VERSION ""

NS_ :

BS_:

BU_: EBS EMS

BO_ 2566742014 DM41: 22 Vector__XXX
 SG_ SPN_High4 : 133|3@1+ (1,0) [0|7] "" Vector__XXX
 SG_ SPN_High3 : 101|3@1+ (1,0) [0|7] "" Vector__XXX
 SG_ SPN_High5 : 165|3@1+ (1,0) [0|7] "" Vector__XXX
 SG_ SPN_High2 : 69|3@1+ (1,0) [0|7] "" Vector__XXX
 SG_ SPN_High1 : 37|3@1+ (1,0) [0|7] "" Vector__XXX
 SG_ SpnConversionMethod1 : 47|1@1+ (1,0) [0|1] "" Vector__XXX
 SG_ SpnConversionMethod5 : 175|1@1+ (1,0) [0|1] "" Vector__XXX
 SG_ SpnConversionMethod4 : 143|1@1+ (1,0) [0|1] "" Vector__XXX
 SG_ SpnConversionMethod3 : 111|1@1+ (1,0) [0|1] "" Vector__XXX
 SG_ SpnConversionMethod2 : 79|1@1+ (1,0) [0|1] "" Vector__XXX
 SG_ OccurenceCount5 : 168|7@1+ (1,0) [0|127] "" Vector__XXX
 SG_ OccurenceCount4 : 136|7@1+ (1,0) [0|127] "" Vector__XXX
 SG_ OccurenceCount3 : 104|7@1+ (1,0) [0|127] "" Vector__XXX
 SG_ OccurenceCount2 : 72|7@1+ (1,0) [0|127] "" Vector__XXX
 SG_ OccurenceCount1 : 40|7@1+ (1,0) [0|127] "" Vector__XXX
 SG_ FMI5 : 160|5@1+ (1,0) [0|31] "" Vector__XXX
 SG_ FMI4 : 128|5@1+ (1,0) [0|31] "" Vector__XXX
 SG_ FMI3 : 96|5@1+ (1,0) [0|31] "" Vector__XXX
 SG_ FMI2 : 64|5@1+ (1,0) [0|31] "" Vector__XXX
 SG_ FMI1 : 32|5@1+ (1,0) [0|31] "" Vector__XXX
 SG_ FlashRedStopLamp : 12|2@1+ (1,0) [0|3] "" Vector__XXX
 SG_ FlashProtectLamp : 8|2@1+ (1,0) [0|3] "" Vector__XXX
 SG_ FlashMalfuncIndicatorLamp : 14|2@1+ (1,0) [0|3] "" Vector__XXX
 SG_ FlashAmberWarningLamp : 10|2@1+ (1,0) [0|3] "" Vector__XXX
 SG_ MalfunctionIndLampStatus : 6|2@1+ (1,0) [0|3] "" Vector__XXX
 SG_ AmberWarningLampStatus : 2|2@1+ (1,0) [0|3] "" Vector__XXX
 SG_ RedStopLampState : 4|2@1+ (1,0) [0|3] "" Vector__XXX
 SG_ ProtectLampStatus : 0|2@1+ (1,0) [0|3] "" Vector__XXX
 SG_ SPN5 : 144|16@1+ (1,0) [0|524287] "" Vector__XXX
 SG_ SPN4 : 112|16@1+ (1,0) [0|524287] "" Vector__XXX
 SG_ SPN3 : 80|16@1+ (1,0) [0|524287] "" Vector__XXX
 SG_ SPN2 : 48|16@1+ (1,0) [0|524287] "" Vector__XXX
 SG_ SPN1 : 16|16@1+ (1,0) [0|524287] "" Vector__XXX

BO_ 2566742270 DM40: 20 Vector__XXX
 SG_ FailureSpecificB1Counter4 : 144|16@1+ (0.1,0) [0|6425.5] "hr" Vector__XXX
 SG_ FailureSpecificB1Counter3 : 104|16@1+ (0.1,0) [0|6425.5] "hr" Vector__XXX
 SG_ FailureSpecificB1Counter2 : 64|16@1+ (0.1,0) [0|6425.5] "hr" Vector__XXX
 SG_ SPN4_High : 141|3@1+ (1,0) [0|7] "" Vector__XXX
 SG_ SPN3_High : 101|3@1+ (1,0) [0|7] "" Vector__XXX
 SG_ SPN2_High : 61|3@1+ (1,0) [0|7] "" Vector__XXX
 SG_ SPN4 : 120|16@1+ (1,0) [0|65536] "" Vector__XXX
 SG_ SPN3 : 80|16@1+ (1,0) [0|65536] "" Vector__XXX
 SG_ SPN2 : 40|16@1+ (1,0) [0|65536] "" Vector__XXX
 SG_ FMI4 : 136|5@1+ (1,0) [0|0] "" Vector__XXX
 SG_ FMI3 : 96|5@1+ (1,0) [0|0] "" Vector__XXX
 SG_ FMI2 : 56|5@1+ (1,0) [0|0] "" Vector__XXX
 SG_ SPN1 : 0|16@1+ (1,0) [0|65536] "" Vector__XXX
 SG_ SPN1_High : 21|3@1+ (1,0) [0|7] "" Vector__XXX
 SG_ FMI1 : 16|5@1+ (1,0) [0|0] "" Vector__XXX
 SG_ FailureSpecificB1Counter1 : 24|16@1+ (0.1,0) [0|6425.5] "hr" Vector__XXX

BO_ 2566742526 DM39: 8 Vector__XXX
 SG_ SysGreatestB1Counter : 32|16@1+ (0.1,0) [0|6425.5] "hr" Vector__XXX
 SG_ SysCumulativeContinuousMITime : 0|32@1+ (0.05,0) [0|210554060.75] "hr" Vector__XXX

BO_ 2566742782 DM38: 8 Vector__XXX
 SG_ RegulationDescription : 0|8@1+ (1,0) [0|255] "" Vector__XXX

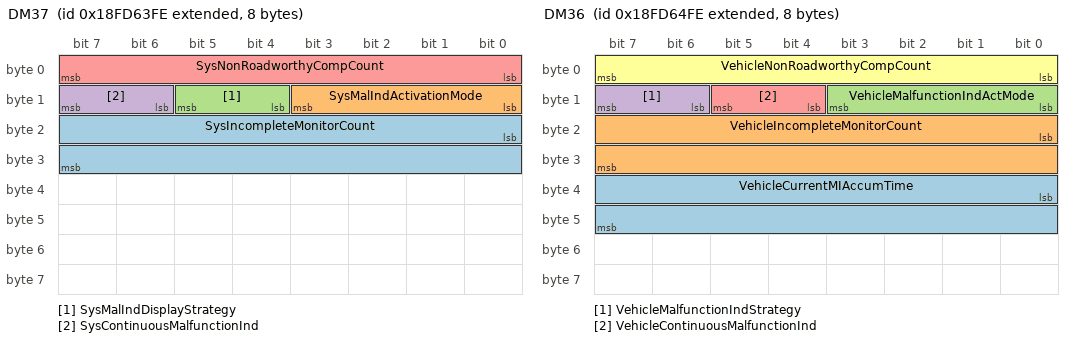
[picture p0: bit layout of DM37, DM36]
BO_ 2566743038 DM37: 8 Vector__XXX
 SG_ SysIncompleteMonitorCount : 16|16@1+ (1,0) [0|64512] "" Vector__XXX
 SG_ SysMalIndActivationMode : 8|4@1+ (1,0) [0|15] "" Vector__XXX
 SG_ SysMalIndDisplayStrategy : 12|2@1+ (1,0) [0|3] "" Vector__XXX
 SG_ SysContinuousMalfunctionInd : 14|2@1+ (1,0) [0|3] "" Vector__XXX
 SG_ SysNonRoadworthyCompCount : 0|8@1+ (1,0) [0|250] "" Vector__XXX

BO_ 2566743294 DM36: 8 Vector__XXX
 SG_ VehicleCurrentMIAccumTime : 32|16@1+ (1,0) [0|64255] "min" Vector__XXX
 SG_ VehicleIncompleteMonitorCount : 16|16@1+ (1,0) [0|64255] "" Vector__XXX
 SG_ VehicleMalfunctionIndActMode : 8|4@1+ (1,0) [0|15] "" Vector__XXX
 SG_ VehicleMalfunctionIndStrategy : 14|2@1+ (1,0) [0|3] "" Vector__XXX
 SG_ VehicleContinuousMalfunctionInd : 12|2@1+ (1,0) [0|3] "" Vector__XXX
 SG_ VehicleNonRoadworthyCompCount : 0|8@1+ (1,0) [0|250] "" Vector__XXX

BO_ 2560622334 DM35: 22 Vector__XXX
 SG_ SPN_High4 : 133|3@1+ (1,0) [0|7] "" Vector__XXX
 SG_ SPN_High3 : 101|3@1+ (1,0) [0|7] "" Vector__XXX
 SG_ SPN_High5 : 165|3@1+ (1,0) [0|7] "" Vector__XXX
 SG_ SPN_High2 : 69|3@1+ (1,0) [0|7] "" Vector__XXX
 SG_ SPN_High1 : 37|3@1+ (1,0) [0|7] "" Vector__XXX
 SG_ SpnConversionMethod1 : 47|1@1+ (1,0) [0|1] "" Vector__XXX
 SG_ SpnConversionMethod5 : 175|1@1+ (1,0) [0|1] "" Vector__XXX
 SG_ SpnConversionMethod4 : 143|1@1+ (1,0) [0|1] "" Vector__XXX
 SG_ SpnConversionMethod3 : 111|1@1+ (1,0) [0|1] "" Vector__XXX
 SG_ SpnConversionMethod2 : 79|1@1+ (1,0) [0|1] "" Vector__XXX
 SG_ OccurenceCount5 : 168|7@1+ (1,0) [0|127] "" Vector__XXX
 SG_ OccurenceCount4 : 136|7@1+ (1,0) [0|127] "" Vector__XXX
 SG_ OccurenceCount3 : 104|7@1+ (1,0) [0|127] "" Vector__XXX
 SG_ OccurenceCount2 : 72|7@1+ (1,0) [0|127] "" Vector__XXX
 SG_ OccurenceCount1 : 40|7@1+ (1,0) [0|127] "" Vector__XXX
 SG_ FMI5 : 160|5@1+ (1,0) [0|31] "" Vector__XXX
 SG_ FMI4 : 128|5@1+ (1,0) [0|31] "" Vector__XXX
 SG_ FMI3 : 96|5@1+ (1,0) [0|31] "" Vector__XXX
 SG_ FMI2 : 64|5@1+ (1,0) [0|31] "" Vector__XXX
 SG_ FMI1 : 32|5@1+ (1,0) [0|31] "" Vector__XXX
 SG_ FlashRedStopLamp : 12|2@1+ (1,0) [0|3] "" Vector__XXX
 SG_ FlashProtectLamp : 8|2@1+ (1,0) [0|3] "" Vector__XXX
 SG_ FlashMalfuncIndicatorLamp : 14|2@1+ (1,0) [0|3] "" Vector__XXX
 SG_ FlashAmberWarningLamp : 10|2@1+ (1,0) [0|3] "" Vector__XXX
 SG_ MalfunctionIndLampStatus : 6|2@1+ (1,0) [0|3] "" Vector__XXX
 SG_ AmberWarningLampStatus : 2|2@1+ (1,0) [0|3] "" Vector__XXX
 SG_ RedStopLampState : 4|2@1+ (1,0) [0|3] "" Vector__XXX
 SG_ ProtectLampStatus : 0|2@1+ (1,0) [0|3] "" Vector__XXX
 SG_ SPN5 : 144|16@1+ (1,0) [0|524287] "" Vector__XXX
 SG_ SPN4 : 112|16@1+ (1,0) [0|524287] "" Vector__XXX
 SG_ SPN3 : 80|16@1+ (1,0) [0|524287] "" Vector__XXX
 SG_ SPN2 : 48|16@1+ (1,0) [0|524287] "" Vector__XXX
 SG_ SPN1 : 16|16@1+ (1,0) [0|524287] "" Vector__XXX

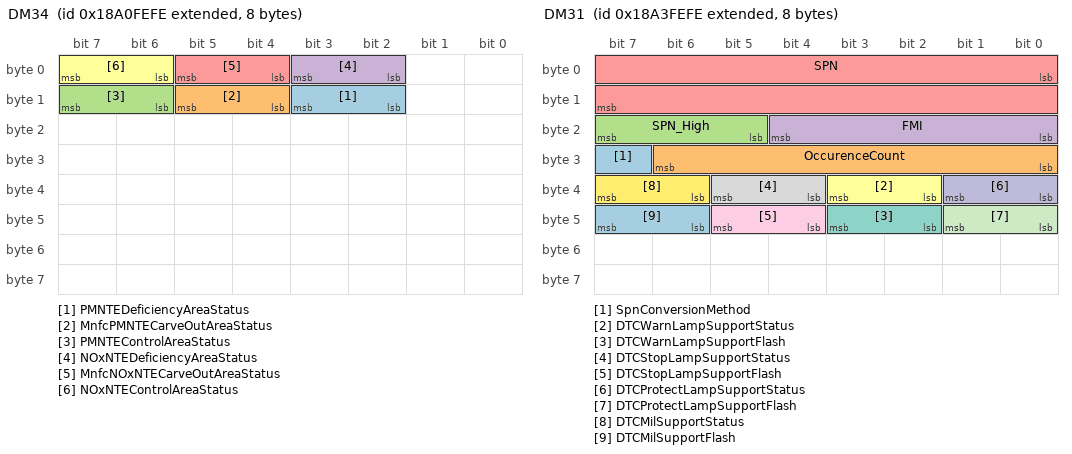
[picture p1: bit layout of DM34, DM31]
BO_ 2560687870 DM34: 8 Vector__XXX
 SG_ PMNTEDeficiencyAreaStatus : 10|2@1+ (1,0) [0|3] "" Vector__XXX
 SG_ MnfcPMNTECarveOutAreaStatus : 12|2@1+ (1,0) [0|3] "" Vector__XXX
 SG_ PMNTEControlAreaStatus : 14|2@1+ (1,0) [0|3] "" Vector__XXX
 SG_ NOxNTEDeficiencyAreaStatus : 2|2@1+ (1,0) [0|3] "" Vector__XXX
 SG_ MnfcNOxNTECarveOutAreaStatus : 4|2@1+ (1,0) [0|3] "" Vector__XXX
 SG_ NOxNTEControlAreaStatus : 6|2@1+ (1,0) [0|3] "" Vector__XXX

BO_ 2292317950 DM33: 9 Vector__XXX
 SG_ AECDEngineHours1Timer2 : 40|32@1+ (1,0) [0|4294967295] "min" Vector__XXX
 SG_ AECDEngineHours1Timer1 : 8|32@1+ (1,0) [0|4294967295] "min" Vector__XXX
 SG_ AECDNumber1 : 0|8@1+ (1,0) [0|250] "" Vector__XXX

BO_ 2560818942 DM32: 32 Vector__XXX
 SG_ DTCTotalPreviouslyActiveTime4 : 232|16@1+ (0.2,0) [0|12851] "hr" Vector__XXX
 SG_ DTCTotalPreviouslyActiveTime3 : 168|16@1+ (0.2,0) [0|12851] "hr" Vector__XXX
 SG_ DTCTotalPreviouslyActiveTime2 : 104|16@1+ (0.2,0) [0|12851] "hr" Vector__XXX
 SG_ DTCTotalActiveTime4 : 216|16@1+ (0.2,0) [0|12851] "hr" Vector__XXX
 SG_ DTCTotalActiveTime3 : 152|16@1+ (0.2,0) [0|12851] "hr" Vector__XXX
 SG_ DTCTotalActiveTime2 : 88|16@1+ (0.2,0) [0|12851] "hr" Vector__XXX
 SG_ DTCTimeUntilDerate4 : 248|8@1+ (0.25,0) [0|62.5] "hr" Vector__XXX
 SG_ DTCTimeUntilDerate3 : 184|8@1+ (0.25,0) [0|62.5] "hr" Vector__XXX
 SG_ DTCTimeUntilDerate2 : 120|8@1+ (0.25,0) [0|62.5] "hr" Vector__XXX
 SG_ SPN4_High : 213|3@1+ (1,0) [0|7] "" Vector__XXX
 SG_ SPN3_High : 149|3@1+ (1,0) [0|7] "" Vector__XXX
 SG_ SPN2_High : 85|3@1+ (1,0) [0|7] "" Vector__XXX
 SG_ SPN1_High : 21|3@1+ (1,0) [0|7] "" Vector__XXX
 SG_ SPN4 : 192|16@1+ (1,0) [0|65536] "" Vector__XXX
 SG_ SPN3 : 128|16@1+ (1,0) [0|65536] "" Vector__XXX
 SG_ SPN2 : 64|16@1+ (1,0) [0|65536] "" Vector__XXX
 SG_ FMI4 : 208|5@1+ (1,0) [0|0] "" Vector__XXX
 SG_ FMI3 : 144|5@1+ (1,0) [0|0] "" Vector__XXX
 SG_ FMI2 : 80|5@1+ (1,0) [0|0] "" Vector__XXX
 SG_ SPN1 : 0|16@1+ (1,0) [0|65536] "" Vector__XXX
 SG_ FMI1 : 16|5@1+ (1,0) [0|0] "" Vector__XXX
 SG_ DTCTimeUntilDerate1 : 56|8@1+ (0.25,0) [0|62.5] "hr" Vector__XXX
 SG_ DTCTotalPreviouslyActiveTime1 : 40|16@1+ (0.2,0) [0|12851] "hr" Vector__XXX
 SG_ DTCTotalActiveTime1 : 24|16@1+ (0.2,0) [0|12851] "hr" Vector__XXX

BO_ 2560884478 DM31: 8 Vector__XXX
 SG_ SpnConversionMethod : 31|1@1+ (1,0) [0|1] "" Vector__XXX
 SG_ OccurenceCount : 24|7@1+ (1,0) [0|127] "" Vector__XXX
 SG_ SPN_High : 21|3@1+ (1,0) [0|7] "" Vector__XXX
 SG_ FMI : 16|5@1+ (1,0) [0|31] "" Vector__XXX
 SG_ SPN : 0|16@1+ (1,0) [0|524287] "" Vector__XXX
 SG_ DTCWarnLampSupportStatus : 34|2@1+ (1,0) [0|3] "" Vector__XXX
 SG_ DTCWarnLampSupportFlash : 42|2@1+ (1,0) [0|3] "" Vector__XXX
 SG_ DTCStopLampSupportStatus : 36|2@1+ (1,0) [0|3] "" Vector__XXX
 SG_ DTCStopLampSupportFlash : 44|2@1+ (1,0) [0|3] "" Vector__XXX
 SG_ DTCProtectLampSupportStatus : 32|2@1+ (1,0) [0|3] "" Vector__XXX
 SG_ DTCProtectLampSupportFlash : 40|2@1+ (1,0) [0|3] "" Vector__XXX
 SG_ DTCMilSupportStatus : 38|2@1+ (1,0) [0|3] "" Vector__XXX
 SG_ DTCMilSupportFlash : 46|2@1+ (1,0) [0|3] "" Vector__XXX

BO_ 2560950014 DM30: 48 Vector__XXX
 SG_ TestLimitMinimum4 : 368|16@1+ (1,0) [0|64255] "" Vector__XXX
 SG_ TestLimitMinimum3 : 272|16@1+ (1,0) [0|64255] "" Vector__XXX
 SG_ TestLimitMinimum2 : 176|16@1+ (1,0) [0|64255] "" Vector__XXX
 SG_ TestLimitMaximum4 : 352|16@1+ (1,0) [0|64255] "" Vector__XXX
 SG_ TestLimitMaximum3 : 256|16@1+ (1,0) [0|64255] "" Vector__XXX
 SG_ TestLimitMaximum2 : 160|16@1+ (1,0) [0|64255] "" Vector__XXX
 SG_ TestValue4 : 336|16@1+ (1,0) [0|64255] "" Vector__XXX
 SG_ TestValue3 : 240|16@1+ (1,0) [0|64255] "" Vector__XXX
 SG_ TestValue2 : 144|16@1+ (1,0) [0|64255] "" Vector__XXX
 SG_ SlotId4 : 320|16@1+ (1,0) [0|64255] "" Vector__XXX
 SG_ SlotId3 : 224|16@1+ (1,0) [0|64255] "" Vector__XXX
 SG_ SlotId2 : 128|16@1+ (1,0) [0|64255] "" Vector__XXX
 SG_ TestIdentifier4 : 288|8@1+ (1,0) [0|255] "" Vector__XXX
 SG_ TestIdentifier3 : 192|8@1+ (1,0) [0|255] "" Vector__XXX
 SG_ TestIdentifier2 : 96|8@1+ (1,0) [0|255] "" Vector__XXX
 SG_ SPN1_High : 29|3@1+ (1,0) [0|7] "" Vector__XXX
 SG_ SPN2_High : 125|3@1+ (1,0) [0|7] "" Vector__XXX
 SG_ SPN3_High : 221|3@1+ (1,0) [0|7] "" Vector__XXX
 SG_ SPN4_High : 317|3@1+ (1,0) [0|7] "" Vector__XXX
 SG_ FMI2 : 120|5@1+ (1,0) [0|0] "" Vector__XXX
 SG_ FMI3 : 216|5@1+ (1,0) [0|0] "" Vector__XXX
 SG_ FMI4 : 312|5@1+ (1,0) [0|0] "" Vector__XXX
 SG_ FMI1 : 24|5@1+ (1,0) [0|0] "" Vector__XXX
 SG_ SPN2 : 104|16@1+ (1,0) [0|65536] "" Vector__XXX
 SG_ SPN3 : 200|16@1+ (1,0) [0|65536] "" Vector__XXX
 SG_ SPN4 : 296|16@1+ (1,0) [0|65536] "" Vector__XXX
 SG_ TestLimitMinimum1 : 80|16@1+ (1,0) [0|64255] "" Vector__XXX
 SG_ SPN1 : 8|16@1+ (1,0) [0|65536] "" Vector__XXX
 SG_ TestLimitMaximum1 : 64|16@1+ (1,0) [0|64255] "" Vector__XXX
 SG_ TestValue1 : 48|16@1+ (1,0) [0|64255] "" Vector__XXX
 SG_ SlotId1 : 32|16@1+ (1,0) [0|64255] "" Vector__XXX
 SG_ TestIdentifier1 : 0|8@1+ (1,0) [0|255] "" Vector__XXX

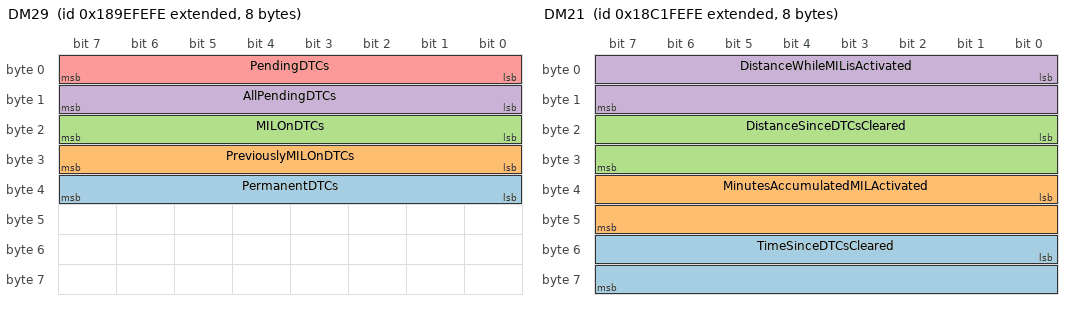
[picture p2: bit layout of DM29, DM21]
BO_ 2560556798 DM29: 8 Vector__XXX
 SG_ PermanentDTCs : 32|8@1+ (1,0) [0|255] "" Vector__XXX
 SG_ PreviouslyMILOnDTCs : 24|8@1+ (1,0) [0|255] "" Vector__XXX
 SG_ MILOnDTCs : 16|8@1+ (1,0) [0|255] "" Vector__XXX
 SG_ AllPendingDTCs : 8|8@1+ (1,0) [0|255] "" Vector__XXX
 SG_ PendingDTCs : 0|8@1+ (1,0) [0|255] "" Vector__XXX

BO_ 2566750462 DM28: 22 Vector__XXX
 SG_ SPN_High4 : 133|3@1+ (1,0) [0|7] "" Vector__XXX
 SG_ SPN_High3 : 101|3@1+ (1,0) [0|7] "" Vector__XXX
 SG_ SPN_High5 : 165|3@1+ (1,0) [0|7] "" Vector__XXX
 SG_ SPN_High2 : 69|3@1+ (1,0) [0|7] "" Vector__XXX
 SG_ SPN_High1 : 37|3@1+ (1,0) [0|7] "" Vector__XXX
 SG_ SpnConversionMethod1 : 47|1@1+ (1,0) [0|1] "" Vector__XXX
 SG_ SpnConversionMethod5 : 175|1@1+ (1,0) [0|1] "" Vector__XXX
 SG_ SpnConversionMethod4 : 143|1@1+ (1,0) [0|1] "" Vector__XXX
 SG_ SpnConversionMethod3 : 111|1@1+ (1,0) [0|1] "" Vector__XXX
 SG_ SpnConversionMethod2 : 79|1@1+ (1,0) [0|1] "" Vector__XXX
 SG_ OccurenceCount5 : 168|7@1+ (1,0) [0|127] "" Vector__XXX
 SG_ OccurenceCount4 : 136|7@1+ (1,0) [0|127] "" Vector__XXX
 SG_ OccurenceCount3 : 104|7@1+ (1,0) [0|127] "" Vector__XXX
 SG_ OccurenceCount2 : 72|7@1+ (1,0) [0|127] "" Vector__XXX
 SG_ OccurenceCount1 : 40|7@1+ (1,0) [0|127] "" Vector__XXX
 SG_ FMI5 : 160|5@1+ (1,0) [0|31] "" Vector__XXX
 SG_ FMI4 : 128|5@1+ (1,0) [0|31] "" Vector__XXX
 SG_ FMI3 : 96|5@1+ (1,0) [0|31] "" Vector__XXX
 SG_ FMI2 : 64|5@1+ (1,0) [0|31] "" Vector__XXX
 SG_ FMI1 : 32|5@1+ (1,0) [0|31] "" Vector__XXX
 SG_ FlashRedStopLamp : 12|2@1+ (1,0) [0|3] "" Vector__XXX
 SG_ FlashProtectLamp : 8|2@1+ (1,0) [0|3] "" Vector__XXX
 SG_ FlashMalfuncIndicatorLamp : 14|2@1+ (1,0) [0|3] "" Vector__XXX
 SG_ FlashAmberWarningLamp : 10|2@1+ (1,0) [0|3] "" Vector__XXX
 SG_ MalfunctionIndLampStatus : 6|2@1+ (1,0) [0|3] "" Vector__XXX
 SG_ AmberWarningLampStatus : 2|2@1+ (1,0) [0|3] "" Vector__XXX
 SG_ RedStopLampState : 4|2@1+ (1,0) [0|3] "" Vector__XXX
 SG_ ProtectLampStatus : 0|2@1+ (1,0) [0|3] "" Vector__XXX
 SG_ SPN5 : 144|16@1+ (1,0) [0|524287] "" Vector__XXX
 SG_ SPN4 : 112|16@1+ (1,0) [0|524287] "" Vector__XXX
 SG_ SPN3 : 80|16@1+ (1,0) [0|524287] "" Vector__XXX
 SG_ SPN2 : 48|16@1+ (1,0) [0|524287] "" Vector__XXX
 SG_ SPN1 : 16|16@1+ (1,0) [0|524287] "" Vector__XXX

BO_ 2566750974 DM27: 22 Vector__XXX
 SG_ SPN_High4 : 133|3@1+ (1,0) [0|7] "" Vector__XXX
 SG_ SPN_High3 : 101|3@1+ (1,0) [0|7] "" Vector__XXX
 SG_ SPN_High5 : 165|3@1+ (1,0) [0|7] "" Vector__XXX
 SG_ SPN_High2 : 69|3@1+ (1,0) [0|7] "" Vector__XXX
 SG_ SPN_High1 : 37|3@1+ (1,0) [0|7] "" Vector__XXX
 SG_ SpnConversionMethod1 : 47|1@1+ (1,0) [0|1] "" Vector__XXX
 SG_ SpnConversionMethod5 : 175|1@1+ (1,0) [0|1] "" Vector__XXX
 SG_ SpnConversionMethod4 : 143|1@1+ (1,0) [0|1] "" Vector__XXX
 SG_ SpnConversionMethod3 : 111|1@1+ (1,0) [0|1] "" Vector__XXX
 SG_ SpnConversionMethod2 : 79|1@1+ (1,0) [0|1] "" Vector__XXX
 SG_ OccurenceCount5 : 168|7@1+ (1,0) [0|127] "" Vector__XXX
 SG_ OccurenceCount4 : 136|7@1+ (1,0) [0|127] "" Vector__XXX
 SG_ OccurenceCount3 : 104|7@1+ (1,0) [0|127] "" Vector__XXX
 SG_ OccurenceCount2 : 72|7@1+ (1,0) [0|127] "" Vector__XXX
 SG_ OccurenceCount1 : 40|7@1+ (1,0) [0|127] "" Vector__XXX
 SG_ FMI5 : 160|5@1+ (1,0) [0|31] "" Vector__XXX
 SG_ FMI4 : 128|5@1+ (1,0) [0|31] "" Vector__XXX
 SG_ FMI3 : 96|5@1+ (1,0) [0|31] "" Vector__XXX
 SG_ FMI2 : 64|5@1+ (1,0) [0|31] "" Vector__XXX
 SG_ FMI1 : 32|5@1+ (1,0) [0|31] "" Vector__XXX
 SG_ FlashRedStopLamp : 12|2@1+ (1,0) [0|3] "" Vector__XXX
 SG_ FlashProtectLamp : 8|2@1+ (1,0) [0|3] "" Vector__XXX
 SG_ FlashMalfuncIndicatorLamp : 14|2@1+ (1,0) [0|3] "" Vector__XXX
 SG_ FlashAmberWarningLamp : 10|2@1+ (1,0) [0|3] "" Vector__XXX
 SG_ MalfunctionIndLampStatus : 6|2@1+ (1,0) [0|3] "" Vector__XXX
 SG_ AmberWarningLampStatus : 2|2@1+ (1,0) [0|3] "" Vector__XXX
 SG_ RedStopLampState : 4|2@1+ (1,0) [0|3] "" Vector__XXX
 SG_ ProtectLampStatus : 0|2@1+ (1,0) [0|3] "" Vector__XXX
 SG_ SPN5 : 144|16@1+ (1,0) [0|524287] "" Vector__XXX
 SG_ SPN4 : 112|16@1+ (1,0) [0|524287] "" Vector__XXX
 SG_ SPN3 : 80|16@1+ (1,0) [0|524287] "" Vector__XXX
 SG_ SPN2 : 48|16@1+ (1,0) [0|524287] "" Vector__XXX
 SG_ SPN1 : 16|16@1+ (1,0) [0|524287] "" Vector__XXX

BO_ 2566764798 DM26: 8 Vector__XXX
 SG_ NOxConvertingCatAdsorberEnabled : 43|1@1+ (1,0) [0|1] "" Vector__XXX
 SG_ BoostPressureCtrlSystemCompleted : 57|1@1+ (1,0) [0|1] "" Vector__XXX
 SG_ NMHCConvertingCatalystCompleted : 60|1@1+ (1,0) [0|1] "" Vector__XXX
 SG_ NMHCConvertingCatalystEnabled : 44|1@1+ (1,0) [0|1] "" Vector__XXX
 SG_ NOxConvertingCatalstAdsrbrCmpltd : 59|1@1+ (1,0) [0|1] "" Vector__XXX
 SG_ DieselParticulateFilterCompleted : 58|1@1+ (1,0) [0|1] "" Vector__XXX
 SG_ DieselParticulateFilterEnabled : 42|1@1+ (1,0) [0|1] "" Vector__XXX
 SG_ BoostPressureControlSystemEnable : 41|1@1+ (1,0) [0|1] "" Vector__XXX
 SG_ MisfireMonitoringComplete : 28|1@1+ (1,0) [0|1] "" Vector__XXX
 SG_ MisfireMonitoringEnabled : 24|1@1+ (1,0) [0|0] "" Vector__XXX
 SG_ FuelSystemMonitoringEnabled : 25|1@1+ (1,0) [0|1] "" Vector__XXX
 SG_ ComprehensiveComptMonComplete : 30|1@1+ (1,0) [0|1] "" Vector__XXX
 SG_ ComprehensiveCompMonEnabled : 26|1@1+ (1,0) [0|1] "" Vector__XXX
 SG_ SecondAirSystemMonComplete : 51|1@1+ (1,0) [0|1] "" Vector__XXX
 SG_ SecondAirSystemMonEnabled : 35|1@1+ (1,0) [0|1] "" Vector__XXX
 SG_ OxygenSensorMonComplete : 53|1@1+ (1,0) [0|1] "" Vector__XXX
 SG_ OxygenSensorMonEnabled : 37|1@1+ (1,0) [0|1] "" Vector__XXX
 SG_ OxygenSensorHeaterMonComplete : 54|1@1+ (1,0) [0|1] "" Vector__XXX
 SG_ OxygenSensorHeaterMonEnabled : 38|1@1+ (1,0) [0|1] "" Vector__XXX
 SG_ HeatedCatalystMonComplete : 49|1@1+ (1,0) [0|1] "" Vector__XXX
 SG_ HeatedCatalystMonEnabled : 33|1@1+ (1,0) [0|1] "" Vector__XXX
 SG_ EvaporativeSystemMonComplete : 50|1@1+ (1,0) [0|1] "" Vector__XXX
 SG_ EvaporativeSystemMonEnabled : 34|1@1+ (1,0) [0|1] "" Vector__XXX
 SG_ EGRSystemMonitoringComplete : 55|1@1+ (1,0) [0|1] "" Vector__XXX
 SG_ EGRSystemMonitoringEnabled : 39|1@1+ (1,0) [0|1] "" Vector__XXX
 SG_ ColdStartAidSystemMonComplete : 56|1@1+ (1,0) [0|1] "" Vector__XXX
 SG_ ColdStartAidSystemMonEnabled : 40|1@1+ (1,0) [0|1] "" Vector__XXX
 SG_ CatalystMonComplete : 48|1@1+ (1,0) [0|1] "" Vector__XXX
 SG_ CatalystMonEnabled : 32|1@1+ (1,0) [0|1] "" Vector__XXX
 SG_ ACSystemRefrigerantMonComplete : 52|1@1+ (1,0) [0|1] "" Vector__XXX
 SG_ ACSystemRefrigerantMonEnabled : 36|1@1+ (1,0) [0|1] "" Vector__XXX
 SG_ FuelSystemMonitoringComplete : 29|1@1+ (1,0) [0|1] "" Vector__XXX
 SG_ NumOfWarmUpsSinceDTCsCleared : 16|8@1+ (1,0) [0|250] "" Vector__XXX
 SG_ TimeSinceEngineStart : 0|16@1+ (1,0) [0|64255] "s" Vector__XXX

BO_ 2566764542 DM25: 13 Vector__XXX
 SG_ SpnConversionMethod : 39|1@1+ (1,0) [0|1] "" Vector__XXX
 SG_ OccurenceCount : 32|7@1+ (1,0) [0|127] "" Vector__XXX
 SG_ SPN_High : 29|3@1+ (1,0) [0|7] "" Vector__XXX
 SG_ FMI : 24|5@1+ (1,0) [0|31] "" Vector__XXX
 SG_ ExpandedFreezeFrameLength : 0|8@1+ (1,0) [0|250] "bytes" Vector__XXX
 SG_ SPN : 8|16@1+ (1,0) [0|524287] "" Vector__XXX

BO_ 2566764286 DM24: 12 Vector__XXX
 SG_ SPNSupported1High : 21|3@1+ (1,0) [0|7] "" Vector__XXX
 SG_ SPNSupportTypeSTR3 : 82|1@1+ (1,0) [0|1] "" Vector__XXX
 SG_ SPNSupportTypeSTR2 : 50|1@1+ (1,0) [0|1] "" Vector__XXX
 SG_ SPNSupportTypeEFF3 : 80|1@1+ (1,0) [0|1] "" Vector__XXX
 SG_ SPNSupportTypeEFF2 : 48|1@1+ (1,0) [0|1] "" Vector__XXX
 SG_ SPNSupportTypeDS3 : 81|1@1+ (1,0) [0|1] "" Vector__XXX
 SG_ SPNSupportTypeDS2 : 49|1@1+ (1,0) [0|1] "" Vector__XXX
 SG_ SPNSupported3High : 85|3@1+ (1,0) [0|7] "" Vector__XXX
 SG_ SPNSupported2High : 53|3@1+ (1,0) [0|7] "" Vector__XXX
 SG_ SPNSupported3 : 64|16@1+ (1,0) [0|65535] "" Vector__XXX
 SG_ SPNSupported2 : 32|16@1+ (1,0) [0|65535] "" Vector__XXX
 SG_ SPNDataLength3 : 88|8@1+ (1,0) [0|240] "" Vector__XXX
 SG_ SPNSupportTypeSTR1 : 18|1@1+ (1,0) [0|1] "" Vector__XXX
 SG_ SPNSupportTypeDS1 : 17|1@1+ (1,0) [0|1] "" Vector__XXX
 SG_ SPNSupportTypeEFF1 : 16|1@1+ (1,0) [0|1] "" Vector__XXX
 SG_ SPNDataLength2 : 56|8@1+ (1,0) [0|240] "" Vector__XXX
 SG_ SPNDataLength1 : 24|8@1+ (1,0) [0|250] "" Vector__XXX
 SG_ SPNSupported1 : 0|16@1+ (1,0) [0|524287] "" Vector__XXX

BO_ 2566764030 DM23: 22 Vector__XXX
 SG_ SPN_High4 : 133|3@1+ (1,0) [0|7] "" Vector__XXX
 SG_ SPN_High3 : 101|3@1+ (1,0) [0|7] "" Vector__XXX
 SG_ SPN_High5 : 165|3@1+ (1,0) [0|7] "" Vector__XXX
 SG_ SPN_High2 : 69|3@1+ (1,0) [0|7] "" Vector__XXX
 SG_ SPN_High1 : 37|3@1+ (1,0) [0|7] "" Vector__XXX
 SG_ SpnConversionMethod1 : 47|1@1+ (1,0) [0|1] "" Vector__XXX
 SG_ SpnConversionMethod5 : 175|1@1+ (1,0) [0|1] "" Vector__XXX
 SG_ SpnConversionMethod4 : 143|1@1+ (1,0) [0|1] "" Vector__XXX
 SG_ SpnConversionMethod3 : 111|1@1+ (1,0) [0|1] "" Vector__XXX
 SG_ SpnConversionMethod2 : 79|1@1+ (1,0) [0|1] "" Vector__XXX
 SG_ OccurenceCount5 : 168|7@1+ (1,0) [0|127] "" Vector__XXX
 SG_ OccurenceCount4 : 136|7@1+ (1,0) [0|127] "" Vector__XXX
 SG_ OccurenceCount3 : 104|7@1+ (1,0) [0|127] "" Vector__XXX
 SG_ OccurenceCount2 : 72|7@1+ (1,0) [0|127] "" Vector__XXX
 SG_ OccurenceCount1 : 40|7@1+ (1,0) [0|127] "" Vector__XXX
 SG_ FMI5 : 160|5@1+ (1,0) [0|31] "" Vector__XXX
 SG_ FMI4 : 128|5@1+ (1,0) [0|31] "" Vector__XXX
 SG_ FMI3 : 96|5@1+ (1,0) [0|31] "" Vector__XXX
 SG_ FMI2 : 64|5@1+ (1,0) [0|31] "" Vector__XXX
 SG_ FMI1 : 32|5@1+ (1,0) [0|31] "" Vector__XXX
 SG_ FlashRedStopLamp : 12|2@1+ (1,0) [0|3] "" Vector__XXX
 SG_ FlashProtectLamp : 8|2@1+ (1,0) [0|3] "" Vector__XXX
 SG_ FlashMalfuncIndicatorLamp : 14|2@1+ (1,0) [0|3] "" Vector__XXX
 SG_ FlashAmberWarningLamp : 10|2@1+ (1,0) [0|3] "" Vector__XXX
 SG_ MalfunctionIndLampStatus : 6|2@1+ (1,0) [0|3] "" Vector__XXX
 SG_ AmberWarningLampStatus : 2|2@1+ (1,0) [0|3] "" Vector__XXX
 SG_ RedStopLampState : 4|2@1+ (1,0) [0|3] "" Vector__XXX
 SG_ ProtectLampStatus : 0|2@1+ (1,0) [0|3] "" Vector__XXX
 SG_ SPN5 : 144|16@1+ (1,0) [0|524287] "" Vector__XXX
 SG_ SPN4 : 112|16@1+ (1,0) [0|524287] "" Vector__XXX
 SG_ SPN3 : 80|16@1+ (1,0) [0|524287] "" Vector__XXX
 SG_ SPN2 : 48|16@1+ (1,0) [0|524287] "" Vector__XXX
 SG_ SPN1 : 16|16@1+ (1,0) [0|524287] "" Vector__XXX

BO_ 2562981630 DM22: 8 Vector__XXX
 SG_ SPN : 40|16@1+ (1,0) [0|524287] "" Vector__XXX
 SG_ ControlByte M : 0|8@1+ (1,0) [0|255] "" Vector__XXX
 SG_ CtrlByteSpecificIndicator m3 : 8|8@1+ (1,0) [0|255] "" Vector__XXX
 SG_ FMI : 56|5@1+ (1,0) [0|31] "" Vector__XXX
 SG_ SPN_High : 61|3@1+ (1,0) [0|7] "" Vector__XXX

BO_ 2562850558 DM21: 8 Vector__XXX
 SG_ TimeSinceDTCsCleared : 48|16@1+ (1,0) [0|64255] "min" Vector__XXX
 SG_ MinutesAccumulatedMILActivated : 32|16@1+ (1,0) [0|64255] "min" Vector__XXX
 SG_ DistanceSinceDTCsCleared : 16|16@1+ (1,0) [0|64255] "km" Vector__XXX
 SG_ DistanceWhileMILisActivated : 0|16@1+ (1,0) [0|64255] "km" Vector__XXX

BO_ 2562916094 DM20: 11 Vector__XXX
 SG_ ApplSysMonitorDenominator : 72|16@1+ (1,0) [0|65535] "" Vector__XXX
 SG_ ApplSysMonitorNumerator : 56|16@1+ (1,0) [0|65535] "" Vector__XXX
 SG_ SpnOfApplSysMonitor : 32|19@1+ (1,0) [0|65535] "" Vector__XXX
 SG_ OBDMonitoringCondEncountered : 16|16@1+ (1,0) [0|65535] "" Vector__XXX
 SG_ IgnitionCycleCounter : 0|16@1+ (1,0) [0|65535] "" Vector__XXX

BO_ 2564030206 DM19: 20 Vector__XXX
 SG_ CalibrationID4 : 128|32@1+ (1,0) [0|4294967295] "" Vector__XXX
 SG_ CalibrationID3 : 96|32@1+ (1,0) [0|4294967295] "" Vector__XXX
 SG_ CalibrationID2 : 64|32@1+ (1,0) [0|4294967295] "" Vector__XXX
 SG_ CalibrationID1 : 32|32@1+ (1,0) [0|255] "" Vector__XXX
 SG_ CalibrationVerificationNumber : 0|32@1+ (1,0) [0|4294967295] "" Vector__XXX

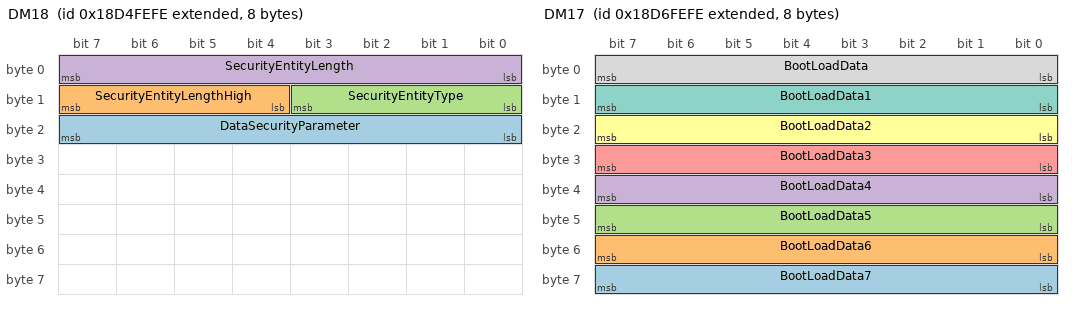
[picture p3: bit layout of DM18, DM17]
BO_ 2564095742 DM18: 8 Vector__XXX
 SG_ DataSecurityParameter : 16|8@1+ (1,0) [0|0] "" Vector__XXX
 SG_ SecurityEntityLengthHigh : 12|4@1+ (1,0) [0|255] "Byte" Vector__XXX
 SG_ SecurityEntityType : 8|4@1+ (1,0) [0|15] "" Vector__XXX
 SG_ SecurityEntityLength : 0|8@1+ (1,0) [0|4095] "" Vector__XXX

BO_ 2564226814 DM17: 8 Vector__XXX
 SG_ BootLoadData7 : 56|8@1+ (1,0) [0|255] "" Vector__XXX
 SG_ BootLoadData6 : 48|8@1+ (1,0) [0|255] "" Vector__XXX
 SG_ BootLoadData5 : 40|8@1+ (1,0) [0|255] "" Vector__XXX
 SG_ BootLoadData4 : 32|8@1+ (1,0) [0|255] "" Vector__XXX
 SG_ BootLoadData3 : 24|8@1+ (1,0) [0|255] "" Vector__XXX
 SG_ BootLoadData2 : 16|8@1+ (1,0) [0|255] "" Vector__XXX
 SG_ BootLoadData1 : 8|8@1+ (1,0) [0|255] "" Vector__XXX
 SG_ BootLoadData : 0|8@1+ (1,0) [0|0] "" Vector__XXX

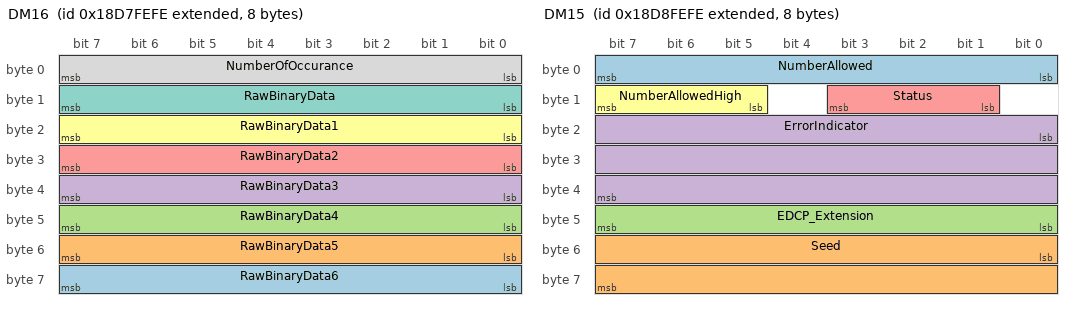
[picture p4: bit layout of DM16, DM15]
BO_ 2564292350 DM16: 8 Vector__XXX
 SG_ RawBinaryData6 : 56|8@1+ (1,0) [0|255] "" Vector__XXX
 SG_ RawBinaryData5 : 48|8@1+ (1,0) [0|255] "" Vector__XXX
 SG_ RawBinaryData4 : 40|8@1+ (1,0) [0|255] "" Vector__XXX
 SG_ RawBinaryData3 : 32|8@1+ (1,0) [0|255] "" Vector__XXX
 SG_ RawBinaryData2 : 24|8@1+ (1,0) [0|255] "" Vector__XXX
 SG_ RawBinaryData1 : 16|8@1+ (1,0) [0|255] "" Vector__XXX
 SG_ RawBinaryData : 8|8@1+ (1,0) [0|0] "" Vector__XXX
 SG_ NumberOfOccurance : 0|8@1+ (1,0) [0|255] "" Vector__XXX

BO_ 2564357886 DM15: 8 Vector__XXX
 SG_ NumberAllowed : 0|8@1+ (1,0) [0|2047] "" Vector__XXX
 SG_ Seed : 48|16@1+ (1,0) [0|65535] "" Vector__XXX
 SG_ EDCP_Extension : 40|8@1+ (1,0) [0|255] "" Vector__XXX
 SG_ ErrorIndicator : 16|24@1+ (1,0) [0|16777215] "" Vector__XXX
 SG_ Status : 9|3@1+ (1,0) [0|7] "" Vector__XXX
 SG_ NumberAllowedHigh : 13|3@1+ (1,0) [0|7] "" Vector__XXX

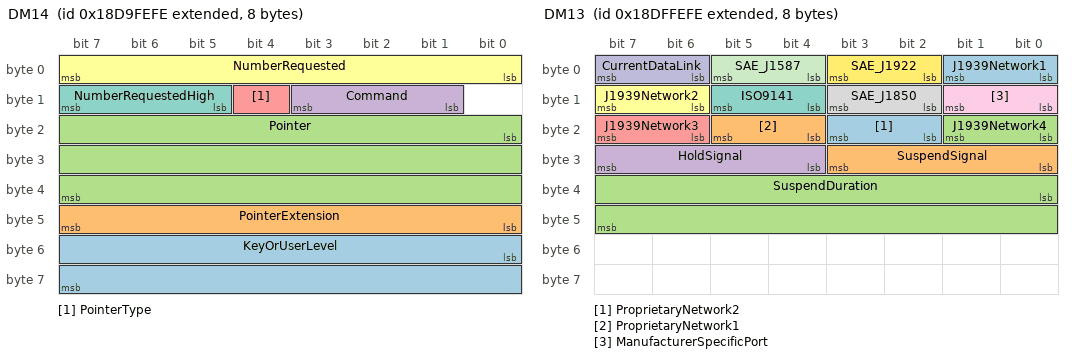
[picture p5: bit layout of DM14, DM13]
BO_ 2564423422 DM14: 8 Vector__XXX
 SG_ KeyOrUserLevel : 48|16@1+ (1,0) [0|65535] "" Vector__XXX
 SG_ PointerExtension : 40|8@1+ (1,0) [0|255] "" Vector__XXX
 SG_ Pointer : 16|24@1+ (1,0) [0|16777215] "" Vector__XXX
 SG_ Command : 9|3@1+ (1,0) [0|7] "" Vector__XXX
 SG_ PointerType : 12|1@1+ (1,0) [0|1] "" Vector__XXX
 SG_ NumberRequested : 0|8@1+ (1,0) [0|2047] "" Vector__XXX
 SG_ NumberRequestedHigh : 13|3@1+ (1,0) [0|7] "" Vector__XXX

BO_ 2564816638 DM13: 8 Vector__XXX
 SG_ ProprietaryNetwork2 : 18|2@1+ (1,0) [0|3] "" Vector__XXX
 SG_ ProprietaryNetwork1 : 20|2@1+ (1,0) [0|3] "" Vector__XXX
 SG_ J1939Network4 : 16|2@1+ (1,0) [0|3] "" Vector__XXX
 SG_ HoldSignal : 28|4@1+ (1,0) [0|15] "" Vector__XXX
 SG_ J1939Network3 : 22|2@1+ (1,0) [0|3] "" Vector__XXX
 SG_ J1939Network2 : 14|2@1+ (1,0) [0|3] "" Vector__XXX
 SG_ ISO9141 : 12|2@1+ (1,0) [0|3] "" Vector__XXX
 SG_ SAE_J1850 : 10|2@1+ (1,0) [0|3] "" Vector__XXX
 SG_ ManufacturerSpecificPort : 8|2@1+ (1,0) [0|3] "" Vector__XXX
 SG_ CurrentDataLink : 6|2@1+ (1,0) [0|3] "" Vector__XXX
 SG_ SAE_J1587 : 4|2@1+ (1,0) [0|3] "" Vector__XXX
 SG_ SAE_J1922 : 2|2@1+ (1,0) [0|3] "" Vector__XXX
 SG_ J1939Network1 : 0|2@1+ (1,0) [0|3] "" Vector__XXX
 SG_ SuspendSignal : 24|4@1+ (1,0) [0|15] "" Vector__XXX
 SG_ SuspendDuration : 32|16@1+ (1,0) [0|64255] "s" Vector__XXX

BO_ 2566837502 DM12: 22 Vector__XXX
 SG_ SPN_High4 : 133|3@1+ (1,0) [0|7] "" Vector__XXX
 SG_ SPN_High3 : 101|3@1+ (1,0) [0|7] "" Vector__XXX
 SG_ SPN_High5 : 165|3@1+ (1,0) [0|7] "" Vector__XXX
 SG_ SPN_High2 : 69|3@1+ (1,0) [0|7] "" Vector__XXX
 SG_ SPN_High1 : 37|3@1+ (1,0) [0|7] "" Vector__XXX
 SG_ SpnConversionMethod1 : 47|1@1+ (1,0) [0|1] "" Vector__XXX
 SG_ SpnConversionMethod5 : 175|1@1+ (1,0) [0|1] "" Vector__XXX
 SG_ SpnConversionMethod4 : 143|1@1+ (1,0) [0|1] "" Vector__XXX
 SG_ SpnConversionMethod3 : 111|1@1+ (1,0) [0|1] "" Vector__XXX
 SG_ SpnConversionMethod2 : 79|1@1+ (1,0) [0|1] "" Vector__XXX
 SG_ OccurenceCount5 : 168|7@1+ (1,0) [0|127] "" Vector__XXX
 SG_ OccurenceCount4 : 136|7@1+ (1,0) [0|127] "" Vector__XXX
 SG_ OccurenceCount3 : 104|7@1+ (1,0) [0|127] "" Vector__XXX
 SG_ OccurenceCount2 : 72|7@1+ (1,0) [0|127] "" Vector__XXX
 SG_ OccurenceCount1 : 40|7@1+ (1,0) [0|127] "" Vector__XXX
 SG_ FMI5 : 160|5@1+ (1,0) [0|31] "" Vector__XXX
 SG_ FMI4 : 128|5@1+ (1,0) [0|31] "" Vector__XXX
 SG_ FMI3 : 96|5@1+ (1,0) [0|31] "" Vector__XXX
 SG_ FMI2 : 64|5@1+ (1,0) [0|31] "" Vector__XXX
 SG_ FMI1 : 32|5@1+ (1,0) [0|31] "" Vector__XXX
 SG_ FlashRedStopLamp : 12|2@1+ (1,0) [0|3] "" Vector__XXX
 SG_ FlashProtectLamp : 8|2@1+ (1,0) [0|3] "" Vector__XXX
 SG_ FlashMalfuncIndicatorLamp : 14|2@1+ (1,0) [0|3] "" Vector__XXX
 SG_ FlashAmberWarningLamp : 10|2@1+ (1,0) [0|3] "" Vector__XXX
 SG_ MalfunctionIndLampStatus : 6|2@1+ (1,0) [0|3] "" Vector__XXX
 SG_ AmberWarningLampStatus : 2|2@1+ (1,0) [0|3] "" Vector__XXX
 SG_ RedStopLampState : 4|2@1+ (1,0) [0|3] "" Vector__XXX
 SG_ ProtectLampStatus : 0|2@1+ (1,0) [0|3] "" Vector__XXX
 SG_ SPN5 : 144|16@1+ (1,0) [0|524287] "" Vector__XXX
 SG_ SPN4 : 112|16@1+ (1,0) [0|524287] "" Vector__XXX
 SG_ SPN3 : 80|16@1+ (1,0) [0|524287] "" Vector__XXX
 SG_ SPN2 : 48|16@1+ (1,0) [0|524287] "" Vector__XXX
 SG_ SPN1 : 16|16@1+ (1,0) [0|524287] "" Vector__XXX

BO_ 2566837246 DM11: 0 Vector__XXX

BO_ 2566836990 DM10: 8 Vector__XXX
 SG_ TestIdentifierSupported : 0|64@1+ (1,0) [0|0] "" Vector__XXX

BO_ 2566836734 DM09: 8 Vector__XXX

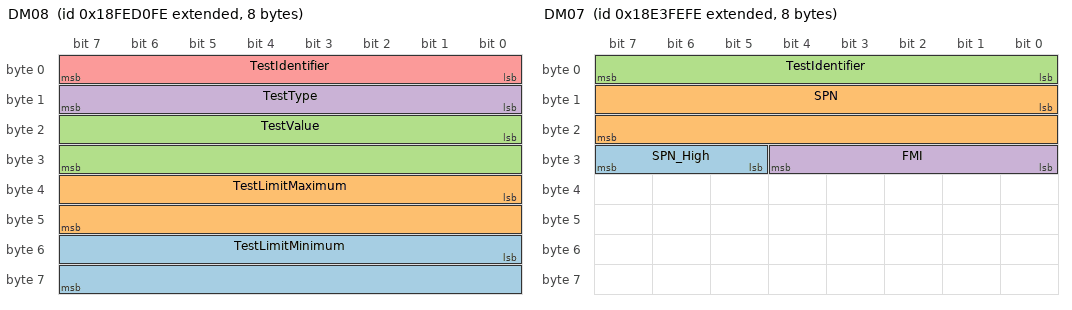
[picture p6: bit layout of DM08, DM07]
BO_ 2566836478 DM08: 8 Vector__XXX
 SG_ TestLimitMinimum : 48|16@1+ (1,0) [0|0] "" Vector__XXX
 SG_ TestLimitMaximum : 32|16@1+ (1,0) [0|0] "" Vector__XXX
 SG_ TestValue : 16|16@1+ (1,0) [0|0] "" Vector__XXX
 SG_ TestType : 8|8@1+ (1,0) [0|250] "" Vector__XXX
 SG_ TestIdentifier : 0|8@1+ (1,0) [0|255] "" Vector__XXX

BO_ 2565078782 DM07: 8 Vector__XXX
 SG_ SPN_High : 29|3@1+ (1,0) [0|7] "" Vector__XXX
 SG_ SPN : 8|16@1+ (1,0) [0|524287] "" Vector__XXX
 SG_ TestIdentifier : 0|8@1+ (1,0) [0|255] "" Vector__XXX
 SG_ FMI : 24|5@1+ (1,0) [0|31] "" Vector__XXX

CM_ BO_ 2566742014 "DTCs - A, Pending
Pending DTCs that are classified as class A severity.";
CM_ SG_ 2566742014 SPN_High4 "3 most significant bits of SPN (most significant at bit 8) ";
CM_ SG_ 2566742014 SPN_High3 "3 most significant bits of SPN (most significant at bit 8) ";
CM_ SG_ 2566742014 SPN_High5 "3 most significant bits of SPN (most significant at bit 8) ";
CM_ SG_ 2566742014 SPN_High2 "3 most significant bits of SPN (most significant at bit 8) ";
CM_ SG_ 2566742014 SPN_High1 "3 most significant bits of SPN (most significant at bit 8) ";
CM_ SG_ 2566742014 SpnConversionMethod1 "If set to '0', the document is converted according to version 4 of the J1939-73 document (February 1996); otherwise, it is converted according to one of the three earlier versions.";
CM_ SG_ 2566742014 SpnConversionMethod5 "If set to '0', the document is converted according to version 4 of the J1939-73 document (February 1996); otherwise, it is converted according to one of the three earlier versions.";
CM_ SG_ 2566742014 SpnConversionMethod4 "If set to '0', the document is converted according to version 4 of the J1939-73 document (February 1996); otherwise, it is converted according to one of the three earlier versions.";
CM_ SG_ 2566742014 SpnConversionMethod3 "If set to '0', the document is converted according to version 4 of the J1939-73 document (February 1996); otherwise, it is converted according to one of the three earlier versions.";
CM_ SG_ 2566742014 SpnConversionMethod2 "If set to '0', the document is converted according to version 4 of the J1939-73 document (February 1996); otherwise, it is converted according to one of the three earlier versions.";
CM_ SG_ 2566742014 OccurenceCount5 "Contains the number of times a fault has been independently detected.";
CM_ SG_ 2566742014 OccurenceCount4 "Contains the number of times a fault has been independently detected.";
CM_ SG_ 2566742014 OccurenceCount3 "Contains the number of times a fault has been independently detected.";
CM_ SG_ 2566742014 OccurenceCount2 "Contains the number of times a fault has been independently detected.";
CM_ SG_ 2566742014 OccurenceCount1 "Contains the number of times a fault has been independently detected.";
CM_ SG_ 2566742014 FMI5 "The FMI defines the type of failure detected in the subsystem identified by an SPN.";
CM_ SG_ 2566742014 FMI4 "The FMI defines the type of failure detected in the subsystem identified by an SPN.";
CM_ SG_ 2566742014 FMI3 "The FMI defines the type of failure detected in the subsystem identified by an SPN.";
CM_ SG_ 2566742014 FMI2 "The FMI defines the type of failure detected in the subsystem identified by an SPN.";
CM_ SG_ 2566742014 FMI1 "The FMI defines the type of failure detected in the subsystem identified by an SPN.";
CM_ SG_ 2566742014 FlashRedStopLamp "This parameter provides the capability to flash the RSL


00 - Slow Flash (1 Hz, 50 % duty cycle)
01 - Fast Flash (2 Hz or faster, 50% duty cycle)
10 - Reserved
11 - Unavailable / Do Not Flash";
CM_ SG_ 2566742014 FlashProtectLamp "This parameter provides the capability to flash the engine protect lamp


00 - Slow Flash (1 Hz, 50 % duty cycle)
01 - Fast Flash (2 Hz or faster, 50% duty cycle)
10 - Reserved
11 - Unavailable / Do Not Flash";
CM_ SG_ 2566742014 FlashMalfuncIndicatorLamp "This parameter provides the capability to flash the MIL
00 - Slow Flash (1 Hz, 50 % duty cycle)
01 - Fast Flash (2 Hz or faster, 50% duty cycle)
10 - Class C DTC
11 - Unavailable / Do Not Flash
Note:  State 10 is for WWH OBD discriminatory ...";
CM_ SG_ 2566742014 FlashAmberWarningLamp "This parameter provides the capability to flash the AWL

00 - Slow Flash (1 Hz, 50 % duty cycle)
01 - Fast Flash (2 Hz or faster, 50% duty cycle)
10 - Reserved
11 - Unavailable / Do Not Flash";
CM_ SG_ 2566742014 MalfunctionIndLampStatus "A lamp used to relay only emissions-related trouble code information. This lamp is only illuminated when there is an emission-related trouble code active.
00     Lamp Off
01     Lamp On
10     Short MIL for WWH OBD
11     Not available
Note ...";
CM_ SG_ 2566742014 AmberWarningLampStatus "This lamp is used to relay trouble code information that is reporting a problem with the vehicle system but the vehicle need not be immediately stopped. 

00     Lamp Off
01     Lamp On
10     Reserved
11     Not available";
CM_ SG_ 2566742014 RedStopLampState "This lamp is used to relay trouble code information that is of a severe enough condition that it warrants stopping the vehicle.

00     Lamp Off
01     Lamp On
10     Reserved
11     Not available";
CM_ SG_ 2566742014 ProtectLampStatus "This lamp is used to relay trouble code information that is reporting a problem with a vehicle system that is most probably not electronic subsystem related. For instance, engine coolant temperature is exceeding its prescribed temperature range.
00 ...";
CM_ SG_ 2566742014 SPN5 "16 least significant bits of SPN";
CM_ SG_ 2566742014 SPN4 "16 least significant bits of SPN";
CM_ SG_ 2566742014 SPN3 "16 least significant bits of SPN";
CM_ SG_ 2566742014 SPN2 "16 least significant bits of SPN";
CM_ SG_ 2566742014 SPN1 "16 least significant bits of SPN";
CM_ BO_ 2566742270 "Harmonized B1 Failure Counts (HB1C)
HB1C provides the system specific individual B1 failure counters, when supported by the system.";
CM_ SG_ 2566742270 FailureSpecificB1Counter4 "The Failure Specific B1 Counter provides an individual B1 counter";
CM_ SG_ 2566742270 FailureSpecificB1Counter3 "The Failure Specific B1 Counter provides an individual B1 counter";
CM_ SG_ 2566742270 FailureSpecificB1Counter2 "The Failure Specific B1 Counter provides an individual B1 counter";
CM_ SG_ 2566742270 SPN4_High "3 most significant bits of SPN (most significant at bit 8) ";
CM_ SG_ 2566742270 SPN3_High "3 most significant bits of SPN (most significant at bit 8) ";
CM_ SG_ 2566742270 SPN2_High "3 most significant bits of SPN (most significant at bit 8) ";
CM_ SG_ 2566742270 SPN4 "16 least significant bits of SPN";
CM_ SG_ 2566742270 SPN3 "16 least significant bits of SPN";
CM_ SG_ 2566742270 SPN2 "16 least significant bits of SPN";
CM_ SG_ 2566742270 FMI4 "The FMI defines the type of failure detected in the subsystem identified by an SPN.";
CM_ SG_ 2566742270 FMI3 "The FMI defines the type of failure detected in the subsystem identified by an SPN.";
CM_ SG_ 2566742270 FMI2 "The FMI defines the type of failure detected in the subsystem identified by an SPN.";
CM_ SG_ 2566742270 SPN1 "16 least significant bits of SPN";
CM_ SG_ 2566742270 SPN1_High "3 most significant bits of SPN (most significant at bit 8) ";
CM_ SG_ 2566742270 FMI1 "The FMI defines the type of failure detected in the subsystem identified by an SPN.";
CM_ SG_ 2566742270 FailureSpecificB1Counter1 "The Failure Specific B1 Counter provides an individual B1 counter";
CM_ BO_ 2566742526 "Cumulative Continuous MI – System (HCMI) 
HCMI provides the system specific cumulative.";
CM_ SG_ 2566742526 SysGreatestB1Counter "System Greatest B1 Counter";
CM_ SG_ 2566742526 SysCumulativeContinuousMITime "System Cumulative Continuous MI Time";
CM_ BO_ 2566742782 "Harmonized Global Regulation Description (HGRD)
HGRD provides a description of the UN/ECE WWH OBD Global Technical Regulation (GTR) to which the sub-system or
component complies.";
CM_ SG_ 2566742782 RegulationDescription "Global Technical Regulation Description";
CM_ BO_ 2566743038 "Harmonized Roadworthiness – System (HRWS)
HRWS reports subsystem (or component) roadworthiness to the VOBD function to aggregate in the HRWV message.";
CM_ SG_ 2566743038 SysIncompleteMonitorCount "System Incomplete Monitor Count";
CM_ SG_ 2566743038 SysMalIndActivationMode "System Malfunction Indicator Status";
CM_ SG_ 2566743038 SysMalIndDisplayStrategy "System Malfunction Indicator Display";
CM_ SG_ 2566743038 SysContinuousMalfunctionInd "System Continuous Malfunction Indicator";
CM_ SG_ 2566743038 SysNonRoadworthyCompCount "System Non-Roadworthy Component Count";
CM_ BO_ 2566743294 "Harmonized Roadworthiness - Vehicle (HRWV)
HRWV provides the aggregated roadworthiness from the VOBD (Vehicle On-Board Diagnostics) to a scan tool or similar inquiry device.";
CM_ SG_ 2566743294 VehicleCurrentMIAccumTime "Vehicle current malfunction indicator accumulated time reports the accumulated count (in minutes) that the malfunction indicator lamp (MIL) is activated (on) for the current malfunction indicator (MI) activation (or the last MI activation).
For US, ...";
CM_ SG_ 2566743294 VehicleIncompleteMonitorCount "Vehicle Incomplete Monitor Count";
CM_ SG_ 2566743294 VehicleMalfunctionIndActMode "Vehicle Malfunction Indicator Status ";
CM_ SG_ 2566743294 VehicleMalfunctionIndStrategy "Vehicle Malfunction Indicator Display Strategy ";
CM_ SG_ 2566743294 VehicleContinuousMalfunctionInd "Vehicle Continuous Malfunction Indicator";
CM_ SG_ 2566743294 VehicleNonRoadworthyCompCount "Vehicle Non-Roadworthy Component Count";
CM_ BO_ 2560622334 "Immediate Fault Status
The purpose of this DM is to enable the external test equipment to obtain the instantaneous status of diagnostic results";
CM_ SG_ 2560622334 SPN_High4 "3 most significant bits of SPN (most significant at bit 8) ";
CM_ SG_ 2560622334 SPN_High3 "3 most significant bits of SPN (most significant at bit 8) ";
CM_ SG_ 2560622334 SPN_High5 "3 most significant bits of SPN (most significant at bit 8) ";
CM_ SG_ 2560622334 SPN_High2 "3 most significant bits of SPN (most significant at bit 8) ";
CM_ SG_ 2560622334 SPN_High1 "3 most significant bits of SPN (most significant at bit 8) ";
CM_ SG_ 2560622334 SpnConversionMethod1 "If set to '0', the document is converted according to version 4 of the J1939-73 document (February 1996); otherwise, it is converted according to one of the three earlier versions.";
CM_ SG_ 2560622334 SpnConversionMethod5 "If set to '0', the document is converted according to version 4 of the J1939-73 document (February 1996); otherwise, it is converted according to one of the three earlier versions.";
CM_ SG_ 2560622334 SpnConversionMethod4 "If set to '0', the document is converted according to version 4 of the J1939-73 document (February 1996); otherwise, it is converted according to one of the three earlier versions.";
CM_ SG_ 2560622334 SpnConversionMethod3 "If set to '0', the document is converted according to version 4 of the J1939-73 document (February 1996); otherwise, it is converted according to one of the three earlier versions.";
CM_ SG_ 2560622334 SpnConversionMethod2 "If set to '0', the document is converted according to version 4 of the J1939-73 document (February 1996); otherwise, it is converted according to one of the three earlier versions.";
CM_ SG_ 2560622334 OccurenceCount5 "Contains the number of times a fault has been independently detected.";
CM_ SG_ 2560622334 OccurenceCount4 "Contains the number of times a fault has been independently detected.";
CM_ SG_ 2560622334 OccurenceCount3 "Contains the number of times a fault has been independently detected.";
CM_ SG_ 2560622334 OccurenceCount2 "Contains the number of times a fault has been independently detected.";
CM_ SG_ 2560622334 OccurenceCount1 "Contains the number of times a fault has been independently detected.";
CM_ SG_ 2560622334 FMI5 "The FMI defines the type of failure detected in the subsystem identified by an SPN.";
CM_ SG_ 2560622334 FMI4 "The FMI defines the type of failure detected in the subsystem identified by an SPN.";
CM_ SG_ 2560622334 FMI3 "The FMI defines the type of failure detected in the subsystem identified by an SPN.";
CM_ SG_ 2560622334 FMI2 "The FMI defines the type of failure detected in the subsystem identified by an SPN.";
CM_ SG_ 2560622334 FMI1 "The FMI defines the type of failure detected in the subsystem identified by an SPN.";
CM_ SG_ 2560622334 FlashRedStopLamp "This parameter provides the capability to flash the RSL


00 - Slow Flash (1 Hz, 50 % duty cycle)
01 - Fast Flash (2 Hz or faster, 50% duty cycle)
10 - Reserved
11 - Unavailable / Do Not Flash";
CM_ SG_ 2560622334 FlashProtectLamp "This parameter provides the capability to flash the engine protect lamp


00 - Slow Flash (1 Hz, 50 % duty cycle)
01 - Fast Flash (2 Hz or faster, 50% duty cycle)
10 - Reserved
11 - Unavailable / Do Not Flash";
CM_ SG_ 2560622334 FlashMalfuncIndicatorLamp "This parameter provides the capability to flash the MIL
00 - Slow Flash (1 Hz, 50 % duty cycle)
01 - Fast Flash (2 Hz or faster, 50% duty cycle)
10 - Class C DTC
11 - Unavailable / Do Not Flash
Note:  State 10 is for WWH OBD discriminatory ...";
CM_ SG_ 2560622334 FlashAmberWarningLamp "This parameter provides the capability to flash the AWL

00 - Slow Flash (1 Hz, 50 % duty cycle)
01 - Fast Flash (2 Hz or faster, 50% duty cycle)
10 - Reserved
11 - Unavailable / Do Not Flash";
CM_ SG_ 2560622334 MalfunctionIndLampStatus "A lamp used to relay only emissions-related trouble code information. This lamp is only illuminated when there is an emission-related trouble code active.
00     Lamp Off
01     Lamp On
10     Short MIL for WWH OBD
11     Not available
Note ...";
CM_ SG_ 2560622334 AmberWarningLampStatus "This lamp is used to relay trouble code information that is reporting a problem with the vehicle system but the vehicle need not be immediately stopped. 

00     Lamp Off
01     Lamp On
10     Reserved
11     Not available";
CM_ SG_ 2560622334 RedStopLampState "This lamp is used to relay trouble code information that is of a severe enough condition that it warrants stopping the vehicle.

00     Lamp Off
01     Lamp On
10     Reserved
11     Not available";
CM_ SG_ 2560622334 ProtectLampStatus "This lamp is used to relay trouble code information that is reporting a problem with a vehicle system that is most probably not electronic subsystem related. For instance, engine coolant temperature is exceeding its prescribed temperature range.
00 ...";
CM_ SG_ 2560622334 SPN5 "16 least significant bits of SPN";
CM_ SG_ 2560622334 SPN4 "16 least significant bits of SPN";
CM_ SG_ 2560622334 SPN3 "16 least significant bits of SPN";
CM_ SG_ 2560622334 SPN2 "16 least significant bits of SPN";
CM_ SG_ 2560622334 SPN1 "16 least significant bits of SPN";
CM_ BO_ 2560687870 "NTE Status
The status of engine operating in the NTE control areas for given pollutants, such as NOx and PM.";
CM_ SG_ 2560687870 PMNTEDeficiencyAreaStatus "Status of engine operation within the PM NTE Deficiency Area.  The PM NTE Deficiency Area is defined as bounded regions or conditions within the NTE control area for PM where the manufacturer has received a deficiency.  If the application does not ...";
CM_ SG_ 2560687870 MnfcPMNTECarveOutAreaStatus "Status of engine operation within the manufacturer specific PM NTE limited testing region.  The manufacturer specific PM NTE  limited testing region is defined as bounded regions within the NTE control area for PM where the manufacturer has limited ...";
CM_ SG_ 2560687870 PMNTEControlAreaStatus "Status of engine operation within the bounded region of the engine’s torque and speed map where emissions must not exceed a specific emission cap for PM under the NTE requirement.";
CM_ SG_ 2560687870 NOxNTEDeficiencyAreaStatus "Status of engine operation within the NOx NTE Deficiency Area.  The NOx NTE Deficiency Area is defined as bounded regions or conditions within the NTE control area for NOx where the manufacturer has received a deficiency.  If the application does ...";
CM_ SG_ 2560687870 MnfcNOxNTECarveOutAreaStatus "Status of engine operation within the manufacturer specific NOx NTE limited testing region.  The manufacturer specific NOx NTE limited testing region is defined as bounded regions within the NTE control area for NOx where the manufacturer has ...";
CM_ SG_ 2560687870 NOxNTEControlAreaStatus "Status of engine operation within the bounded region of the engine’s torque and speed map where emissions must not exceed a specific emission cap for NOx under the NTE requirement.";
CM_ BO_ 2292317950 "Emission Increasing Auxiliary Emission Control Device Active Time
The total engine run time while each of the Emission Increasing Auxiliary Emission Control Devices (EI-AECDs) is active.";
CM_ SG_ 2292317950 AECDEngineHours1Timer2 "The total engine running hours recorded in the second timer for the EI-AECD";
CM_ SG_ 2292317950 AECDEngineHours1Timer1 "The total engine running hours recorded in the first timer for the EI-AECD";
CM_ SG_ 2292317950 AECDNumber1 "The manufacturer assigned number for the specific EI-AECD";
CM_ BO_ 2560818942 "Regulated Exhaust Emission Level Exceedance
Provides the DTCs and associated timers related to a regulated exhaust emission level exceedance due to an emission control system malfunction.";
CM_ SG_ 2560818942 DTCTotalPreviouslyActiveTime4 "This timer provides the number of hours the NOx malfunction has been confirmed and previously active";
CM_ SG_ 2560818942 DTCTotalPreviouslyActiveTime3 "This timer provides the number of hours the NOx malfunction has been confirmed and previously active";
CM_ SG_ 2560818942 DTCTotalPreviouslyActiveTime2 "This timer provides the number of hours the NOx malfunction has been confirmed and previously active";
CM_ SG_ 2560818942 DTCTotalActiveTime4 "This timer provides the total number of hours the DTC has been confirmed and active";
CM_ SG_ 2560818942 DTCTotalActiveTime3 "This timer provides the total number of hours the DTC has been confirmed and active";
CM_ SG_ 2560818942 DTCTotalActiveTime2 "This timer provides the total number of hours the DTC has been confirmed and active";
CM_ SG_ 2560818942 DTCTimeUntilDerate4 "This timer provides the number of hours the malfunction has until the OBD required derate will occur";
CM_ SG_ 2560818942 DTCTimeUntilDerate3 "This timer provides the number of hours the malfunction has until the OBD required derate will occur";
CM_ SG_ 2560818942 DTCTimeUntilDerate2 "This timer provides the number of hours the malfunction has until the OBD required derate will occur";
CM_ SG_ 2560818942 SPN4_High "3 most significant bits of SPN (most significant at bit 8) ";
CM_ SG_ 2560818942 SPN3_High "3 most significant bits of SPN (most significant at bit 8) ";
CM_ SG_ 2560818942 SPN2_High "3 most significant bits of SPN (most significant at bit 8) ";
CM_ SG_ 2560818942 SPN1_High "3 most significant bits of SPN (most significant at bit 8) ";
CM_ SG_ 2560818942 SPN4 "16 least significant bits of SPN";
CM_ SG_ 2560818942 SPN3 "16 least significant bits of SPN";
CM_ SG_ 2560818942 SPN2 "16 least significant bits of SPN";
CM_ SG_ 2560818942 FMI4 "The FMI defines the type of failure detected in the subsystem identified by an SPN.";
CM_ SG_ 2560818942 FMI3 "The FMI defines the type of failure detected in the subsystem identified by an SPN.";
CM_ SG_ 2560818942 FMI2 "The FMI defines the type of failure detected in the subsystem identified by an SPN.";
CM_ SG_ 2560818942 SPN1 "16 least significant bits of SPN";
CM_ SG_ 2560818942 FMI1 "The FMI defines the type of failure detected in the subsystem identified by an SPN.";
CM_ SG_ 2560818942 DTCTimeUntilDerate1 "This timer provides the number of hours the malfunction has until the OBD required derate will occur";
CM_ SG_ 2560818942 DTCTotalPreviouslyActiveTime1 "This timer provides the number of hours the NOx malfunction has been confirmed and previously active";
CM_ SG_ 2560818942 DTCTotalActiveTime1 "This timer provides the total number of hours the DTC has been confirmed and active";
CM_ BO_ 2560884478 "DTC To Lamp Association
This message shall provide the applicable lamp(s) for each individual DTC";
CM_ SG_ 2560884478 SpnConversionMethod "If set to '0', the document is converted according to version 4 of the J1939-73 document (February 1996); otherwise, it is converted according to one of the three earlier versions.";
CM_ SG_ 2560884478 OccurenceCount "Contains the number of times a fault has been independently detected.";
CM_ SG_ 2560884478 SPN_High "3 most significant bits of SPN (most significant at bit 8) ";
CM_ SG_ 2560884478 FMI "Failure Mode Identifier (FMI) 
The FMI defines the type of failure detected in the sub-system identified by an SPN.";
CM_ SG_ 2560884478 SPN "16 least significant bits of SPN";
CM_ SG_ 2560884478 DTCWarnLampSupportStatus "Lamp support status";
CM_ SG_ 2560884478 DTCWarnLampSupportFlash "Lamp support status";
CM_ SG_ 2560884478 DTCStopLampSupportStatus "Lamp support status";
CM_ SG_ 2560884478 DTCStopLampSupportFlash "Lamp support status";
CM_ SG_ 2560884478 DTCProtectLampSupportStatus "Lamp support status";
CM_ SG_ 2560884478 DTCProtectLampSupportFlash "Lamp support status";
CM_ SG_ 2560884478 DTCMilSupportStatus "Lamp support status";
CM_ SG_ 2560884478 DTCMilSupportFlash "Lamp support status";
CM_ BO_ 2560950014 "Scaled Test Results
This message conveys the scaled test results for the applicable test requested in DM7. The SPN and FMI convey the specific DTC for which the results are being reported.";
CM_ SG_ 2560950014 TestLimitMinimum4 "The test value must be greater than or equal to Test Limit Minimum in order for the test to pass";
CM_ SG_ 2560950014 TestLimitMinimum3 "The test value must be greater than or equal to Test Limit Minimum in order for the test to pass";
CM_ SG_ 2560950014 TestLimitMinimum2 "The test value must be greater than or equal to Test Limit Minimum in order for the test to pass";
CM_ SG_ 2560950014 TestLimitMaximum4 "The test value must be less than or equal to Test Limit Maximum in order for the test to pass.";
CM_ SG_ 2560950014 TestLimitMaximum3 "The test value must be less than or equal to Test Limit Maximum in order for the test to pass.";
CM_ SG_ 2560950014 TestLimitMaximum2 "The test value must be less than or equal to Test Limit Maximum in order for the test to pass.";
CM_ SG_ 2560950014 TestValue4 "The test value collected during the test.";
CM_ SG_ 2560950014 TestValue3 "The test value collected during the test.";
CM_ SG_ 2560950014 TestValue2 "The test value collected during the test.";
CM_ SG_ 2560950014 SlotId4 "The SLOT Identifer is used to determine the multiplier and offset to be used to scale the test value.";
CM_ SG_ 2560950014 SlotId3 "The SLOT Identifer is used to determine the multiplier and offset to be used to scale the test value.";
CM_ SG_ 2560950014 SlotId2 "The SLOT Identifer is used to determine the multiplier and offset to be used to scale the test value.";
CM_ SG_ 2560950014 TestIdentifier4 "Test Identifier";
CM_ SG_ 2560950014 TestIdentifier3 "Test Identifier";
CM_ SG_ 2560950014 TestIdentifier2 "Test Identifier";
CM_ SG_ 2560950014 SPN1_High "3 most significant bits of SPN (most significant at bit 8) ";
CM_ SG_ 2560950014 SPN2_High "3 most significant bits of SPN (most significant at bit 8) ";
CM_ SG_ 2560950014 SPN3_High "3 most significant bits of SPN (most significant at bit 8) ";
CM_ SG_ 2560950014 SPN4_High "3 most significant bits of SPN (most significant at bit 8) ";
CM_ SG_ 2560950014 FMI2 "The FMI defines the type of failure detected in the subsystem identified by an SPN.";
CM_ SG_ 2560950014 FMI3 "The FMI defines the type of failure detected in the subsystem identified by an SPN.";
CM_ SG_ 2560950014 FMI4 "The FMI defines the type of failure detected in the subsystem identified by an SPN.";
CM_ SG_ 2560950014 FMI1 "The FMI defines the type of failure detected in the subsystem identified by an SPN.";
CM_ SG_ 2560950014 SPN2 "16 least significant bits of SPN";
CM_ SG_ 2560950014 SPN3 "16 least significant bits of SPN";
CM_ SG_ 2560950014 SPN4 "16 least significant bits of SPN";
CM_ SG_ 2560950014 TestLimitMinimum1 "The test value must be greater than or equal to Test Limit Minimum in order for the test to pass";
CM_ SG_ 2560950014 SPN1 "16 least significant bits of SPN";
CM_ SG_ 2560950014 TestLimitMaximum1 "The test value must be less than or equal to Test Limit Maximum in order for the test to pass.";
CM_ SG_ 2560950014 TestValue1 "The test value collected during the test.";
CM_ SG_ 2560950014 SlotId1 "The SLOT Identifer is used to determine the multiplier and offset to be used to scale the test value.";
CM_ SG_ 2560950014 TestIdentifier1 "Test Identifier";
CM_ BO_ 2560556798 "DTC Counts
The purpose of this DM is to identify the number of DTCs in each category. The categories are pending, all pending, MIL-on, previously MIL-on, and permanent DTCs.";
CM_ BO_ 2566750462 "Permanent DTCs
The purpose of this DM is to provide the list of permanent DTCs that are currently present.";
CM_ SG_ 2566750462 SPN_High4 "3 most significant bits of SPN (most significant at bit 8) ";
CM_ SG_ 2566750462 SPN_High3 "3 most significant bits of SPN (most significant at bit 8) ";
CM_ SG_ 2566750462 SPN_High5 "3 most significant bits of SPN (most significant at bit 8) ";
CM_ SG_ 2566750462 SPN_High2 "3 most significant bits of SPN (most significant at bit 8) ";
CM_ SG_ 2566750462 SPN_High1 "3 most significant bits of SPN (most significant at bit 8) ";
CM_ SG_ 2566750462 SpnConversionMethod1 "If set to '0', the document is converted according to version 4 of the J1939-73 document (February 1996); otherwise, it is converted according to one of the three earlier versions.";
CM_ SG_ 2566750462 SpnConversionMethod5 "If set to '0', the document is converted according to version 4 of the J1939-73 document (February 1996); otherwise, it is converted according to one of the three earlier versions.";
CM_ SG_ 2566750462 SpnConversionMethod4 "If set to '0', the document is converted according to version 4 of the J1939-73 document (February 1996); otherwise, it is converted according to one of the three earlier versions.";
CM_ SG_ 2566750462 SpnConversionMethod3 "If set to '0', the document is converted according to version 4 of the J1939-73 document (February 1996); otherwise, it is converted according to one of the three earlier versions.";
CM_ SG_ 2566750462 SpnConversionMethod2 "If set to '0', the document is converted according to version 4 of the J1939-73 document (February 1996); otherwise, it is converted according to one of the three earlier versions.";
CM_ SG_ 2566750462 OccurenceCount5 "Contains the number of times a fault has been independently detected.";
CM_ SG_ 2566750462 OccurenceCount4 "Contains the number of times a fault has been independently detected.";
CM_ SG_ 2566750462 OccurenceCount3 "Contains the number of times a fault has been independently detected.";
CM_ SG_ 2566750462 OccurenceCount2 "Contains the number of times a fault has been independently detected.";
CM_ SG_ 2566750462 OccurenceCount1 "Contains the number of times a fault has been independently detected.";
CM_ SG_ 2566750462 FMI5 "The FMI defines the type of failure detected in the subsystem identified by an SPN.";
CM_ SG_ 2566750462 FMI4 "The FMI defines the type of failure detected in the subsystem identified by an SPN.";
CM_ SG_ 2566750462 FMI3 "The FMI defines the type of failure detected in the subsystem identified by an SPN.";
CM_ SG_ 2566750462 FMI2 "The FMI defines the type of failure detected in the subsystem identified by an SPN.";
CM_ SG_ 2566750462 FMI1 "The FMI defines the type of failure detected in the subsystem identified by an SPN.";
CM_ SG_ 2566750462 FlashRedStopLamp "This parameter provides the capability to flash the RSL


00 - Slow Flash (1 Hz, 50 % duty cycle)
01 - Fast Flash (2 Hz or faster, 50% duty cycle)
10 - Reserved
11 - Unavailable / Do Not Flash";
CM_ SG_ 2566750462 FlashProtectLamp "This parameter provides the capability to flash the engine protect lamp


00 - Slow Flash (1 Hz, 50 % duty cycle)
01 - Fast Flash (2 Hz or faster, 50% duty cycle)
10 - Reserved
11 - Unavailable / Do Not Flash";
CM_ SG_ 2566750462 FlashMalfuncIndicatorLamp "This parameter provides the capability to flash the MIL
00 - Slow Flash (1 Hz, 50 % duty cycle)
01 - Fast Flash (2 Hz or faster, 50% duty cycle)
10 - Class C DTC
11 - Unavailable / Do Not Flash
Note:  State 10 is for WWH OBD discriminatory ...";
CM_ SG_ 2566750462 FlashAmberWarningLamp "This parameter provides the capability to flash the AWL

00 - Slow Flash (1 Hz, 50 % duty cycle)
01 - Fast Flash (2 Hz or faster, 50% duty cycle)
10 - Reserved
11 - Unavailable / Do Not Flash";
CM_ SG_ 2566750462 MalfunctionIndLampStatus "A lamp used to relay only emissions-related trouble code information. This lamp is only illuminated when there is an emission-related trouble code active.
00     Lamp Off
01     Lamp On
10     Short MIL for WWH OBD
11     Not available
Note ...";
CM_ SG_ 2566750462 AmberWarningLampStatus "This lamp is used to relay trouble code information that is reporting a problem with the vehicle system but the vehicle need not be immediately stopped. 

00     Lamp Off
01     Lamp On
10     Reserved
11     Not available";
CM_ SG_ 2566750462 RedStopLampState "This lamp is used to relay trouble code information that is of a severe enough condition that it warrants stopping the vehicle.

00     Lamp Off
01     Lamp On
10     Reserved
11     Not available";
CM_ SG_ 2566750462 ProtectLampStatus "This lamp is used to relay trouble code information that is reporting a problem with a vehicle system that is most probably not electronic subsystem related. For instance, engine coolant temperature is exceeding its prescribed temperature range.
00 ...";
CM_ SG_ 2566750462 SPN5 "16 least significant bits of SPN";
CM_ SG_ 2566750462 SPN4 "16 least significant bits of SPN";
CM_ SG_ 2566750462 SPN3 "16 least significant bits of SPN";
CM_ SG_ 2566750462 SPN2 "16 least significant bits of SPN";
CM_ SG_ 2566750462 SPN1 "16 least significant bits of SPN";
CM_ BO_ 2566750974 "All Pending DTCs
To transmit “pending” diagnostic trouble codes detected during current or last completed driving cycle 
for components/systems that are tested or continuously monitored during normal driving conditions.";
CM_ SG_ 2566750974 SPN_High4 "3 most significant bits of SPN (most significant at bit 8) ";
CM_ SG_ 2566750974 SPN_High3 "3 most significant bits of SPN (most significant at bit 8) ";
CM_ SG_ 2566750974 SPN_High5 "3 most significant bits of SPN (most significant at bit 8) ";
CM_ SG_ 2566750974 SPN_High2 "3 most significant bits of SPN (most significant at bit 8) ";
CM_ SG_ 2566750974 SPN_High1 "3 most significant bits of SPN (most significant at bit 8) ";
CM_ SG_ 2566750974 SpnConversionMethod1 "If set to '0', the document is converted according to version 4 of the J1939-73 document (February 1996); otherwise, it is converted according to one of the three earlier versions.";
CM_ SG_ 2566750974 SpnConversionMethod5 "If set to '0', the document is converted according to version 4 of the J1939-73 document (February 1996); otherwise, it is converted according to one of the three earlier versions.";
CM_ SG_ 2566750974 SpnConversionMethod4 "If set to '0', the document is converted according to version 4 of the J1939-73 document (February 1996); otherwise, it is converted according to one of the three earlier versions.";
CM_ SG_ 2566750974 SpnConversionMethod3 "If set to '0', the document is converted according to version 4 of the J1939-73 document (February 1996); otherwise, it is converted according to one of the three earlier versions.";
CM_ SG_ 2566750974 SpnConversionMethod2 "If set to '0', the document is converted according to version 4 of the J1939-73 document (February 1996); otherwise, it is converted according to one of the three earlier versions.";
CM_ SG_ 2566750974 OccurenceCount5 "Contains the number of times a fault has been independently detected.";
CM_ SG_ 2566750974 OccurenceCount4 "Contains the number of times a fault has been independently detected.";
CM_ SG_ 2566750974 OccurenceCount3 "Contains the number of times a fault has been independently detected.";
CM_ SG_ 2566750974 OccurenceCount2 "Contains the number of times a fault has been independently detected.";
CM_ SG_ 2566750974 OccurenceCount1 "Contains the number of times a fault has been independently detected.";
CM_ SG_ 2566750974 FMI5 "The FMI defines the type of failure detected in the subsystem identified by an SPN.";
CM_ SG_ 2566750974 FMI4 "The FMI defines the type of failure detected in the subsystem identified by an SPN.";
CM_ SG_ 2566750974 FMI3 "The FMI defines the type of failure detected in the subsystem identified by an SPN.";
CM_ SG_ 2566750974 FMI2 "The FMI defines the type of failure detected in the subsystem identified by an SPN.";
CM_ SG_ 2566750974 FMI1 "The FMI defines the type of failure detected in the subsystem identified by an SPN.";
CM_ SG_ 2566750974 FlashRedStopLamp "This parameter provides the capability to flash the RSL


00 - Slow Flash (1 Hz, 50 % duty cycle)
01 - Fast Flash (2 Hz or faster, 50% duty cycle)
10 - Reserved
11 - Unavailable / Do Not Flash";
CM_ SG_ 2566750974 FlashProtectLamp "This parameter provides the capability to flash the engine protect lamp


00 - Slow Flash (1 Hz, 50 % duty cycle)
01 - Fast Flash (2 Hz or faster, 50% duty cycle)
10 - Reserved
11 - Unavailable / Do Not Flash";
CM_ SG_ 2566750974 FlashMalfuncIndicatorLamp "This parameter provides the capability to flash the MIL
00 - Slow Flash (1 Hz, 50 % duty cycle)
01 - Fast Flash (2 Hz or faster, 50% duty cycle)
10 - Class C DTC
11 - Unavailable / Do Not Flash
Note:  State 10 is for WWH OBD discriminatory ...";
CM_ SG_ 2566750974 FlashAmberWarningLamp "This parameter provides the capability to flash the AWL

00 - Slow Flash (1 Hz, 50 % duty cycle)
01 - Fast Flash (2 Hz or faster, 50% duty cycle)
10 - Reserved
11 - Unavailable / Do Not Flash";
CM_ SG_ 2566750974 MalfunctionIndLampStatus "A lamp used to relay only emissions-related trouble code information. This lamp is only illuminated when there is an emission-related trouble code active.
00     Lamp Off
01     Lamp On
10     Short MIL for WWH OBD
11     Not available
Note ...";
CM_ SG_ 2566750974 AmberWarningLampStatus "This lamp is used to relay trouble code information that is reporting a problem with the vehicle system but the vehicle need not be immediately stopped. 

00     Lamp Off
01     Lamp On
10     Reserved
11     Not available";
CM_ SG_ 2566750974 RedStopLampState "This lamp is used to relay trouble code information that is of a severe enough condition that it warrants stopping the vehicle.

00     Lamp Off
01     Lamp On
10     Reserved
11     Not available";
CM_ SG_ 2566750974 ProtectLampStatus "This lamp is used to relay trouble code information that is reporting a problem with a vehicle system that is most probably not electronic subsystem related. For instance, engine coolant temperature is exceeding its prescribed temperature range.
00 ...";
CM_ SG_ 2566750974 SPN5 "16 least significant bits of SPN";
CM_ SG_ 2566750974 SPN4 "16 least significant bits of SPN";
CM_ SG_ 2566750974 SPN3 "16 least significant bits of SPN";
CM_ SG_ 2566750974 SPN2 "16 least significant bits of SPN";
CM_ SG_ 2566750974 SPN1 "16 least significant bits of SPN";
CM_ BO_ 2566764798 "Diagnostic Readiness 3
This message conveys information useful in determining whether the OBD System has a defect or not.";
CM_ SG_ 2566764798 NumOfWarmUpsSinceDTCsCleared "Number of warm-up cycles since all DTCs were cleared (via an external test equipment or possibly, a battery disconnect).  A warm-up is defined in the OBD regulations to be sufficient vehicle operation such that coolant temperature rises by at least ...";
CM_ SG_ 2566764798 TimeSinceEngineStart "RUNTM shall increment while the engine is running.  It shall freeze if the engine stalls.  RUNTM shall be reset to zero during every control module power-up and when entering the key-on, engine off position.  RUNTM is limited to 65,535 seconds and ...";
CM_ BO_ 2566764542 "Expanded Freeze Frame
This message defines the expanded freeze frame length";
CM_ SG_ 2566764542 SpnConversionMethod "If set to '0', the document is converted according to version 4 of the J1939-73 document (February 1996); otherwise, it is converted according to one of the three earlier versions.";
CM_ SG_ 2566764542 OccurenceCount "Contains the number of times a fault has been independently detected.";
CM_ SG_ 2566764542 SPN_High "3 most significant bits of SPN (most significant at bit 8) ";
CM_ SG_ 2566764542 FMI "Failure Mode Identifier (FMI) 
The FMI defines the type of failure detected in the sub-system identified by an SPN.";
CM_ SG_ 2566764542 ExpandedFreezeFrameLength "The Freeze Frame Length is the length plus the number of bytes to convey the data of all parameters (SPNs) in Freeze Frame.";
CM_ SG_ 2566764542 SPN "16 least significant bits of SPN";
CM_ BO_ 2566764286 "SPN Support
This message is used to identify those SPNs supported by the product for freeze frames and data stream messages.";
CM_ SG_ 2566764286 SPNSupported1High "This parameter defines the SPN(s) that is/are supported for the freeze frame and/or data stream information.";
CM_ SG_ 2566764286 SPNSupportTypeSTR3 "This parameter defines whether the applicable parameter (that is the SPN) is supported in the freeze frame, the data stream or both the freeze frame and data stream.";
CM_ SG_ 2566764286 SPNSupportTypeSTR2 "This parameter defines whether the applicable parameter (that is the SPN) is supported in the freeze frame, the data stream or both the freeze frame and data stream.";
CM_ SG_ 2566764286 SPNSupportTypeEFF3 "This parameter defines whether the applicable parameter (that is the SPN) is supported in the freeze frame, the data stream or both the freeze frame and data stream.";
CM_ SG_ 2566764286 SPNSupportTypeEFF2 "This parameter defines whether the applicable parameter (that is the SPN) is supported in the freeze frame, the data stream or both the freeze frame and data stream.";
CM_ SG_ 2566764286 SPNSupportTypeDS3 "This parameter defines whether the applicable parameter (that is the SPN) is supported in the freeze frame, the data stream or both the freeze frame and data stream.";
CM_ SG_ 2566764286 SPNSupportTypeDS2 "This parameter defines whether the applicable parameter (that is the SPN) is supported in the freeze frame, the data stream or both the freeze frame and data stream.";
CM_ SG_ 2566764286 SPNSupported3High "This parameter defines the SPN(s) that is/are supported for the freeze frame and/or data stream information.";
CM_ SG_ 2566764286 SPNSupported2High "This parameter defines the SPN(s) that is/are supported for the freeze frame and/or data stream information.";
CM_ SG_ 2566764286 SPNSupported3 "This parameter defines the SPN(s) that is/are supported for the freeze frame and/or data stream information.";
CM_ SG_ 2566764286 SPNSupported2 "This parameter defines the SPN(s) that is/are supported for the freeze frame and/or data stream information.";
CM_ SG_ 2566764286 SPNDataLength3 "The number of data bytes associated with the SPN in the Freeze Frame.";
CM_ SG_ 2566764286 SPNSupportTypeSTR1 "This parameter defines whether the applicable parameter (that is the SPN) is supported in the Scaled Test Results message, DM30.";
CM_ SG_ 2566764286 SPNSupportTypeDS1 "This parameter defines whether the applicable parameter (that is the SPN) is supported in the Data Stream messages.";
CM_ SG_ 2566764286 SPNSupportTypeEFF1 "This parameter defines whether the applicable parameter (that is the SPN) is supported in the expanded freeze frame message, DM25.";
CM_ SG_ 2566764286 SPNDataLength2 "The number of data bytes associated with the SPN in the Freeze Frame.";
CM_ SG_ 2566764286 SPNDataLength1 "The number of data bytes associated with the SPN in the Freeze Frame.
The SPN data length is required to ensure old and new OBD tool compatibility with vehicle OBD Systems.  For instance, if the vehicle supports a new SPN then the tool will know ...";
CM_ SG_ 2566764286 SPNSupported1 "This parameter defines the SPN(s) that is/are supported for the freeze frame and/or data stream information.";
CM_ BO_ 2566764030 "Previously Active Emission Related Faults
This message contains DTCs that are confirmed but for which the MIL is off.";
CM_ SG_ 2566764030 SPN_High4 "3 most significant bits of SPN (most significant at bit 8) ";
CM_ SG_ 2566764030 SPN_High3 "3 most significant bits of SPN (most significant at bit 8) ";
CM_ SG_ 2566764030 SPN_High5 "3 most significant bits of SPN (most significant at bit 8) ";
CM_ SG_ 2566764030 SPN_High2 "3 most significant bits of SPN (most significant at bit 8) ";
CM_ SG_ 2566764030 SPN_High1 "3 most significant bits of SPN (most significant at bit 8) ";
CM_ SG_ 2566764030 SpnConversionMethod1 "If set to '0', the document is converted according to version 4 of the J1939-73 document (February 1996); otherwise, it is converted according to one of the three earlier versions.";
CM_ SG_ 2566764030 SpnConversionMethod5 "If set to '0', the document is converted according to version 4 of the J1939-73 document (February 1996); otherwise, it is converted according to one of the three earlier versions.";
CM_ SG_ 2566764030 SpnConversionMethod4 "If set to '0', the document is converted according to version 4 of the J1939-73 document (February 1996); otherwise, it is converted according to one of the three earlier versions.";
CM_ SG_ 2566764030 SpnConversionMethod3 "If set to '0', the document is converted according to version 4 of the J1939-73 document (February 1996); otherwise, it is converted according to one of the three earlier versions.";
CM_ SG_ 2566764030 SpnConversionMethod2 "If set to '0', the document is converted according to version 4 of the J1939-73 document (February 1996); otherwise, it is converted according to one of the three earlier versions.";
CM_ SG_ 2566764030 OccurenceCount5 "Contains the number of times a fault has been independently detected.";
CM_ SG_ 2566764030 OccurenceCount4 "Contains the number of times a fault has been independently detected.";
CM_ SG_ 2566764030 OccurenceCount3 "Contains the number of times a fault has been independently detected.";
CM_ SG_ 2566764030 OccurenceCount2 "Contains the number of times a fault has been independently detected.";
CM_ SG_ 2566764030 OccurenceCount1 "Contains the number of times a fault has been independently detected.";
CM_ SG_ 2566764030 FMI5 "The FMI defines the type of failure detected in the subsystem identified by an SPN.";
CM_ SG_ 2566764030 FMI4 "The FMI defines the type of failure detected in the subsystem identified by an SPN.";
CM_ SG_ 2566764030 FMI3 "The FMI defines the type of failure detected in the subsystem identified by an SPN.";
CM_ SG_ 2566764030 FMI2 "The FMI defines the type of failure detected in the subsystem identified by an SPN.";
CM_ SG_ 2566764030 FMI1 "The FMI defines the type of failure detected in the subsystem identified by an SPN.";
CM_ SG_ 2566764030 FlashRedStopLamp "This parameter provides the capability to flash the RSL


00 - Slow Flash (1 Hz, 50 % duty cycle)
01 - Fast Flash (2 Hz or faster, 50% duty cycle)
10 - Reserved
11 - Unavailable / Do Not Flash";
CM_ SG_ 2566764030 FlashProtectLamp "This parameter provides the capability to flash the engine protect lamp


00 - Slow Flash (1 Hz, 50 % duty cycle)
01 - Fast Flash (2 Hz or faster, 50% duty cycle)
10 - Reserved
11 - Unavailable / Do Not Flash";
CM_ SG_ 2566764030 FlashMalfuncIndicatorLamp "This parameter provides the capability to flash the MIL
00 - Slow Flash (1 Hz, 50 % duty cycle)
01 - Fast Flash (2 Hz or faster, 50% duty cycle)
10 - Class C DTC
11 - Unavailable / Do Not Flash
Note:  State 10 is for WWH OBD discriminatory ...";
CM_ SG_ 2566764030 FlashAmberWarningLamp "This parameter provides the capability to flash the AWL

00 - Slow Flash (1 Hz, 50 % duty cycle)
01 - Fast Flash (2 Hz or faster, 50% duty cycle)
10 - Reserved
11 - Unavailable / Do Not Flash";
CM_ SG_ 2566764030 MalfunctionIndLampStatus "A lamp used to relay only emissions-related trouble code information. This lamp is only illuminated when there is an emission-related trouble code active.
00     Lamp Off
01     Lamp On
10     Short MIL for WWH OBD
11     Not available
Note ...";
CM_ SG_ 2566764030 AmberWarningLampStatus "This lamp is used to relay trouble code information that is reporting a problem with the vehicle system but the vehicle need not be immediately stopped. 

00     Lamp Off
01     Lamp On
10     Reserved
11     Not available";
CM_ SG_ 2566764030 RedStopLampState "This lamp is used to relay trouble code information that is of a severe enough condition that it warrants stopping the vehicle.

00     Lamp Off
01     Lamp On
10     Reserved
11     Not available";
CM_ SG_ 2566764030 ProtectLampStatus "This lamp is used to relay trouble code information that is reporting a problem with a vehicle system that is most probably not electronic subsystem related. For instance, engine coolant temperature is exceeding its prescribed temperature range.
00 ...";
CM_ SG_ 2566764030 SPN5 "16 least significant bits of SPN";
CM_ SG_ 2566764030 SPN4 "16 least significant bits of SPN";
CM_ SG_ 2566764030 SPN3 "16 least significant bits of SPN";
CM_ SG_ 2566764030 SPN2 "16 least significant bits of SPN";
CM_ SG_ 2566764030 SPN1 "16 least significant bits of SPN";
CM_ BO_ 2562981630 "Individual Clear/Reset Of Active And Previously Active DTC
All of the diagnostic information pertaining to the specified diagnostic trouble code should be erased when the CLR_PA_REQ or CLR_ACT_REQ action of this PG is requested.";
CM_ SG_ 2562981630 SPN "16 least significant bits of SPN";
CM_ SG_ 2562981630 ControlByte "Individual DTC Clear/Reset Control Byte 
A numeric indication of the message function and content within the individual DTC clear message.";
CM_ SG_ 2562981630 CtrlByteSpecificIndicator "Control Byte Specific Indicator for Individual DTC Clear 
A numeric value with interpretation that is specific to the control byte value within the individual DTC clear message. ";
CM_ SG_ 2562981630 FMI "Failure Mode Identifier (FMI) 
The FMI defines the type of failure detected in the sub-system identified by an SPN.";
CM_ SG_ 2562981630 SPN_High "3 most significant bits of SPN (most significant at bit 8) ";
CM_ BO_ 2562850558 "Diagnostic Readiness 2
Message to convey information relevant to the readiness of the OBD system.";
CM_ SG_ 2562850558 TimeSinceDTCsCleared "Time accumulated since DTCs were cleared (via an external test equipment or possibly, a battery disconnect).";
CM_ SG_ 2562850558 MinutesAccumulatedMILActivated "Accumulated count (in minutes) while the MIL is activated (on).
For US, Euro IV and Euro V implementations, conditions include:
- Reset to 0x0000 when MIL state changes from deactivated to activated by this ECU
- Accumulate counts in minutes if ...";
CM_ SG_ 2562850558 DistanceSinceDTCsCleared "Distance accumulated since DTCs were cleared (via an external test equipment or possibly, a battery disconnect).";
CM_ SG_ 2562850558 DistanceWhileMILisActivated "The kilometers accumulated while the MIL is activated.";
CM_ BO_ 2562916094 "Monitor Performance Ratio
Legislated On-Board Diagnostics requirements specify that manufacturers must monitor all emission and OBD system related components throughout the expected life of the vehicle.";
CM_ SG_ 2562916094 ApplSysMonitorDenominator "Identifies the number of times a vehicle has been operated that constitues a driving cycle where the Applicable System Monitor could be operated per regulatory requirements.";
CM_ SG_ 2562916094 ApplSysMonitorNumerator "Idenitifes the number of times the vehicle has been operated such that all conditions necessary for the Applicable System Monitor to detect a malfunction have been encountered.";
CM_ SG_ 2562916094 SpnOfApplSysMonitor "Idenifies the SPN of the system monitor for which Monitor ratio is being reported.";
CM_ SG_ 2562916094 OBDMonitoringCondEncountered "Count the number of times that the vehicle has been operated in the specified OBD monitoring conditions.";
CM_ SG_ 2562916094 IgnitionCycleCounter "Count of the number of ignition cycles.";
CM_ BO_ 2564030206 "Calibration Information
Provide information about the calibration to scan tool";
CM_ SG_ 2564030206 CalibrationID1 "Sixteen-byte calibration identification number. Uniquely identifies the software installed in the control module. The calibration ID must be unique, but does not need to be 16 bytes long. If the Calibration ID is less than 16 bytes, those unused ...";
CM_ SG_ 2564030206 CalibrationVerificationNumber "Checksum of entire calibration, including code and data.  Excludes RAM parameters, nonvolatile parameters that change during the life cycle of the module (hours of operation, freeze frame data, etc), or non emissions related parameters that may be ...";
CM_ BO_ 2564095742 "Data Security
The data security parameter group is used to send security entities of a given type and length. These entities are data produced by or used for applications of cryptography and supporting procedures to ensure data security.";
CM_ SG_ 2564095742 DataSecurityParameter "This Parameter is used to send the data for the Data Security message. There are presently four different items defined. The Data Security Parameter shall be sent least significant byte first.";
CM_ SG_ 2564095742 SecurityEntityType "This 4-bit parameter that indicates whether the data in the following Security Entity parameter is to be used as a Long Seed, Long Key, Session Key, or Certificate.";
CM_ SG_ 2564095742 SecurityEntityLength "This 12-bit parameter contains the length, in bytes, of the Data Security Parameter.";
CM_ BO_ 2564226814 "Boot Load Data
Used primarily to load boot data/program into a device when a memory access boot load command has been issued.";
CM_ SG_ 2564226814 BootLoadData "This is a 1-byte parameter using the same SLOT as the Raw Binary Data. There shall be 8 occurrences of this parameter in the message. The meaning of this parameter is proprietary. The structure used to reference the program and verify the data is ...";
CM_ BO_ 2564292350 "Binary Data Transfer
Used primarily to transfer data for the memory access commands.";
CM_ SG_ 2564292350 RawBinaryData "This is a 1-byte parameter representing the value for 1 byte of memory. It can have any value between 0 and 255 (0 and 0xFF) with no reserved values.
";
CM_ SG_ 2564292350 NumberOfOccurance "This is an 8-bit (1-byte) parameter to be sent within the Binary Data Transfer PGN to provide information on the number of Raw Binary Data parameters which will follow when the message is single packet. Its value is between 1 and 7 when the Binary ...";
CM_ BO_ 2564357886 "Memory Access Response
The main use for the Memory_Access_Response is for a device to answer a tool which has attempted to access the memory within the device.";
CM_ SG_ 2564357886 NumberAllowed "When the Status of the Memory Access Response message is a Proceed, an 11-bit parameter identifies the amount of memory (i.e. the range of memory) over which the Device is willing to allow a particular operation to be carried out. For ‘Proceed’ the ...";
CM_ SG_ 2564357886 Seed "This is a 16-bit parameter which is used by the Device primarily to send a Seed to a Tool, when using a Seed/Key type security system. It is also used by the Device to signal the Tool that the Device is satisfied that a complete Key has been ...";
CM_ SG_ 2564357886 EDCP_Extension "This is an 8-bit parameter used to identify how to handle the data in the Error Indicator/ EDC Parameter. This EDCP Extension parameter is used within the Memory Access Response message (Device to Tool). Meaning must be determined from a table of ...";
CM_ SG_ 2564357886 ErrorIndicator "This is a 24-bit parameter which has two uses. One is to transfer a checksum, CRC or other type of EDC parameter (or any segment thereof) from a device to a Tool within the Memory Access Response message. The second use is to send an Error Indicator ...";
CM_ SG_ 2564357886 Status "This is a 3-bit parameter which allows the Device to return its Status. All Memory Access Requests originate at a Tool and are considered Commands. All Memory Access Responses originate at a Device and are considered Status. The device may choose to ...";
CM_ BO_ 2564423422 "Memory Access Request
The main use for the Memory_Access_Request message is by a tool wishing to alter the memory of a device.";
CM_ SG_ 2564423422 KeyOrUserLevel "This is a 2-byte parameter which is used by the Tool to primarily send a Key to the Device, but which can also be used by the Tool to provide a Password or a User_Level to the Device if desired (see  APPENDIX C).  This Key/User_Level parameter can ...";
CM_ SG_ 2564423422 PointerExtension "This parameter is either the high order 8 bits of a complete direct memory address or the identifier of a particular spacial address.";
CM_ SG_ 2564423422 Pointer "If Pointer Type 0 is used, this 24-bit parameter, which has a value of 0 to 16,777,215 (0 to 0xFFFFFF) with no reserved ranges, is concatenated with the 8-bit Pointer Extension to form a direct memory address. The address thus formed represents the ...";
CM_ SG_ 2564423422 Command "This is a 3-bit parameter which allows the Tool to send Commands to the Device. All Memory Access Requests originate at a Tool and are considered Commands. Some of the values within the Command have been overlaid with the same values in Status so ...";
CM_ SG_ 2564423422 PointerType "Indicates whether the Pointer and Pointer Extension are direct memory addresses (Pointer Type identifier = 0) or if the Pointer Extension is identifying a particular SPACE with the Pointer referencing a specific OBJECT within that particular SPACE ...";
CM_ SG_ 2564423422 NumberRequested "This is an 11-bit parameter which identifies the amount of memory (i.e. the range within the memory) over which the Tool desires an operation to be carried out when the Command of the Memory Access Request message is a Read, Write, Boot Load, or ...";
CM_ SG_ 2564423422 NumberRequestedHigh "Length/Number Requested";
CM_ BO_ 2564816638 "Stop Start Broadcast
This message is used to stop or start broadcast messages. These broadcast messages may be on networks other than SAE J1939.";
CM_ SG_ 2564816638 ProprietaryNetwork2 "Identifies the action to be performed on the Proprietary Network #2 communications port.

00 Stop Broadcast
01 Start Broadcast
10 Reserved
11 Don’t Care/take no action (leave as is)";
CM_ SG_ 2564816638 ProprietaryNetwork1 "Identifies the action to be performed on the Proprietary Network #1 communications port.

00 Stop Broadcast
01 Start Broadcast
10 Reserved
11 Don’t Care/take no action (leave as is)";
CM_ SG_ 2564816638 J1939Network4 "Identifies the action to be performed on the J1939 Network #4 communications port.

00 Stop Broadcast
01 Start Broadcast
10 Reserved
11 Don’t Care/take no action (leave as is)";
CM_ SG_ 2564816638 HoldSignal "Indicator to all nodes that the communication ports that have been acted upon by the Stop Start Broadcast PGN are remaining in the modified state. Therefore all nodes should act accordingly. The Hold signal is required to be broadcast every 5 ...";
CM_ SG_ 2564816638 J1939Network3 "Identifies the action to be performed on the J1939 Network #3 communications port.

00 Stop Broadcast
01 Start Broadcast
10 Reserved
11 Don’t Care/take no action (leave as is)";
CM_ SG_ 2564816638 J1939Network2 "Identifies the action to be performed on the J1939 Network #2 communications port.

00 Stop Broadcast
01 Start Broadcast
10 Reserved
11 Don’t Care/take no action (leave as is)";
CM_ SG_ 2564816638 ISO9141 "Identifies the action to be performed on the ISO 9141 communications port.

00 Stop Broadcast
01 Start Broadcast
10 Reserved
11 Don’t Care/take no action (leave as is)";
CM_ SG_ 2564816638 SAE_J1850 "Identifies the action to be performed on the J1850 communications port.

00 Stop Broadcast
01 Start Broadcast
10 Reserved
11 Don’t Care/take no action (leave as is)";
CM_ SG_ 2564816638 ManufacturerSpecificPort "Identifies the action to be performed on the “Other, Manufacture Specified Port” communications port.

00 Stop Broadcast
01 Start Broadcast
10 Reserved
11 Don’t Care/take no action (leave as is)";
CM_ SG_ 2564816638 CurrentDataLink "Identifies the action to be performed on the communications port that this parameter was received on.

00 Stop Broadcast
01 Start Broadcast
10 Reserved
11 Don’t Care/take no action (leave as is)";
CM_ SG_ 2564816638 SAE_J1587 "Identifies the action to be performed on the J1587 communications port.

00 Stop Broadcast
01 Start Broadcast
10 Reserved
11 Don’t Care/take no action (leave as is)";
CM_ SG_ 2564816638 SAE_J1922 "Identifies the action to be performed on the J1922 communications port.
00 Stop Broadcast
01 Start Broadcast
10 Reserved
11 Don’t Care/take no action (leave as is)";
CM_ SG_ 2564816638 J1939Network1 "Identifies the action to be performed on the J1939 Network #1, Primary Vehicle Network” communications port.
00 Stop Broadcast
01 Start Broadcast
10 Reserved
11 Don’t Care/take no action (leave as is)";
CM_ SG_ 2564816638 SuspendSignal "Indicator to all nodes that the current communication port broadcast messages are being suspended due to commands other than J1939 DM13. Therefore, the receiving nodes should suspend timeout diagnostics for all messages from the transmitting device ...";
CM_ SG_ 2564816638 SuspendDuration "Indicates the duration of a suspension of broadcast messages when that duration is known by the transmitting device. If the DM13 message is sent with thee suspend signal value of 2 or 3, the value of this parameter will represent the duration of ...";
CM_ BO_ 2566837502 "Emissions Related Active DTCs
The information communicated is limited to the currently active emission-related diagnostic trouble codes preceded by the diagnostic lamp status.";
CM_ SG_ 2566837502 SPN_High4 "3 most significant bits of SPN (most significant at bit 8) ";
CM_ SG_ 2566837502 SPN_High3 "3 most significant bits of SPN (most significant at bit 8) ";
CM_ SG_ 2566837502 SPN_High5 "3 most significant bits of SPN (most significant at bit 8) ";
CM_ SG_ 2566837502 SPN_High2 "3 most significant bits of SPN (most significant at bit 8) ";
CM_ SG_ 2566837502 SPN_High1 "3 most significant bits of SPN (most significant at bit 8) ";
CM_ SG_ 2566837502 SpnConversionMethod1 "If set to '0', the document is converted according to version 4 of the J1939-73 document (February 1996); otherwise, it is converted according to one of the three earlier versions.";
CM_ SG_ 2566837502 SpnConversionMethod5 "If set to '0', the document is converted according to version 4 of the J1939-73 document (February 1996); otherwise, it is converted according to one of the three earlier versions.";
CM_ SG_ 2566837502 SpnConversionMethod4 "If set to '0', the document is converted according to version 4 of the J1939-73 document (February 1996); otherwise, it is converted according to one of the three earlier versions.";
CM_ SG_ 2566837502 SpnConversionMethod3 "If set to '0', the document is converted according to version 4 of the J1939-73 document (February 1996); otherwise, it is converted according to one of the three earlier versions.";
CM_ SG_ 2566837502 SpnConversionMethod2 "If set to '0', the document is converted according to version 4 of the J1939-73 document (February 1996); otherwise, it is converted according to one of the three earlier versions.";
CM_ SG_ 2566837502 OccurenceCount5 "Contains the number of times a fault has been independently detected.";
CM_ SG_ 2566837502 OccurenceCount4 "Contains the number of times a fault has been independently detected.";
CM_ SG_ 2566837502 OccurenceCount3 "Contains the number of times a fault has been independently detected.";
CM_ SG_ 2566837502 OccurenceCount2 "Contains the number of times a fault has been independently detected.";
CM_ SG_ 2566837502 OccurenceCount1 "Contains the number of times a fault has been independently detected.";
CM_ SG_ 2566837502 FMI5 "The FMI defines the type of failure detected in the subsystem identified by an SPN.";
CM_ SG_ 2566837502 FMI4 "The FMI defines the type of failure detected in the subsystem identified by an SPN.";
CM_ SG_ 2566837502 FMI3 "The FMI defines the type of failure detected in the subsystem identified by an SPN.";
CM_ SG_ 2566837502 FMI2 "The FMI defines the type of failure detected in the subsystem identified by an SPN.";
CM_ SG_ 2566837502 FMI1 "The FMI defines the type of failure detected in the subsystem identified by an SPN.";
CM_ SG_ 2566837502 FlashRedStopLamp "This parameter provides the capability to flash the RSL


00 - Slow Flash (1 Hz, 50 % duty cycle)
01 - Fast Flash (2 Hz or faster, 50% duty cycle)
10 - Reserved
11 - Unavailable / Do Not Flash";
CM_ SG_ 2566837502 FlashProtectLamp "This parameter provides the capability to flash the engine protect lamp


00 - Slow Flash (1 Hz, 50 % duty cycle)
01 - Fast Flash (2 Hz or faster, 50% duty cycle)
10 - Reserved
11 - Unavailable / Do Not Flash";
CM_ SG_ 2566837502 FlashMalfuncIndicatorLamp "This parameter provides the capability to flash the MIL
00 - Slow Flash (1 Hz, 50 % duty cycle)
01 - Fast Flash (2 Hz or faster, 50% duty cycle)
10 - Class C DTC
11 - Unavailable / Do Not Flash
Note:  State 10 is for WWH OBD discriminatory ...";
CM_ SG_ 2566837502 FlashAmberWarningLamp "This parameter provides the capability to flash the AWL

00 - Slow Flash (1 Hz, 50 % duty cycle)
01 - Fast Flash (2 Hz or faster, 50% duty cycle)
10 - Reserved
11 - Unavailable / Do Not Flash";
CM_ SG_ 2566837502 MalfunctionIndLampStatus "A lamp used to relay only emissions-related trouble code information. This lamp is only illuminated when there is an emission-related trouble code active.
00     Lamp Off
01     Lamp On
10     Short MIL for WWH OBD
11     Not available
Note ...";
CM_ SG_ 2566837502 AmberWarningLampStatus "This lamp is used to relay trouble code information that is reporting a problem with the vehicle system but the vehicle need not be immediately stopped. 

00     Lamp Off
01     Lamp On
10     Reserved
11     Not available";
CM_ SG_ 2566837502 RedStopLampState "This lamp is used to relay trouble code information that is of a severe enough condition that it warrants stopping the vehicle.

00     Lamp Off
01     Lamp On
10     Reserved
11     Not available";
CM_ SG_ 2566837502 ProtectLampStatus "This lamp is used to relay trouble code information that is reporting a problem with a vehicle system that is most probably not electronic subsystem related. For instance, engine coolant temperature is exceeding its prescribed temperature range.
00 ...";
CM_ SG_ 2566837502 SPN5 "16 least significant bits of SPN";
CM_ SG_ 2566837502 SPN4 "16 least significant bits of SPN";
CM_ SG_ 2566837502 SPN3 "16 least significant bits of SPN";
CM_ SG_ 2566837502 SPN2 "16 least significant bits of SPN";
CM_ SG_ 2566837502 SPN1 "16 least significant bits of SPN";
CM_ BO_ 2566837246 "Diagnostic Data Clear/Reset for Active DTCs
All of the diagnostic information pertaining to the active diagnostic trouble codes should be erased. Sent as a request whenever the service tool wishes to clear/reset diagnostic data for active DTCs.";
CM_ BO_ 2566836990 "Non-continuously Monitored System Test Identifiers Support
The purpose of this PG is to report the list of non-continuously monitored systems tests supported by the controller.";
CM_ SG_ 2566836990 TestIdentifierSupported "Indicates the test identifiers that the controller supports. Each bit is assigned to one test. Therefore, we can have up to 64 tests without having to use the transport protocol of SAE J1939-21. The assignment of a given test identifier to a given ...";
CM_ BO_ 2566836734 "Oxygen Sensor Test Results
SAE J1939 will not specify an implementation for this DM.  Oxygen sensor test and results should be communicated using DM7 and DM8";
CM_ BO_ 2566836478 "Test Results for Non-continuously Monitored Systems
The purpose of this response PG is to report the test results for one of the non-continuously monitored tests invoked using DM7";
CM_ SG_ 2566836478 TestLimitMinimum "The test value must be greater than or equal to Test Limit Minimum in order for the test to pass.";
CM_ SG_ 2566836478 TestLimitMaximum "The test value must be less than or equal to Test Limit Maximum in order for the test to pass.";
CM_ SG_ 2566836478 TestValue "The test value collected during the test. If the test performed does not have both a test limit minimum and maximum, then the appropriate limit value (Maximum or Minimum) should be set to all ones. SAE J1939-71 defines this to mean not available.";
CM_ SG_ 2566836478 TestType "This parameter identifies the non-continuously monitored component identifier that was tested. These component identifiers are defined by the manufacturer. They are necessary when multiple components or systems are present on the vehicle and have ...";
CM_ SG_ 2566836478 TestIdentifier "The TID has 2 methods to designate the test to be run. The first method uses the TID alone and these test identifiers are manufacturer-defined test identifiers. For this first use there are 64 valid test identifiers, 1 to 64. The second method uses ...";
CM_ BO_ 2565078782 "Command Non-continuously Monitored Test
The purpose of this command in the diagnostic process is to provide the ability to command On-Board Diagnostic monitoring tests of specific components/ systems that are not continuously monitored";
CM_ SG_ 2565078782 SPN_High "3 most significant bits of SPN (most significant at bit 8) ";
CM_ SG_ 2565078782 SPN "16 least significant bits of SPN";
CM_ SG_ 2565078782 TestIdentifier "The TID has 2 methods to designate the test to be run. The first method uses the TID alone and these test identifiers are manufacturer-defined test identifiers. For this first use there are 64 valid test identifiers, 1 to 64. The second method uses ...";
CM_ SG_ 2565078782 FMI "This parameter identifies the failure mode identifier which represents the test(s) that shall be run on the component / system that will be tested.";
BA_DEF_ SG_  "SigType" ENUM  "Default","Range","RangeSigned","ASCII","Discrete","Control","ReferencePGN","DTC","StringDelimiter","StringLength","StringLengthControl","MessageCounter","MessageChecksum","LowerPartOfSPN";
BA_DEF_ SG_  "GenSigStartValue" INT 0 10000;
BA_DEF_ SG_  "GenSigSendType" ENUM  "Cyclic","OnWrite","OnWriteWithRepetition","OnChange","OnChangeWithRepetition","IfActive","IfActiveWithRepetition","NoSigSendType";
BA_DEF_ SG_  "GenSigILSupport" ENUM  "No","Yes";
BA_DEF_ SG_  "GenSigEVName" STRING ;
BA_DEF_ SG_  "SPN" INT 0 524287;
BA_DEF_ BO_  "GenMsgStartDelayTime" INT 0 100000;
BA_DEF_ BO_  "GenMsgILSupport" ENUM  "No","Yes";
BA_DEF_ BO_  "GenMsgDelayTime" INT 0 1000;
BA_DEF_ BO_  "GenMsgRequestable" INT 0 1;
BA_DEF_ BO_  "GenMsgSendType" ENUM  "cyclic","NotUsed","NotUsed","NotUsed","NotUsed","NotUsed","NotUsed","IfActive","noMsgSendType";
BA_DEF_ BO_  "VFrameFormat" ENUM  "StandardCAN","ExtendedCAN","reserved","J1939PG";
BA_DEF_ BO_  "GenMsgCycleTime" INT 0 3600000;
BA_DEF_ SG_  "SystemSignalLongSymbol" STRING ;
BA_DEF_DEF_  "SigType" "Default";
BA_DEF_DEF_  "GenSigStartValue" 0;
BA_DEF_DEF_  "GenSigSendType" "NoSigSendType";
BA_DEF_DEF_  "GenSigILSupport" "Yes";
BA_DEF_DEF_  "GenSigEVName" "Env@Nodename_@Signame";
BA_DEF_DEF_  "SPN" 0;
BA_DEF_DEF_  "GenMsgStartDelayTime" 0;
BA_DEF_DEF_  "GenMsgILSupport" "Yes";
BA_DEF_DEF_  "GenMsgDelayTime" 0;
BA_DEF_DEF_  "GenMsgRequestable" 1;
BA_DEF_DEF_  "GenMsgSendType" "noMsgSendType";
BA_DEF_DEF_  "VFrameFormat" "J1939PG";
BA_DEF_DEF_  "GenMsgCycleTime" 0;
BA_DEF_DEF_  "SystemSignalLongSymbol" "";
BA_ "SPN" SG_ 2566742014 SpnConversionMethod1 1706;
BA_ "SPN" SG_ 2566742014 SpnConversionMethod5 1706;
BA_ "SPN" SG_ 2566742014 SpnConversionMethod4 1706;
BA_ "SPN" SG_ 2566742014 SpnConversionMethod3 1706;
BA_ "SPN" SG_ 2566742014 SpnConversionMethod2 1706;
BA_ "SPN" SG_ 2566742014 OccurenceCount5 1216;
BA_ "SPN" SG_ 2566742014 OccurenceCount4 1216;
BA_ "SPN" SG_ 2566742014 OccurenceCount3 1216;
BA_ "SPN" SG_ 2566742014 OccurenceCount2 1216;
BA_ "SPN" SG_ 2566742014 OccurenceCount1 1216;
BA_ "SPN" SG_ 2566742014 FMI5 4149;
BA_ "SPN" SG_ 2566742014 FMI4 4149;
BA_ "SPN" SG_ 2566742014 FMI3 4149;
BA_ "SPN" SG_ 2566742014 FMI2 4149;
BA_ "SPN" SG_ 2566742014 FMI1 4149;
BA_ "SigType" SG_ 2566742014 FlashRedStopLamp 5;
BA_ "SPN" SG_ 2566742014 FlashRedStopLamp 3039;
BA_ "SigType" SG_ 2566742014 FlashProtectLamp 5;
BA_ "SPN" SG_ 2566742014 FlashProtectLamp 3041;
BA_ "SigType" SG_ 2566742014 FlashMalfuncIndicatorLamp 5;
BA_ "SPN" SG_ 2566742014 FlashMalfuncIndicatorLamp 3038;
BA_ "SigType" SG_ 2566742014 FlashAmberWarningLamp 5;
BA_ "SPN" SG_ 2566742014 FlashAmberWarningLamp 3040;
BA_ "SigType" SG_ 2566742014 MalfunctionIndLampStatus 5;
BA_ "SPN" SG_ 2566742014 MalfunctionIndLampStatus 1213;
BA_ "SigType" SG_ 2566742014 AmberWarningLampStatus 5;
BA_ "SPN" SG_ 2566742014 AmberWarningLampStatus 624;
BA_ "SigType" SG_ 2566742014 RedStopLampState 4;
BA_ "SPN" SG_ 2566742014 RedStopLampState 623;
BA_ "SigType" SG_ 2566742014 ProtectLampStatus 5;
BA_ "SPN" SG_ 2566742014 ProtectLampStatus 987;
BA_ "SigType" SG_ 2566742014 SPN5 13;
BA_ "SigType" SG_ 2566742014 SPN4 13;
BA_ "SigType" SG_ 2566742014 SPN3 13;
BA_ "SigType" SG_ 2566742014 SPN2 13;
BA_ "SigType" SG_ 2566742014 SPN1 13;
BA_ "SigType" SG_ 2566742270 FailureSpecificB1Counter4 1;
BA_ "SPN" SG_ 2566742270 FailureSpecificB1Counter4 4147;
BA_ "SigType" SG_ 2566742270 FailureSpecificB1Counter3 1;
BA_ "SPN" SG_ 2566742270 FailureSpecificB1Counter3 4147;
BA_ "SigType" SG_ 2566742270 FailureSpecificB1Counter2 1;
BA_ "SPN" SG_ 2566742270 FailureSpecificB1Counter2 4147;
BA_ "SigType" SG_ 2566742270 SPN4 13;
BA_ "SPN" SG_ 2566742270 SPN4 1214;
BA_ "SigType" SG_ 2566742270 SPN3 13;
BA_ "SPN" SG_ 2566742270 SPN3 1214;
BA_ "SigType" SG_ 2566742270 SPN2 13;
BA_ "SPN" SG_ 2566742270 SPN2 1214;
BA_ "SPN" SG_ 2566742270 FMI4 1215;
BA_ "SPN" SG_ 2566742270 FMI3 1215;
BA_ "SPN" SG_ 2566742270 FMI2 1215;
BA_ "SigType" SG_ 2566742270 SPN1 13;
BA_ "SPN" SG_ 2566742270 SPN1 1214;
BA_ "SPN" SG_ 2566742270 FMI1 1215;
BA_ "SigType" SG_ 2566742270 FailureSpecificB1Counter1 1;
BA_ "SPN" SG_ 2566742270 FailureSpecificB1Counter1 4147;
BA_ "SigType" SG_ 2566742526 SysGreatestB1Counter 1;
BA_ "SPN" SG_ 2566742526 SysGreatestB1Counter 4146;
BA_ "SigType" SG_ 2566742526 SysCumulativeContinuousMITime 1;
BA_ "SPN" SG_ 2566742526 SysCumulativeContinuousMITime 4145;
BA_ "SigType" SG_ 2566742782 RegulationDescription 8;
BA_ "SPN" SG_ 2566742782 RegulationDescription 4144;
BA_ "SigType" SG_ 2566743038 SysIncompleteMonitorCount 1;
BA_ "SPN" SG_ 2566743038 SysIncompleteMonitorCount 4143;
BA_ "SPN" SG_ 2566743038 SysMalIndActivationMode 4142;
BA_ "SigType" SG_ 2566743038 SysMalIndDisplayStrategy 4;
BA_ "SPN" SG_ 2566743038 SysMalIndDisplayStrategy 4141;
BA_ "SigType" SG_ 2566743038 SysContinuousMalfunctionInd 4;
BA_ "SPN" SG_ 2566743038 SysContinuousMalfunctionInd 4140;
BA_ "SigType" SG_ 2566743038 SysNonRoadworthyCompCount 1;
BA_ "SPN" SG_ 2566743038 SysNonRoadworthyCompCount 4139;
BA_ "SigType" SG_ 2566743294 VehicleCurrentMIAccumTime 1;
BA_ "SPN" SG_ 2566743294 VehicleCurrentMIAccumTime 4138;
BA_ "SigType" SG_ 2566743294 VehicleIncompleteMonitorCount 1;
BA_ "SPN" SG_ 2566743294 VehicleIncompleteMonitorCount 4137;
BA_ "SigType" SG_ 2566743294 VehicleMalfunctionIndActMode 4;
BA_ "SPN" SG_ 2566743294 VehicleMalfunctionIndActMode 4136;
BA_ "SigType" SG_ 2566743294 VehicleMalfunctionIndStrategy 4;
BA_ "SPN" SG_ 2566743294 VehicleMalfunctionIndStrategy 4135;
BA_ "SigType" SG_ 2566743294 VehicleContinuousMalfunctionInd 4;
BA_ "SPN" SG_ 2566743294 VehicleContinuousMalfunctionInd 4134;
BA_ "SigType" SG_ 2566743294 VehicleNonRoadworthyCompCount 1;
BA_ "SPN" SG_ 2566743294 VehicleNonRoadworthyCompCount 4133;
BA_ "SPN" SG_ 2560622334 SpnConversionMethod1 1706;
BA_ "SPN" SG_ 2560622334 SpnConversionMethod5 1706;
BA_ "SPN" SG_ 2560622334 SpnConversionMethod4 1706;
BA_ "SPN" SG_ 2560622334 SpnConversionMethod3 1706;
BA_ "SPN" SG_ 2560622334 SpnConversionMethod2 1706;
BA_ "SPN" SG_ 2560622334 OccurenceCount5 1216;
BA_ "SPN" SG_ 2560622334 OccurenceCount4 1216;
BA_ "SPN" SG_ 2560622334 OccurenceCount3 1216;
BA_ "SPN" SG_ 2560622334 OccurenceCount2 1216;
BA_ "SPN" SG_ 2560622334 OccurenceCount1 1216;
BA_ "SPN" SG_ 2560622334 FMI5 4149;
BA_ "SPN" SG_ 2560622334 FMI4 4149;
BA_ "SPN" SG_ 2560622334 FMI3 4149;
BA_ "SPN" SG_ 2560622334 FMI2 4149;
BA_ "SPN" SG_ 2560622334 FMI1 4149;
BA_ "SigType" SG_ 2560622334 FlashRedStopLamp 5;
BA_ "SPN" SG_ 2560622334 FlashRedStopLamp 3039;
BA_ "SigType" SG_ 2560622334 FlashProtectLamp 5;
BA_ "SPN" SG_ 2560622334 FlashProtectLamp 3041;
BA_ "SigType" SG_ 2560622334 FlashMalfuncIndicatorLamp 5;
BA_ "SPN" SG_ 2560622334 FlashMalfuncIndicatorLamp 3038;
BA_ "SigType" SG_ 2560622334 FlashAmberWarningLamp 5;
BA_ "SPN" SG_ 2560622334 FlashAmberWarningLamp 3040;
BA_ "SigType" SG_ 2560622334 MalfunctionIndLampStatus 5;
BA_ "SPN" SG_ 2560622334 MalfunctionIndLampStatus 1213;
BA_ "SigType" SG_ 2560622334 AmberWarningLampStatus 5;
BA_ "SPN" SG_ 2560622334 AmberWarningLampStatus 624;
BA_ "SigType" SG_ 2560622334 RedStopLampState 4;
BA_ "SPN" SG_ 2560622334 RedStopLampState 623;
BA_ "SigType" SG_ 2560622334 ProtectLampStatus 5;
BA_ "SPN" SG_ 2560622334 ProtectLampStatus 987;
BA_ "SigType" SG_ 2560622334 SPN5 13;
BA_ "SigType" SG_ 2560622334 SPN4 13;
BA_ "SigType" SG_ 2560622334 SPN3 13;
BA_ "SigType" SG_ 2560622334 SPN2 13;
BA_ "SigType" SG_ 2560622334 SPN1 13;
BA_ "SigType" SG_ 2560687870 PMNTEDeficiencyAreaStatus 4;
BA_ "SPN" SG_ 2560687870 PMNTEDeficiencyAreaStatus 4132;
BA_ "SigType" SG_ 2560687870 MnfcPMNTECarveOutAreaStatus 4;
BA_ "SPN" SG_ 2560687870 MnfcPMNTECarveOutAreaStatus 4131;
BA_ "SPN" SG_ 2560687870 PMNTEControlAreaStatus 4130;
BA_ "SigType" SG_ 2560687870 NOxNTEDeficiencyAreaStatus 4;
BA_ "SPN" SG_ 2560687870 NOxNTEDeficiencyAreaStatus 4129;
BA_ "SigType" SG_ 2560687870 MnfcNOxNTECarveOutAreaStatus 4;
BA_ "SPN" SG_ 2560687870 MnfcNOxNTECarveOutAreaStatus 4128;
BA_ "SPN" SG_ 2560687870 NOxNTEControlAreaStatus 4127;
BA_ "SigType" SG_ 2292317950 AECDEngineHours1Timer2 1;
BA_ "SPN" SG_ 2292317950 AECDEngineHours1Timer2 4126;
BA_ "SigType" SG_ 2292317950 AECDEngineHours1Timer1 1;
BA_ "SPN" SG_ 2292317950 AECDEngineHours1Timer1 4125;
BA_ "SigType" SG_ 2292317950 AECDNumber1 1;
BA_ "SPN" SG_ 2292317950 AECDNumber1 4124;
BA_ "SigType" SG_ 2560818942 DTCTotalPreviouslyActiveTime4 1;
BA_ "SPN" SG_ 2560818942 DTCTotalPreviouslyActiveTime4 4122;
BA_ "SigType" SG_ 2560818942 DTCTotalPreviouslyActiveTime3 1;
BA_ "SPN" SG_ 2560818942 DTCTotalPreviouslyActiveTime3 4122;
BA_ "SigType" SG_ 2560818942 DTCTotalPreviouslyActiveTime2 1;
BA_ "SPN" SG_ 2560818942 DTCTotalPreviouslyActiveTime2 4122;
BA_ "SigType" SG_ 2560818942 DTCTotalActiveTime4 1;
BA_ "SPN" SG_ 2560818942 DTCTotalActiveTime4 4121;
BA_ "SigType" SG_ 2560818942 DTCTotalActiveTime3 1;
BA_ "SPN" SG_ 2560818942 DTCTotalActiveTime3 4121;
BA_ "SigType" SG_ 2560818942 DTCTotalActiveTime2 1;
BA_ "SPN" SG_ 2560818942 DTCTotalActiveTime2 4121;
BA_ "SigType" SG_ 2560818942 DTCTimeUntilDerate4 1;
BA_ "SPN" SG_ 2560818942 DTCTimeUntilDerate4 4123;
BA_ "SigType" SG_ 2560818942 DTCTimeUntilDerate3 1;
BA_ "SPN" SG_ 2560818942 DTCTimeUntilDerate3 4123;
BA_ "SigType" SG_ 2560818942 DTCTimeUntilDerate2 1;
BA_ "SPN" SG_ 2560818942 DTCTimeUntilDerate2 4123;
BA_ "SigType" SG_ 2560818942 SPN4 13;
BA_ "SPN" SG_ 2560818942 SPN4 1214;
BA_ "SigType" SG_ 2560818942 SPN3 13;
BA_ "SPN" SG_ 2560818942 SPN3 1214;
BA_ "SigType" SG_ 2560818942 SPN2 13;
BA_ "SPN" SG_ 2560818942 SPN2 1214;
BA_ "SPN" SG_ 2560818942 FMI4 1215;
BA_ "SPN" SG_ 2560818942 FMI3 1215;
BA_ "SPN" SG_ 2560818942 FMI2 1215;
BA_ "SigType" SG_ 2560818942 SPN1 13;
BA_ "SPN" SG_ 2560818942 SPN1 1214;
BA_ "SPN" SG_ 2560818942 FMI1 1215;
BA_ "SigType" SG_ 2560818942 DTCTimeUntilDerate1 1;
BA_ "SPN" SG_ 2560818942 DTCTimeUntilDerate1 4123;
BA_ "SigType" SG_ 2560818942 DTCTotalPreviouslyActiveTime1 1;
BA_ "SPN" SG_ 2560818942 DTCTotalPreviouslyActiveTime1 4122;
BA_ "SigType" SG_ 2560818942 DTCTotalActiveTime1 1;
BA_ "SPN" SG_ 2560818942 DTCTotalActiveTime1 4121;
BA_ "SPN" SG_ 2560884478 SpnConversionMethod 1706;
BA_ "SPN" SG_ 2560884478 OccurenceCount 1216;
BA_ "SPN" SG_ 2560884478 FMI 1215;
BA_ "SigType" SG_ 2560884478 SPN 13;
BA_ "SPN" SG_ 2560884478 SPN 1214;
BA_ "SigType" SG_ 2560884478 DTCWarnLampSupportStatus 4;
BA_ "SPN" SG_ 2560884478 DTCWarnLampSupportStatus 4115;
BA_ "SigType" SG_ 2560884478 DTCWarnLampSupportFlash 4;
BA_ "SPN" SG_ 2560884478 DTCWarnLampSupportFlash 4119;
BA_ "SigType" SG_ 2560884478 DTCStopLampSupportStatus 4;
BA_ "SPN" SG_ 2560884478 DTCStopLampSupportStatus 4114;
BA_ "SigType" SG_ 2560884478 DTCStopLampSupportFlash 4;
BA_ "SPN" SG_ 2560884478 DTCStopLampSupportFlash 4118;
BA_ "SigType" SG_ 2560884478 DTCProtectLampSupportStatus 4;
BA_ "SPN" SG_ 2560884478 DTCProtectLampSupportStatus 4116;
BA_ "SigType" SG_ 2560884478 DTCProtectLampSupportFlash 4;
BA_ "SPN" SG_ 2560884478 DTCProtectLampSupportFlash 4120;
BA_ "SPN" SG_ 2560884478 DTCMilSupportStatus 4113;
BA_ "SPN" SG_ 2560884478 DTCMilSupportFlash 4117;
BA_ "SigType" SG_ 2560950014 TestLimitMinimum4 1;
BA_ "SPN" SG_ 2560950014 TestLimitMinimum4 4112;
BA_ "SigType" SG_ 2560950014 TestLimitMinimum3 1;
BA_ "SPN" SG_ 2560950014 TestLimitMinimum3 4112;
BA_ "SigType" SG_ 2560950014 TestLimitMinimum2 1;
BA_ "SPN" SG_ 2560950014 TestLimitMinimum2 4112;
BA_ "SigType" SG_ 2560950014 TestLimitMaximum4 1;
BA_ "SPN" SG_ 2560950014 TestLimitMaximum4 4111;
BA_ "SigType" SG_ 2560950014 TestLimitMaximum3 1;
BA_ "SPN" SG_ 2560950014 TestLimitMaximum3 4111;
BA_ "SigType" SG_ 2560950014 TestLimitMaximum2 1;
BA_ "SPN" SG_ 2560950014 TestLimitMaximum2 4111;
BA_ "SigType" SG_ 2560950014 TestValue4 1;
BA_ "SPN" SG_ 2560950014 TestValue4 4110;
BA_ "SigType" SG_ 2560950014 TestValue3 1;
BA_ "SPN" SG_ 2560950014 TestValue3 4110;
BA_ "SigType" SG_ 2560950014 TestValue2 1;
BA_ "SPN" SG_ 2560950014 TestValue2 4110;
BA_ "SigType" SG_ 2560950014 SlotId4 1;
BA_ "SPN" SG_ 2560950014 SlotId4 4109;
BA_ "SigType" SG_ 2560950014 SlotId3 1;
BA_ "SPN" SG_ 2560950014 SlotId3 4109;
BA_ "SigType" SG_ 2560950014 SlotId2 1;
BA_ "SPN" SG_ 2560950014 SlotId2 4109;
BA_ "SPN" SG_ 2560950014 TestIdentifier4 1224;
BA_ "SPN" SG_ 2560950014 TestIdentifier3 1224;
BA_ "SPN" SG_ 2560950014 TestIdentifier2 1224;
BA_ "SPN" SG_ 2560950014 FMI2 1215;
BA_ "SPN" SG_ 2560950014 FMI3 1215;
BA_ "SPN" SG_ 2560950014 FMI4 1215;
BA_ "SPN" SG_ 2560950014 FMI1 1215;
BA_ "SigType" SG_ 2560950014 SPN2 13;
BA_ "SPN" SG_ 2560950014 SPN2 1214;
BA_ "SigType" SG_ 2560950014 SPN3 13;
BA_ "SPN" SG_ 2560950014 SPN3 1214;
BA_ "SigType" SG_ 2560950014 SPN4 13;
BA_ "SPN" SG_ 2560950014 SPN4 1214;
BA_ "SigType" SG_ 2560950014 TestLimitMinimum1 1;
BA_ "SPN" SG_ 2560950014 TestLimitMinimum1 4112;
BA_ "SigType" SG_ 2560950014 SPN1 13;
BA_ "SPN" SG_ 2560950014 SPN1 1214;
BA_ "SigType" SG_ 2560950014 TestLimitMaximum1 1;
BA_ "SPN" SG_ 2560950014 TestLimitMaximum1 4111;
BA_ "SigType" SG_ 2560950014 TestValue1 1;
BA_ "SPN" SG_ 2560950014 TestValue1 4110;
BA_ "SigType" SG_ 2560950014 SlotId1 1;
BA_ "SPN" SG_ 2560950014 SlotId1 4109;
BA_ "SPN" SG_ 2560950014 TestIdentifier1 1224;
BA_ "SigType" SG_ 2560556798 PermanentDTCs 1;
BA_ "SPN" SG_ 2560556798 PermanentDTCs 4108;
BA_ "SigType" SG_ 2560556798 PreviouslyMILOnDTCs 1;
BA_ "SPN" SG_ 2560556798 PreviouslyMILOnDTCs 4107;
BA_ "SigType" SG_ 2560556798 MILOnDTCs 1;
BA_ "SPN" SG_ 2560556798 MILOnDTCs 4106;
BA_ "SigType" SG_ 2560556798 AllPendingDTCs 1;
BA_ "SPN" SG_ 2560556798 AllPendingDTCs 4105;
BA_ "SigType" SG_ 2560556798 PendingDTCs 1;
BA_ "SPN" SG_ 2560556798 PendingDTCs 4104;
BA_ "SPN" SG_ 2566750462 SpnConversionMethod1 1706;
BA_ "SPN" SG_ 2566750462 SpnConversionMethod5 1706;
BA_ "SPN" SG_ 2566750462 SpnConversionMethod4 1706;
BA_ "SPN" SG_ 2566750462 SpnConversionMethod3 1706;
BA_ "SPN" SG_ 2566750462 SpnConversionMethod2 1706;
BA_ "SPN" SG_ 2566750462 OccurenceCount5 1216;
BA_ "SPN" SG_ 2566750462 OccurenceCount4 1216;
BA_ "SPN" SG_ 2566750462 OccurenceCount3 1216;
BA_ "SPN" SG_ 2566750462 OccurenceCount2 1216;
BA_ "SPN" SG_ 2566750462 OccurenceCount1 1216;
BA_ "SPN" SG_ 2566750462 FMI5 4149;
BA_ "SPN" SG_ 2566750462 FMI4 4149;
BA_ "SPN" SG_ 2566750462 FMI3 4149;
BA_ "SPN" SG_ 2566750462 FMI2 4149;
BA_ "SPN" SG_ 2566750462 FMI1 4149;
BA_ "SigType" SG_ 2566750462 FlashRedStopLamp 5;
BA_ "SPN" SG_ 2566750462 FlashRedStopLamp 3039;
BA_ "SigType" SG_ 2566750462 FlashProtectLamp 5;
BA_ "SPN" SG_ 2566750462 FlashProtectLamp 3041;
BA_ "SigType" SG_ 2566750462 FlashMalfuncIndicatorLamp 5;
BA_ "SPN" SG_ 2566750462 FlashMalfuncIndicatorLamp 3038;
BA_ "SigType" SG_ 2566750462 FlashAmberWarningLamp 5;
BA_ "SPN" SG_ 2566750462 FlashAmberWarningLamp 3040;
BA_ "SigType" SG_ 2566750462 MalfunctionIndLampStatus 5;
BA_ "SPN" SG_ 2566750462 MalfunctionIndLampStatus 1213;
BA_ "SigType" SG_ 2566750462 AmberWarningLampStatus 5;
BA_ "SPN" SG_ 2566750462 AmberWarningLampStatus 624;
BA_ "SigType" SG_ 2566750462 RedStopLampState 4;
BA_ "SPN" SG_ 2566750462 RedStopLampState 623;
BA_ "SigType" SG_ 2566750462 ProtectLampStatus 5;
BA_ "SPN" SG_ 2566750462 ProtectLampStatus 987;
BA_ "SigType" SG_ 2566750462 SPN5 13;
BA_ "SigType" SG_ 2566750462 SPN4 13;
BA_ "SigType" SG_ 2566750462 SPN3 13;
BA_ "SigType" SG_ 2566750462 SPN2 13;
BA_ "SigType" SG_ 2566750462 SPN1 13;
BA_ "SPN" SG_ 2566750974 SpnConversionMethod1 1706;
BA_ "SPN" SG_ 2566750974 SpnConversionMethod5 1706;
BA_ "SPN" SG_ 2566750974 SpnConversionMethod4 1706;
BA_ "SPN" SG_ 2566750974 SpnConversionMethod3 1706;
BA_ "SPN" SG_ 2566750974 SpnConversionMethod2 1706;
BA_ "SPN" SG_ 2566750974 OccurenceCount5 1216;
BA_ "SPN" SG_ 2566750974 OccurenceCount4 1216;
BA_ "SPN" SG_ 2566750974 OccurenceCount3 1216;
BA_ "SPN" SG_ 2566750974 OccurenceCount2 1216;
BA_ "SPN" SG_ 2566750974 OccurenceCount1 1216;
BA_ "SPN" SG_ 2566750974 FMI5 4149;
BA_ "SPN" SG_ 2566750974 FMI4 4149;
BA_ "SPN" SG_ 2566750974 FMI3 4149;
BA_ "SPN" SG_ 2566750974 FMI2 4149;
BA_ "SPN" SG_ 2566750974 FMI1 4149;
BA_ "SigType" SG_ 2566750974 FlashRedStopLamp 5;
BA_ "SPN" SG_ 2566750974 FlashRedStopLamp 3039;
BA_ "SigType" SG_ 2566750974 FlashProtectLamp 5;
BA_ "SPN" SG_ 2566750974 FlashProtectLamp 3041;
BA_ "SigType" SG_ 2566750974 FlashMalfuncIndicatorLamp 5;
BA_ "SPN" SG_ 2566750974 FlashMalfuncIndicatorLamp 3038;
BA_ "SigType" SG_ 2566750974 FlashAmberWarningLamp 5;
BA_ "SPN" SG_ 2566750974 FlashAmberWarningLamp 3040;
BA_ "SigType" SG_ 2566750974 MalfunctionIndLampStatus 5;
BA_ "SPN" SG_ 2566750974 MalfunctionIndLampStatus 1213;
BA_ "SigType" SG_ 2566750974 AmberWarningLampStatus 5;
BA_ "SPN" SG_ 2566750974 AmberWarningLampStatus 624;
BA_ "SigType" SG_ 2566750974 RedStopLampState 4;
BA_ "SPN" SG_ 2566750974 RedStopLampState 623;
BA_ "SigType" SG_ 2566750974 ProtectLampStatus 5;
BA_ "SPN" SG_ 2566750974 ProtectLampStatus 987;
BA_ "SigType" SG_ 2566750974 SPN5 13;
BA_ "SigType" SG_ 2566750974 SPN4 13;
BA_ "SigType" SG_ 2566750974 SPN3 13;
BA_ "SigType" SG_ 2566750974 SPN2 13;
BA_ "SigType" SG_ 2566750974 SPN1 13;
BA_ "SystemSignalLongSymbol" SG_ 2566764798 BoostPressureControlSystemEnable "BoostPressureControlSystemEnabled";
BA_ "SigType" SG_ 2566764798 NumOfWarmUpsSinceDTCsCleared 1;
BA_ "SPN" SG_ 2566764798 NumOfWarmUpsSinceDTCsCleared 3302;
BA_ "SigType" SG_ 2566764798 TimeSinceEngineStart 1;
BA_ "SPN" SG_ 2566764798 TimeSinceEngineStart 3301;
BA_ "SPN" SG_ 2566764542 SpnConversionMethod 1706;
BA_ "SPN" SG_ 2566764542 OccurenceCount 1216;
BA_ "SPN" SG_ 2566764542 FMI 1215;
BA_ "SigType" SG_ 2566764542 ExpandedFreezeFrameLength 1;
BA_ "SPN" SG_ 2566764542 ExpandedFreezeFrameLength 3300;
BA_ "SigType" SG_ 2566764542 SPN 13;
BA_ "SPN" SG_ 2566764542 SPN 1214;
BA_ "SigType" SG_ 2566764286 SPNDataLength3 1;
BA_ "SPN" SG_ 2566764286 SPNSupportTypeSTR1 4102;
BA_ "SPN" SG_ 2566764286 SPNSupportTypeDS1 4101;
BA_ "SPN" SG_ 2566764286 SPNSupportTypeEFF1 4100;
BA_ "SigType" SG_ 2566764286 SPNDataLength2 1;
BA_ "SigType" SG_ 2566764286 SPNDataLength1 1;
BA_ "SPN" SG_ 2566764286 SPNDataLength1 4103;
BA_ "SPN" SG_ 2566764286 SPNSupported1 3297;
BA_ "SPN" SG_ 2566764030 SpnConversionMethod1 1706;
BA_ "SPN" SG_ 2566764030 SpnConversionMethod5 1706;
BA_ "SPN" SG_ 2566764030 SpnConversionMethod4 1706;
BA_ "SPN" SG_ 2566764030 SpnConversionMethod3 1706;
BA_ "SPN" SG_ 2566764030 SpnConversionMethod2 1706;
BA_ "SPN" SG_ 2566764030 OccurenceCount5 1216;
BA_ "SPN" SG_ 2566764030 OccurenceCount4 1216;
BA_ "SPN" SG_ 2566764030 OccurenceCount3 1216;
BA_ "SPN" SG_ 2566764030 OccurenceCount2 1216;
BA_ "SPN" SG_ 2566764030 OccurenceCount1 1216;
BA_ "SPN" SG_ 2566764030 FMI5 4149;
BA_ "SPN" SG_ 2566764030 FMI4 4149;
BA_ "SPN" SG_ 2566764030 FMI3 4149;
BA_ "SPN" SG_ 2566764030 FMI2 4149;
BA_ "SPN" SG_ 2566764030 FMI1 4149;
BA_ "SigType" SG_ 2566764030 FlashRedStopLamp 5;
BA_ "SPN" SG_ 2566764030 FlashRedStopLamp 3039;
BA_ "SigType" SG_ 2566764030 FlashProtectLamp 5;
BA_ "SPN" SG_ 2566764030 FlashProtectLamp 3041;
BA_ "SigType" SG_ 2566764030 FlashMalfuncIndicatorLamp 5;
BA_ "SPN" SG_ 2566764030 FlashMalfuncIndicatorLamp 3038;
BA_ "SigType" SG_ 2566764030 FlashAmberWarningLamp 5;
BA_ "SPN" SG_ 2566764030 FlashAmberWarningLamp 3040;
BA_ "SigType" SG_ 2566764030 MalfunctionIndLampStatus 5;
BA_ "SPN" SG_ 2566764030 MalfunctionIndLampStatus 1213;
BA_ "SigType" SG_ 2566764030 AmberWarningLampStatus 5;
BA_ "SPN" SG_ 2566764030 AmberWarningLampStatus 624;
BA_ "SigType" SG_ 2566764030 RedStopLampState 4;
BA_ "SPN" SG_ 2566764030 RedStopLampState 623;
BA_ "SigType" SG_ 2566764030 ProtectLampStatus 5;
BA_ "SPN" SG_ 2566764030 ProtectLampStatus 987;
BA_ "SigType" SG_ 2566764030 SPN5 13;
BA_ "SigType" SG_ 2566764030 SPN4 13;
BA_ "SigType" SG_ 2566764030 SPN3 13;
BA_ "SigType" SG_ 2566764030 SPN2 13;
BA_ "SigType" SG_ 2566764030 SPN1 13;
BA_ "SigType" SG_ 2562981630 SPN 13;
BA_ "SPN" SG_ 2562981630 SPN 1214;
BA_ "SPN" SG_ 2562981630 ControlByte 3034;
BA_ "SPN" SG_ 2562981630 CtrlByteSpecificIndicator 3035;
BA_ "SPN" SG_ 2562981630 FMI 1215;
BA_ "SigType" SG_ 2562850558 TimeSinceDTCsCleared 1;
BA_ "SPN" SG_ 2562850558 TimeSinceDTCsCleared 3296;
BA_ "SigType" SG_ 2562850558 MinutesAccumulatedMILActivated 1;
BA_ "SPN" SG_ 2562850558 MinutesAccumulatedMILActivated 3295;
BA_ "SigType" SG_ 2562850558 DistanceSinceDTCsCleared 1;
BA_ "SPN" SG_ 2562850558 DistanceSinceDTCsCleared 3294;
BA_ "SigType" SG_ 2562850558 DistanceWhileMILisActivated 1;
BA_ "SPN" SG_ 2562850558 DistanceWhileMILisActivated 3069;
BA_ "SPN" SG_ 2562916094 ApplSysMonitorDenominator 3068;
BA_ "SPN" SG_ 2562916094 ApplSysMonitorNumerator 3067;
BA_ "SPN" SG_ 2562916094 SpnOfApplSysMonitor 3066;
BA_ "SPN" SG_ 2562916094 OBDMonitoringCondEncountered 3049;
BA_ "SPN" SG_ 2562916094 IgnitionCycleCounter 3048;
BA_ "SPN" SG_ 2564030206 CalibrationID1 1635;
BA_ "SPN" SG_ 2564030206 CalibrationVerificationNumber 1634;
BA_ "SPN" SG_ 2564095742 DataSecurityParameter 1597;
BA_ "SPN" SG_ 2564095742 SecurityEntityType 1479;
BA_ "SPN" SG_ 2564095742 SecurityEntityLength 1596;
BA_ "SPN" SG_ 2564226814 BootLoadData 1652;
BA_ "SPN" SG_ 2564292350 RawBinaryData 1651;
BA_ "SPN" SG_ 2564292350 NumberOfOccurance 1650;
BA_ "SPN" SG_ 2564357886 NumberAllowed 1649;
BA_ "SPN" SG_ 2564357886 Seed 1599;
BA_ "SPN" SG_ 2564357886 EDCP_Extension 1647;
BA_ "SPN" SG_ 2564357886 ErrorIndicator 1648;
BA_ "SPN" SG_ 2564357886 Status 1646;
BA_ "SPN" SG_ 2564423422 KeyOrUserLevel 1645;
BA_ "SPN" SG_ 2564423422 PointerExtension 1643;
BA_ "SPN" SG_ 2564423422 Pointer 1644;
BA_ "SPN" SG_ 2564423422 Command 1642;
BA_ "SPN" SG_ 2564423422 PointerType 1641;
BA_ "SPN" SG_ 2564423422 NumberRequested 1640;
BA_ "SigType" SG_ 2564816638 ProprietaryNetwork2 5;
BA_ "SPN" SG_ 2564816638 ProprietaryNetwork2 5588;
BA_ "SigType" SG_ 2564816638 ProprietaryNetwork1 5;
BA_ "SPN" SG_ 2564816638 ProprietaryNetwork1 625;
BA_ "SigType" SG_ 2564816638 J1939Network4 5;
BA_ "SPN" SG_ 2564816638 J1939Network4 1668;
BA_ "SPN" SG_ 2564816638 HoldSignal 1236;
BA_ "SigType" SG_ 2564816638 J1939Network3 5;
BA_ "SPN" SG_ 2564816638 J1939Network3 1235;
BA_ "SigType" SG_ 2564816638 J1939Network2 5;
BA_ "SPN" SG_ 2564816638 J1939Network2 1231;
BA_ "SigType" SG_ 2564816638 ISO9141 5;
BA_ "SPN" SG_ 2564816638 ISO9141 1232;
BA_ "SigType" SG_ 2564816638 SAE_J1850 5;
BA_ "SPN" SG_ 2564816638 SAE_J1850 1233;
BA_ "SigType" SG_ 2564816638 ManufacturerSpecificPort 5;
BA_ "SPN" SG_ 2564816638 ManufacturerSpecificPort 1234;
BA_ "SigType" SG_ 2564816638 CurrentDataLink 5;
BA_ "SPN" SG_ 2564816638 CurrentDataLink 1230;
BA_ "SigType" SG_ 2564816638 SAE_J1587 5;
BA_ "SPN" SG_ 2564816638 SAE_J1587 608;
BA_ "SigType" SG_ 2564816638 SAE_J1922 5;
BA_ "SPN" SG_ 2564816638 SAE_J1922 622;
BA_ "SigType" SG_ 2564816638 J1939Network1 5;
BA_ "SPN" SG_ 2564816638 J1939Network1 639;
BA_ "SPN" SG_ 2564816638 SuspendSignal 2618;
BA_ "SigType" SG_ 2564816638 SuspendDuration 1;
BA_ "SPN" SG_ 2564816638 SuspendDuration 2619;
BA_ "SPN" SG_ 2566837502 SpnConversionMethod1 1706;
BA_ "SPN" SG_ 2566837502 SpnConversionMethod5 1706;
BA_ "SPN" SG_ 2566837502 SpnConversionMethod4 1706;
BA_ "SPN" SG_ 2566837502 SpnConversionMethod3 1706;
BA_ "SPN" SG_ 2566837502 SpnConversionMethod2 1706;
BA_ "SPN" SG_ 2566837502 OccurenceCount5 1216;
BA_ "SPN" SG_ 2566837502 OccurenceCount4 1216;
BA_ "SPN" SG_ 2566837502 OccurenceCount3 1216;
BA_ "SPN" SG_ 2566837502 OccurenceCount2 1216;
BA_ "SPN" SG_ 2566837502 OccurenceCount1 1216;
BA_ "SPN" SG_ 2566837502 FMI5 4149;
BA_ "SPN" SG_ 2566837502 FMI4 4149;
BA_ "SPN" SG_ 2566837502 FMI3 4149;
BA_ "SPN" SG_ 2566837502 FMI2 4149;
BA_ "SPN" SG_ 2566837502 FMI1 4149;
BA_ "SigType" SG_ 2566837502 FlashRedStopLamp 5;
BA_ "SPN" SG_ 2566837502 FlashRedStopLamp 3039;
BA_ "SigType" SG_ 2566837502 FlashProtectLamp 5;
BA_ "SPN" SG_ 2566837502 FlashProtectLamp 3041;
BA_ "SigType" SG_ 2566837502 FlashMalfuncIndicatorLamp 5;
BA_ "SPN" SG_ 2566837502 FlashMalfuncIndicatorLamp 3038;
BA_ "SigType" SG_ 2566837502 FlashAmberWarningLamp 5;
BA_ "SPN" SG_ 2566837502 FlashAmberWarningLamp 3040;
BA_ "SigType" SG_ 2566837502 MalfunctionIndLampStatus 5;
BA_ "SPN" SG_ 2566837502 MalfunctionIndLampStatus 1213;
BA_ "SigType" SG_ 2566837502 AmberWarningLampStatus 5;
BA_ "SPN" SG_ 2566837502 AmberWarningLampStatus 624;
BA_ "SigType" SG_ 2566837502 RedStopLampState 4;
BA_ "SPN" SG_ 2566837502 RedStopLampState 623;
BA_ "SigType" SG_ 2566837502 ProtectLampStatus 5;
BA_ "SPN" SG_ 2566837502 ProtectLampStatus 987;
BA_ "SigType" SG_ 2566837502 SPN5 13;
BA_ "SigType" SG_ 2566837502 SPN4 13;
BA_ "SigType" SG_ 2566837502 SPN3 13;
BA_ "SigType" SG_ 2566837502 SPN2 13;
BA_ "SigType" SG_ 2566837502 SPN1 13;
BA_ "SigType" SG_ 2566836990 TestIdentifierSupported 1;
BA_ "SPN" SG_ 2566836990 TestIdentifierSupported 1229;
BA_ "SigType" SG_ 2566836478 TestLimitMinimum 1;
BA_ "SPN" SG_ 2566836478 TestLimitMinimum 1228;
BA_ "SigType" SG_ 2566836478 TestLimitMaximum 1;
BA_ "SPN" SG_ 2566836478 TestLimitMaximum 1227;
BA_ "SigType" SG_ 2566836478 TestValue 1;
BA_ "SPN" SG_ 2566836478 TestValue 1226;
BA_ "SigType" SG_ 2566836478 TestType 1;
BA_ "SPN" SG_ 2566836478 TestType 1225;
BA_ "SPN" SG_ 2566836478 TestIdentifier 1224;
BA_ "SigType" SG_ 2565078782 SPN 13;
BA_ "SPN" SG_ 2565078782 SPN 4148;
BA_ "SPN" SG_ 2565078782 TestIdentifier 1224;
BA_ "SPN" SG_ 2565078782 FMI 4149;
VAL_ 2566742014 FMI5 24 "Assurance Data Error" 23 "Request DM60 for more info" 22 "Special Instructions #2 " 21 "Data drifted low" 20 "Data drifted high" 31 "Condition exists" 19 "Received network data in error" 18 "Below normal (moderately severe)" 17 "Below normal (least severe)" 16 "Above normal (moderately severe)" 15 "Above normal (least severe)" 14 "Special intstructions" 13 "Out of calibration" 12 "Bad intelligent device" 11 "Root cause not known" 10 "Abnormal rate of change" 9 "Abnormal update rate" 8 "Abnormal frequency" 7 "Mechanical system not responding" 6 "Current above normal" 5 "Current below normal" 4 "Voltage below normal" 3 "Voltage above normal" 2 "Data erratic" 1 "Below normal (most severe)" 0 "Above normal (most severe)" ;
VAL_ 2566742014 FMI4 24 "Assurance Data Error" 23 "Request DM60 for more info" 22 "Special Instructions #2 " 21 "Data drifted low" 20 "Data drifted high" 31 "Condition exists" 19 "Received network data in error" 18 "Below normal (moderately severe)" 17 "Below normal (least severe)" 16 "Above normal (moderately severe)" 15 "Above normal (least severe)" 14 "Special intstructions" 13 "Out of calibration" 12 "Bad intelligent device" 11 "Root cause not known" 10 "Abnormal rate of change" 9 "Abnormal update rate" 8 "Abnormal frequency" 7 "Mechanical system not responding" 6 "Current above normal" 5 "Current below normal" 4 "Voltage below normal" 3 "Voltage above normal" 2 "Data erratic" 1 "Below normal (most severe)" 0 "Above normal (most severe)" ;
VAL_ 2566742014 FMI3 24 "Assurance Data Error" 23 "Request DM60 for more info" 22 "Special Instructions #2 " 21 "Data drifted low" 20 "Data drifted high" 31 "Condition exists" 19 "Received network data in error" 18 "Below normal (moderately severe)" 17 "Below normal (least severe)" 16 "Above normal (moderately severe)" 15 "Above normal (least severe)" 14 "Special intstructions" 13 "Out of calibration" 12 "Bad intelligent device" 11 "Root cause not known" 10 "Abnormal rate of change" 9 "Abnormal update rate" 8 "Abnormal frequency" 7 "Mechanical system not responding" 6 "Current above normal" 5 "Current below normal" 4 "Voltage below normal" 3 "Voltage above normal" 2 "Data erratic" 1 "Below normal (most severe)" 0 "Above normal (most severe)" ;
VAL_ 2566742014 FMI2 24 "Assurance Data Error" 23 "Request DM60 for more info" 22 "Special Instructions #2 " 21 "Data drifted low" 20 "Data drifted high" 31 "Condition exists" 19 "Received network data in error" 18 "Below normal (moderately severe)" 17 "Below normal (least severe)" 16 "Above normal (moderately severe)" 15 "Above normal (least severe)" 14 "Special intstructions" 13 "Out of calibration" 12 "Bad intelligent device" 11 "Root cause not known" 10 "Abnormal rate of change" 9 "Abnormal update rate" 8 "Abnormal frequency" 7 "Mechanical system not responding" 6 "Current above normal" 5 "Current below normal" 4 "Voltage below normal" 3 "Voltage above normal" 2 "Data erratic" 1 "Below normal (most severe)" 0 "Above normal (most severe)" ;
VAL_ 2566742014 FMI1 24 "Assurance Data Error" 23 "Request DM60 for more info" 22 "Special Instructions #2 " 21 "Data drifted low" 20 "Data drifted high" 31 "Condition exists" 19 "Received network data in error" 18 "Below normal (moderately severe)" 17 "Below normal (least severe)" 16 "Above normal (moderately severe)" 15 "Above normal (least severe)" 14 "Special intstructions" 13 "Out of calibration" 12 "Bad intelligent device" 11 "Root cause not known" 10 "Abnormal rate of change" 9 "Abnormal update rate" 8 "Abnormal frequency" 7 "Mechanical system not responding" 6 "Current above normal" 5 "Current below normal" 4 "Voltage below normal" 3 "Voltage above normal" 2 "Data erratic" 1 "Below normal (most severe)" 0 "Above normal (most severe)" ;
VAL_ 2566742014 FlashRedStopLamp 3 "Unavailable / Do Not Flash" 2 "Reserved" 1 "Fast Flash" 0 "Slow Flash" ;
VAL_ 2566742014 FlashProtectLamp 3 "Unavailable / Do Not Flash" 2 "Reserved" 1 "Fast Flash" 0 "Slow Flash" ;
VAL_ 2566742014 FlashMalfuncIndicatorLamp 3 "Unavailable / Do Not Flash" 2 "Class C DTC  " 1 "Fast Flash" 0 "Slow Flash" ;
VAL_ 2566742014 FlashAmberWarningLamp 3 "Unavailable / Do Not Flash" 2 "Reserved" 1 "Fast Flash" 0 "Slow Flash" ;
VAL_ 2566742014 MalfunctionIndLampStatus 3 "Not available" 2 "Short MIL for WWH OBD" 1 "Lamp On" 0 "Lamp Off" ;
VAL_ 2566742014 AmberWarningLampStatus 3 "Not available" 2 "Reserved" 1 "Lamp On" 0 "Lamp Off" ;
VAL_ 2566742014 RedStopLampState 3 "Not available" 2 "Reserved" 1 "Lamp On" 0 "Lamp Off" ;
VAL_ 2566742014 ProtectLampStatus 0 "Lamp Off" 3 "Not available" 2 "Reserved" 1 "Lamp On" ;
VAL_ 2566742270 FMI4 24 "Assurance Data Error" 23 "Request DM60 for more info" 22 "Special Instructions #2 " 21 "Data drifted low" 20 "Data drifted high" 31 "Condition exists" 19 "Received network data in error" 18 "Below normal (moderately severe)" 17 "Below normal (least severe)" 16 "Above normal (moderately severe)" 15 "Above normal (least severe)" 14 "Special intstructions" 13 "Out of calibration" 12 "Bad intelligent device" 11 "Root cause not known" 10 "Abnormal rate of change" 9 "Abnormal update rate" 8 "Abnormal frequency" 7 "Mechanical system not responding" 6 "Current above normal" 5 "Current below normal" 4 "Voltage below normal" 3 "Voltage above normal" 2 "Data erratic" 1 "Below normal (most severe)" 0 "Above normal (most severe)" ;
VAL_ 2566742270 FMI3 24 "Assurance Data Error" 23 "Request DM60 for more info" 22 "Special Instructions #2 " 21 "Data drifted low" 20 "Data drifted high" 31 "Condition exists" 19 "Received network data in error" 18 "Below normal (moderately severe)" 17 "Below normal (least severe)" 16 "Above normal (moderately severe)" 15 "Above normal (least severe)" 14 "Special intstructions" 13 "Out of calibration" 12 "Bad intelligent device" 11 "Root cause not known" 10 "Abnormal rate of change" 9 "Abnormal update rate" 8 "Abnormal frequency" 7 "Mechanical system not responding" 6 "Current above normal" 5 "Current below normal" 4 "Voltage below normal" 3 "Voltage above normal" 2 "Data erratic" 1 "Below normal (most severe)" 0 "Above normal (most severe)" ;
VAL_ 2566742270 FMI2 24 "Assurance Data Error" 23 "Request DM60 for more info" 22 "Special Instructions #2 " 21 "Data drifted low" 20 "Data drifted high" 31 "Condition exists" 19 "Received network data in error" 18 "Below normal (moderately severe)" 17 "Below normal (least severe)" 16 "Above normal (moderately severe)" 15 "Above normal (least severe)" 14 "Special intstructions" 13 "Out of calibration" 12 "Bad intelligent device" 11 "Root cause not known" 10 "Abnormal rate of change" 9 "Abnormal update rate" 8 "Abnormal frequency" 7 "Mechanical system not responding" 6 "Current above normal" 5 "Current below normal" 4 "Voltage below normal" 3 "Voltage above normal" 2 "Data erratic" 1 "Below normal (most severe)" 0 "Above normal (most severe)" ;
VAL_ 2566742270 FMI1 24 "Assurance Data Error" 23 "Request DM60 for more info" 22 "Special Instructions #2 " 21 "Data drifted low" 20 "Data drifted high" 31 "Condition exists" 19 "Received network data in error" 18 "Below normal (moderately severe)" 17 "Below normal (least severe)" 16 "Above normal (moderately severe)" 15 "Above normal (least severe)" 14 "Special intstructions" 13 "Out of calibration" 12 "Bad intelligent device" 11 "Root cause not known" 10 "Abnormal rate of change" 9 "Abnormal update rate" 8 "Abnormal frequency" 7 "Mechanical system not responding" 6 "Current above normal" 5 "Current below normal" 4 "Voltage below normal" 3 "Voltage above normal" 2 "Data erratic" 1 "Below normal (most severe)" 0 "Above normal (most severe)" ;
VAL_ 2560622334 FMI5 24 "Assurance Data Error" 23 "Request DM60 for more info" 22 "Special Instructions #2 " 21 "Data drifted low" 20 "Data drifted high" 31 "Condition exists" 19 "Received network data in error" 18 "Below normal (moderately severe)" 17 "Below normal (least severe)" 16 "Above normal (moderately severe)" 15 "Above normal (least severe)" 14 "Special intstructions" 13 "Out of calibration" 12 "Bad intelligent device" 11 "Root cause not known" 10 "Abnormal rate of change" 9 "Abnormal update rate" 8 "Abnormal frequency" 7 "Mechanical system not responding" 6 "Current above normal" 5 "Current below normal" 4 "Voltage below normal" 3 "Voltage above normal" 2 "Data erratic" 1 "Below normal (most severe)" 0 "Above normal (most severe)" ;
VAL_ 2560622334 FMI4 24 "Assurance Data Error" 23 "Request DM60 for more info" 22 "Special Instructions #2 " 21 "Data drifted low" 20 "Data drifted high" 31 "Condition exists" 19 "Received network data in error" 18 "Below normal (moderately severe)" 17 "Below normal (least severe)" 16 "Above normal (moderately severe)" 15 "Above normal (least severe)" 14 "Special intstructions" 13 "Out of calibration" 12 "Bad intelligent device" 11 "Root cause not known" 10 "Abnormal rate of change" 9 "Abnormal update rate" 8 "Abnormal frequency" 7 "Mechanical system not responding" 6 "Current above normal" 5 "Current below normal" 4 "Voltage below normal" 3 "Voltage above normal" 2 "Data erratic" 1 "Below normal (most severe)" 0 "Above normal (most severe)" ;
VAL_ 2560622334 FMI3 24 "Assurance Data Error" 23 "Request DM60 for more info" 22 "Special Instructions #2 " 21 "Data drifted low" 20 "Data drifted high" 31 "Condition exists" 19 "Received network data in error" 18 "Below normal (moderately severe)" 17 "Below normal (least severe)" 16 "Above normal (moderately severe)" 15 "Above normal (least severe)" 14 "Special intstructions" 13 "Out of calibration" 12 "Bad intelligent device" 11 "Root cause not known" 10 "Abnormal rate of change" 9 "Abnormal update rate" 8 "Abnormal frequency" 7 "Mechanical system not responding" 6 "Current above normal" 5 "Current below normal" 4 "Voltage below normal" 3 "Voltage above normal" 2 "Data erratic" 1 "Below normal (most severe)" 0 "Above normal (most severe)" ;
VAL_ 2560622334 FMI2 24 "Assurance Data Error" 23 "Request DM60 for more info" 22 "Special Instructions #2 " 21 "Data drifted low" 20 "Data drifted high" 31 "Condition exists" 19 "Received network data in error" 18 "Below normal (moderately severe)" 17 "Below normal (least severe)" 16 "Above normal (moderately severe)" 15 "Above normal (least severe)" 14 "Special intstructions" 13 "Out of calibration" 12 "Bad intelligent device" 11 "Root cause not known" 10 "Abnormal rate of change" 9 "Abnormal update rate" 8 "Abnormal frequency" 7 "Mechanical system not responding" 6 "Current above normal" 5 "Current below normal" 4 "Voltage below normal" 3 "Voltage above normal" 2 "Data erratic" 1 "Below normal (most severe)" 0 "Above normal (most severe)" ;
VAL_ 2560622334 FMI1 24 "Assurance Data Error" 23 "Request DM60 for more info" 22 "Special Instructions #2 " 21 "Data drifted low" 20 "Data drifted high" 31 "Condition exists" 19 "Received network data in error" 18 "Below normal (moderately severe)" 17 "Below normal (least severe)" 16 "Above normal (moderately severe)" 15 "Above normal (least severe)" 14 "Special intstructions" 13 "Out of calibration" 12 "Bad intelligent device" 11 "Root cause not known" 10 "Abnormal rate of change" 9 "Abnormal update rate" 8 "Abnormal frequency" 7 "Mechanical system not responding" 6 "Current above normal" 5 "Current below normal" 4 "Voltage below normal" 3 "Voltage above normal" 2 "Data erratic" 1 "Below normal (most severe)" 0 "Above normal (most severe)" ;
VAL_ 2560622334 FlashRedStopLamp 3 "Unavailable / Do Not Flash" 2 "Reserved" 1 "Fast Flash" 0 "Slow Flash" ;
VAL_ 2560622334 FlashProtectLamp 3 "Unavailable / Do Not Flash" 2 "Reserved" 1 "Fast Flash" 0 "Slow Flash" ;
VAL_ 2560622334 FlashMalfuncIndicatorLamp 3 "Unavailable / Do Not Flash" 2 "Class C DTC  " 1 "Fast Flash" 0 "Slow Flash" ;
VAL_ 2560622334 FlashAmberWarningLamp 3 "Unavailable / Do Not Flash" 2 "Reserved" 1 "Fast Flash" 0 "Slow Flash" ;
VAL_ 2560622334 MalfunctionIndLampStatus 3 "Not available" 2 "Short MIL for WWH OBD" 1 "Lamp On" 0 "Lamp Off" ;
VAL_ 2560622334 AmberWarningLampStatus 3 "Not available" 2 "Reserved" 1 "Lamp On" 0 "Lamp Off" ;
VAL_ 2560622334 RedStopLampState 3 "Not available" 2 "Reserved" 1 "Lamp On" 0 "Lamp Off" ;
VAL_ 2560622334 ProtectLampStatus 0 "Lamp Off" 3 "Not available" 2 "Reserved" 1 "Lamp On" ;
VAL_ 2560687870 PMNTEDeficiencyAreaStatus 3 "NotAvailable" 2 "Reserved" 1 "InsideControlArea" 0 "OutsideControlArea" ;
VAL_ 2560687870 MnfcPMNTECarveOutAreaStatus 3 "NotAvailable" 2 "Reserved" 1 "InsideControlArea" 0 "OutsideControlArea" ;
VAL_ 2560687870 PMNTEControlAreaStatus 3 "NotAvailable" 2 "Reserved" 1 "InsideControlArea" 0 "OutsideControlArea" ;
VAL_ 2560687870 NOxNTEDeficiencyAreaStatus 3 "NotAvailable" 2 "Reserved" 1 "InsideControlArea" 0 "OutsideControlArea" ;
VAL_ 2560687870 MnfcNOxNTECarveOutAreaStatus 3 "NotAvailable" 2 "Reserved" 1 "InsideControlArea" 0 "OutsideControlArea" ;
VAL_ 2560687870 NOxNTEControlAreaStatus 3 "NotAvailable" 2 "Reserved" 1 "InsideControlArea" 0 "OutsideControlArea" ;
VAL_ 2560818942 FMI4 24 "Assurance Data Error" 23 "Request DM60 for more info" 22 "Special Instructions #2 " 21 "Data drifted low" 20 "Data drifted high" 31 "Condition exists" 19 "Received network data in error" 18 "Below normal (moderately severe)" 17 "Below normal (least severe)" 16 "Above normal (moderately severe)" 15 "Above normal (least severe)" 14 "Special intstructions" 13 "Out of calibration" 12 "Bad intelligent device" 11 "Root cause not known" 10 "Abnormal rate of change" 9 "Abnormal update rate" 8 "Abnormal frequency" 7 "Mechanical system not responding" 6 "Current above normal" 5 "Current below normal" 4 "Voltage below normal" 3 "Voltage above normal" 2 "Data erratic" 1 "Below normal (most severe)" 0 "Above normal (most severe)" ;
VAL_ 2560818942 FMI3 24 "Assurance Data Error" 23 "Request DM60 for more info" 22 "Special Instructions #2 " 21 "Data drifted low" 20 "Data drifted high" 31 "Condition exists" 19 "Received network data in error" 18 "Below normal (moderately severe)" 17 "Below normal (least severe)" 16 "Above normal (moderately severe)" 15 "Above normal (least severe)" 14 "Special intstructions" 13 "Out of calibration" 12 "Bad intelligent device" 11 "Root cause not known" 10 "Abnormal rate of change" 9 "Abnormal update rate" 8 "Abnormal frequency" 7 "Mechanical system not responding" 6 "Current above normal" 5 "Current below normal" 4 "Voltage below normal" 3 "Voltage above normal" 2 "Data erratic" 1 "Below normal (most severe)" 0 "Above normal (most severe)" ;
VAL_ 2560818942 FMI2 24 "Assurance Data Error" 23 "Request DM60 for more info" 22 "Special Instructions #2 " 21 "Data drifted low" 20 "Data drifted high" 31 "Condition exists" 19 "Received network data in error" 18 "Below normal (moderately severe)" 17 "Below normal (least severe)" 16 "Above normal (moderately severe)" 15 "Above normal (least severe)" 14 "Special intstructions" 13 "Out of calibration" 12 "Bad intelligent device" 11 "Root cause not known" 10 "Abnormal rate of change" 9 "Abnormal update rate" 8 "Abnormal frequency" 7 "Mechanical system not responding" 6 "Current above normal" 5 "Current below normal" 4 "Voltage below normal" 3 "Voltage above normal" 2 "Data erratic" 1 "Below normal (most severe)" 0 "Above normal (most severe)" ;
VAL_ 2560818942 FMI1 24 "Assurance Data Error" 23 "Request DM60 for more info" 22 "Special Instructions #2 " 21 "Data drifted low" 20 "Data drifted high" 31 "Condition exists" 19 "Received network data in error" 18 "Below normal (moderately severe)" 17 "Below normal (least severe)" 16 "Above normal (moderately severe)" 15 "Above normal (least severe)" 14 "Special intstructions" 13 "Out of calibration" 12 "Bad intelligent device" 11 "Root cause not known" 10 "Abnormal rate of change" 9 "Abnormal update rate" 8 "Abnormal frequency" 7 "Mechanical system not responding" 6 "Current above normal" 5 "Current below normal" 4 "Voltage below normal" 3 "Voltage above normal" 2 "Data erratic" 1 "Below normal (most severe)" 0 "Above normal (most severe)" ;
VAL_ 2560884478 FMI 24 "Assurance Data Error" 23 "Request DM60 for more info" 22 "Special Instructions #2 " 21 "Data drifted low" 20 "Data drifted high" 31 "Condition exists" 19 "Received network data in error" 18 "Below normal (moderately severe)" 17 "Below normal (least severe)" 16 "Above normal (moderately severe)" 15 "Above normal (least severe)" 14 "Special intstructions" 13 "Out of calibration" 12 "Bad intelligent device" 11 "Root cause not known" 10 "Abnormal rate of change" 9 "Abnormal update rate" 8 "Abnormal frequency" 7 "Mechanical system not responding" 6 "Current above normal" 5 "Current below normal" 4 "Voltage below normal" 3 "Voltage above normal" 2 "Data erratic" 1 "Below normal (most severe)" 0 "Above normal (most severe)" ;
VAL_ 2560884478 DTCWarnLampSupportStatus 3 "Unavailable" 2 "Reserved" 1 "LampOn" 0 "LampOff" ;
VAL_ 2560884478 DTCWarnLampSupportFlash 3 "Unavailable" 2 "Reserved" 1 "FastFlash" 0 "SlowFlash" ;
VAL_ 2560884478 DTCStopLampSupportStatus 3 "Unavailable" 2 "Reserved" 1 "LampOn" 0 "LampOff" ;
VAL_ 2560884478 DTCStopLampSupportFlash 3 "Unavailable" 2 "Reserved" 1 "FastFlash" 0 "SlowFlash" ;
VAL_ 2560884478 DTCProtectLampSupportStatus 3 "Unavailable" 2 "Reserved" 1 "LampOn" 0 "LampOff" ;
VAL_ 2560884478 DTCProtectLampSupportFlash 3 "Unavailable" 2 "Reserved" 1 "FastFlash" 0 "SlowFlash" ;
VAL_ 2560884478 DTCMilSupportStatus 3 "Unavailable" 2 "ShortMI" 1 "LampOn" 0 "LampOff" ;
VAL_ 2560884478 DTCMilSupportFlash 3 "Unavailable" 2 "Class_C_DTC" 1 "FastFlash" 0 "SlowFlash" ;
VAL_ 2560950014 TestIdentifier4 248 "Command manufacturer specific test " 246 "Return all scaled test results for all SPNs" 245 "Return rationality fault SP data value " 250 "Return last measured scaled results" 249 "Command Standard Test" 247 "Return all scaled test results for one SPN" ;
VAL_ 2560950014 TestIdentifier3 248 "Command manufacturer specific test " 246 "Return all scaled test results for all SPNs" 245 "Return rationality fault SP data value " 250 "Return last measured scaled results" 249 "Command Standard Test" 247 "Return all scaled test results for one SPN" ;
VAL_ 2560950014 TestIdentifier2 248 "Command manufacturer specific test " 246 "Return all scaled test results for all SPNs" 245 "Return rationality fault SP data value " 250 "Return last measured scaled results" 249 "Command Standard Test" 247 "Return all scaled test results for one SPN" ;
VAL_ 2560950014 FMI2 24 "Assurance Data Error" 23 "Request DM60 for more info" 22 "Special Instructions #2 " 21 "Data drifted low" 20 "Data drifted high" 31 "Condition exists" 19 "Received network data in error" 18 "Below normal (moderately severe)" 17 "Below normal (least severe)" 16 "Above normal (moderately severe)" 15 "Above normal (least severe)" 14 "Special intstructions" 13 "Out of calibration" 12 "Bad intelligent device" 11 "Root cause not known" 10 "Abnormal rate of change" 9 "Abnormal update rate" 8 "Abnormal frequency" 7 "Mechanical system not responding" 6 "Current above normal" 5 "Current below normal" 4 "Voltage below normal" 3 "Voltage above normal" 2 "Data erratic" 1 "Below normal (most severe)" 0 "Above normal (most severe)" ;
VAL_ 2560950014 FMI3 24 "Assurance Data Error" 23 "Request DM60 for more info" 22 "Special Instructions #2 " 21 "Data drifted low" 20 "Data drifted high" 31 "Condition exists" 19 "Received network data in error" 18 "Below normal (moderately severe)" 17 "Below normal (least severe)" 16 "Above normal (moderately severe)" 15 "Above normal (least severe)" 14 "Special intstructions" 13 "Out of calibration" 12 "Bad intelligent device" 11 "Root cause not known" 10 "Abnormal rate of change" 9 "Abnormal update rate" 8 "Abnormal frequency" 7 "Mechanical system not responding" 6 "Current above normal" 5 "Current below normal" 4 "Voltage below normal" 3 "Voltage above normal" 2 "Data erratic" 1 "Below normal (most severe)" 0 "Above normal (most severe)" ;
VAL_ 2560950014 FMI4 24 "Assurance Data Error" 23 "Request DM60 for more info" 22 "Special Instructions #2 " 21 "Data drifted low" 20 "Data drifted high" 31 "Condition exists" 19 "Received network data in error" 18 "Below normal (moderately severe)" 17 "Below normal (least severe)" 16 "Above normal (moderately severe)" 15 "Above normal (least severe)" 14 "Special intstructions" 13 "Out of calibration" 12 "Bad intelligent device" 11 "Root cause not known" 10 "Abnormal rate of change" 9 "Abnormal update rate" 8 "Abnormal frequency" 7 "Mechanical system not responding" 6 "Current above normal" 5 "Current below normal" 4 "Voltage below normal" 3 "Voltage above normal" 2 "Data erratic" 1 "Below normal (most severe)" 0 "Above normal (most severe)" ;
VAL_ 2560950014 FMI1 24 "Assurance Data Error" 23 "Request DM60 for more info" 22 "Special Instructions #2 " 21 "Data drifted low" 20 "Data drifted high" 31 "Condition exists" 19 "Received network data in error" 18 "Below normal (moderately severe)" 17 "Below normal (least severe)" 16 "Above normal (moderately severe)" 15 "Above normal (least severe)" 14 "Special intstructions" 13 "Out of calibration" 12 "Bad intelligent device" 11 "Root cause not known" 10 "Abnormal rate of change" 9 "Abnormal update rate" 8 "Abnormal frequency" 7 "Mechanical system not responding" 6 "Current above normal" 5 "Current below normal" 4 "Voltage below normal" 3 "Voltage above normal" 2 "Data erratic" 1 "Below normal (most severe)" 0 "Above normal (most severe)" ;
VAL_ 2560950014 TestIdentifier1 248 "Command manufacturer specific test " 246 "Return all scaled test results for all SPNs" 245 "Return rationality fault SP data value " 250 "Return last measured scaled results" 249 "Command Standard Test" 247 "Return all scaled test results for one SPN" ;
VAL_ 2566750462 FMI5 24 "Assurance Data Error" 23 "Request DM60 for more info" 22 "Special Instructions #2 " 21 "Data drifted low" 20 "Data drifted high" 31 "Condition exists" 19 "Received network data in error" 18 "Below normal (moderately severe)" 17 "Below normal (least severe)" 16 "Above normal (moderately severe)" 15 "Above normal (least severe)" 14 "Special intstructions" 13 "Out of calibration" 12 "Bad intelligent device" 11 "Root cause not known" 10 "Abnormal rate of change" 9 "Abnormal update rate" 8 "Abnormal frequency" 7 "Mechanical system not responding" 6 "Current above normal" 5 "Current below normal" 4 "Voltage below normal" 3 "Voltage above normal" 2 "Data erratic" 1 "Below normal (most severe)" 0 "Above normal (most severe)" ;
VAL_ 2566750462 FMI4 24 "Assurance Data Error" 23 "Request DM60 for more info" 22 "Special Instructions #2 " 21 "Data drifted low" 20 "Data drifted high" 31 "Condition exists" 19 "Received network data in error" 18 "Below normal (moderately severe)" 17 "Below normal (least severe)" 16 "Above normal (moderately severe)" 15 "Above normal (least severe)" 14 "Special intstructions" 13 "Out of calibration" 12 "Bad intelligent device" 11 "Root cause not known" 10 "Abnormal rate of change" 9 "Abnormal update rate" 8 "Abnormal frequency" 7 "Mechanical system not responding" 6 "Current above normal" 5 "Current below normal" 4 "Voltage below normal" 3 "Voltage above normal" 2 "Data erratic" 1 "Below normal (most severe)" 0 "Above normal (most severe)" ;
VAL_ 2566750462 FMI3 24 "Assurance Data Error" 23 "Request DM60 for more info" 22 "Special Instructions #2 " 21 "Data drifted low" 20 "Data drifted high" 31 "Condition exists" 19 "Received network data in error" 18 "Below normal (moderately severe)" 17 "Below normal (least severe)" 16 "Above normal (moderately severe)" 15 "Above normal (least severe)" 14 "Special intstructions" 13 "Out of calibration" 12 "Bad intelligent device" 11 "Root cause not known" 10 "Abnormal rate of change" 9 "Abnormal update rate" 8 "Abnormal frequency" 7 "Mechanical system not responding" 6 "Current above normal" 5 "Current below normal" 4 "Voltage below normal" 3 "Voltage above normal" 2 "Data erratic" 1 "Below normal (most severe)" 0 "Above normal (most severe)" ;
VAL_ 2566750462 FMI2 24 "Assurance Data Error" 23 "Request DM60 for more info" 22 "Special Instructions #2 " 21 "Data drifted low" 20 "Data drifted high" 31 "Condition exists" 19 "Received network data in error" 18 "Below normal (moderately severe)" 17 "Below normal (least severe)" 16 "Above normal (moderately severe)" 15 "Above normal (least severe)" 14 "Special intstructions" 13 "Out of calibration" 12 "Bad intelligent device" 11 "Root cause not known" 10 "Abnormal rate of change" 9 "Abnormal update rate" 8 "Abnormal frequency" 7 "Mechanical system not responding" 6 "Current above normal" 5 "Current below normal" 4 "Voltage below normal" 3 "Voltage above normal" 2 "Data erratic" 1 "Below normal (most severe)" 0 "Above normal (most severe)" ;
VAL_ 2566750462 FMI1 24 "Assurance Data Error" 23 "Request DM60 for more info" 22 "Special Instructions #2 " 21 "Data drifted low" 20 "Data drifted high" 31 "Condition exists" 19 "Received network data in error" 18 "Below normal (moderately severe)" 17 "Below normal (least severe)" 16 "Above normal (moderately severe)" 15 "Above normal (least severe)" 14 "Special intstructions" 13 "Out of calibration" 12 "Bad intelligent device" 11 "Root cause not known" 10 "Abnormal rate of change" 9 "Abnormal update rate" 8 "Abnormal frequency" 7 "Mechanical system not responding" 6 "Current above normal" 5 "Current below normal" 4 "Voltage below normal" 3 "Voltage above normal" 2 "Data erratic" 1 "Below normal (most severe)" 0 "Above normal (most severe)" ;
VAL_ 2566750462 FlashRedStopLamp 3 "Unavailable / Do Not Flash" 2 "Reserved" 1 "Fast Flash" 0 "Slow Flash" ;
VAL_ 2566750462 FlashProtectLamp 3 "Unavailable / Do Not Flash" 2 "Reserved" 1 "Fast Flash" 0 "Slow Flash" ;
VAL_ 2566750462 FlashMalfuncIndicatorLamp 3 "Unavailable / Do Not Flash" 2 "Class C DTC  " 1 "Fast Flash" 0 "Slow Flash" ;
VAL_ 2566750462 FlashAmberWarningLamp 3 "Unavailable / Do Not Flash" 2 "Reserved" 1 "Fast Flash" 0 "Slow Flash" ;
VAL_ 2566750462 MalfunctionIndLampStatus 3 "Not available" 2 "Short MIL for WWH OBD" 1 "Lamp On" 0 "Lamp Off" ;
VAL_ 2566750462 AmberWarningLampStatus 3 "Not available" 2 "Reserved" 1 "Lamp On" 0 "Lamp Off" ;
VAL_ 2566750462 RedStopLampState 3 "Not available" 2 "Reserved" 1 "Lamp On" 0 "Lamp Off" ;
VAL_ 2566750462 ProtectLampStatus 0 "Lamp Off" 3 "Not available" 2 "Reserved" 1 "Lamp On" ;
VAL_ 2566750974 FMI5 24 "Assurance Data Error" 23 "Request DM60 for more info" 22 "Special Instructions #2 " 21 "Data drifted low" 20 "Data drifted high" 31 "Condition exists" 19 "Received network data in error" 18 "Below normal (moderately severe)" 17 "Below normal (least severe)" 16 "Above normal (moderately severe)" 15 "Above normal (least severe)" 14 "Special intstructions" 13 "Out of calibration" 12 "Bad intelligent device" 11 "Root cause not known" 10 "Abnormal rate of change" 9 "Abnormal update rate" 8 "Abnormal frequency" 7 "Mechanical system not responding" 6 "Current above normal" 5 "Current below normal" 4 "Voltage below normal" 3 "Voltage above normal" 2 "Data erratic" 1 "Below normal (most severe)" 0 "Above normal (most severe)" ;
VAL_ 2566750974 FMI4 24 "Assurance Data Error" 23 "Request DM60 for more info" 22 "Special Instructions #2 " 21 "Data drifted low" 20 "Data drifted high" 31 "Condition exists" 19 "Received network data in error" 18 "Below normal (moderately severe)" 17 "Below normal (least severe)" 16 "Above normal (moderately severe)" 15 "Above normal (least severe)" 14 "Special intstructions" 13 "Out of calibration" 12 "Bad intelligent device" 11 "Root cause not known" 10 "Abnormal rate of change" 9 "Abnormal update rate" 8 "Abnormal frequency" 7 "Mechanical system not responding" 6 "Current above normal" 5 "Current below normal" 4 "Voltage below normal" 3 "Voltage above normal" 2 "Data erratic" 1 "Below normal (most severe)" 0 "Above normal (most severe)" ;
VAL_ 2566750974 FMI3 24 "Assurance Data Error" 23 "Request DM60 for more info" 22 "Special Instructions #2 " 21 "Data drifted low" 20 "Data drifted high" 31 "Condition exists" 19 "Received network data in error" 18 "Below normal (moderately severe)" 17 "Below normal (least severe)" 16 "Above normal (moderately severe)" 15 "Above normal (least severe)" 14 "Special intstructions" 13 "Out of calibration" 12 "Bad intelligent device" 11 "Root cause not known" 10 "Abnormal rate of change" 9 "Abnormal update rate" 8 "Abnormal frequency" 7 "Mechanical system not responding" 6 "Current above normal" 5 "Current below normal" 4 "Voltage below normal" 3 "Voltage above normal" 2 "Data erratic" 1 "Below normal (most severe)" 0 "Above normal (most severe)" ;
VAL_ 2566750974 FMI2 24 "Assurance Data Error" 23 "Request DM60 for more info" 22 "Special Instructions #2 " 21 "Data drifted low" 20 "Data drifted high" 31 "Condition exists" 19 "Received network data in error" 18 "Below normal (moderately severe)" 17 "Below normal (least severe)" 16 "Above normal (moderately severe)" 15 "Above normal (least severe)" 14 "Special intstructions" 13 "Out of calibration" 12 "Bad intelligent device" 11 "Root cause not known" 10 "Abnormal rate of change" 9 "Abnormal update rate" 8 "Abnormal frequency" 7 "Mechanical system not responding" 6 "Current above normal" 5 "Current below normal" 4 "Voltage below normal" 3 "Voltage above normal" 2 "Data erratic" 1 "Below normal (most severe)" 0 "Above normal (most severe)" ;
VAL_ 2566750974 FMI1 24 "Assurance Data Error" 23 "Request DM60 for more info" 22 "Special Instructions #2 " 21 "Data drifted low" 20 "Data drifted high" 31 "Condition exists" 19 "Received network data in error" 18 "Below normal (moderately severe)" 17 "Below normal (least severe)" 16 "Above normal (moderately severe)" 15 "Above normal (least severe)" 14 "Special intstructions" 13 "Out of calibration" 12 "Bad intelligent device" 11 "Root cause not known" 10 "Abnormal rate of change" 9 "Abnormal update rate" 8 "Abnormal frequency" 7 "Mechanical system not responding" 6 "Current above normal" 5 "Current below normal" 4 "Voltage below normal" 3 "Voltage above normal" 2 "Data erratic" 1 "Below normal (most severe)" 0 "Above normal (most severe)" ;
VAL_ 2566750974 FlashRedStopLamp 3 "Unavailable / Do Not Flash" 2 "Reserved" 1 "Fast Flash" 0 "Slow Flash" ;
VAL_ 2566750974 FlashProtectLamp 3 "Unavailable / Do Not Flash" 2 "Reserved" 1 "Fast Flash" 0 "Slow Flash" ;
VAL_ 2566750974 FlashMalfuncIndicatorLamp 3 "Unavailable / Do Not Flash" 2 "Class C DTC  " 1 "Fast Flash" 0 "Slow Flash" ;
VAL_ 2566750974 FlashAmberWarningLamp 3 "Unavailable / Do Not Flash" 2 "Reserved" 1 "Fast Flash" 0 "Slow Flash" ;
VAL_ 2566750974 MalfunctionIndLampStatus 3 "Not available" 2 "Short MIL for WWH OBD" 1 "Lamp On" 0 "Lamp Off" ;
VAL_ 2566750974 AmberWarningLampStatus 3 "Not available" 2 "Reserved" 1 "Lamp On" 0 "Lamp Off" ;
VAL_ 2566750974 RedStopLampState 3 "Not available" 2 "Reserved" 1 "Lamp On" 0 "Lamp Off" ;
VAL_ 2566750974 ProtectLampStatus 0 "Lamp Off" 3 "Not available" 2 "Reserved" 1 "Lamp On" ;
VAL_ 2566764798 MisfireMonitoringComplete 1 "EnabledForCycle" 0 "DisabledForRestOfCycle" ;
VAL_ 2566764798 MisfireMonitoringEnabled 1 "EnabledForCycle" 0 "DisabledForRestOfCycle" ;
VAL_ 2566764798 FuelSystemMonitoringEnabled 1 "NotCompleteCycle" 0 "CompleteCycleOrNotSupported" ;
VAL_ 2566764798 ComprehensiveComptMonComplete 1 "NotCompleteCycle" 0 "CompleteCycleOrNotSupported" ;
VAL_ 2566764798 ComprehensiveCompMonEnabled 1 "NotCompleteCycle" 0 "CompleteCycleOrNotSupported" ;
VAL_ 2566764798 SecondAirSystemMonComplete 1 "EnabledForCycle" 0 "DisabledForRestOfCycle" ;
VAL_ 2566764798 SecondAirSystemMonEnabled 1 "EnabledForCycle" 0 "DisabledForRestOfCycle" ;
VAL_ 2566764798 OxygenSensorMonComplete 1 "EnabledForCycle" 0 "DisabledForRestOfCycle" ;
VAL_ 2566764798 OxygenSensorMonEnabled 1 "NotCompleteCycle" 0 "CompleteCycleOrNotSupported" ;
VAL_ 2566764798 OxygenSensorHeaterMonComplete 1 "EnabledForCycle" 0 "DisabledForRestOfCycle" ;
VAL_ 2566764798 OxygenSensorHeaterMonEnabled 1 "NotCompleteCycle" 0 "CompleteCycleOrNotSupported" ;
VAL_ 2566764798 HeatedCatalystMonComplete 1 "EnabledForCycle" 0 "DisabledForRestOfCycle" ;
VAL_ 2566764798 HeatedCatalystMonEnabled 1 "EnabledForCycle" 0 "DisabledForRestOfCycle" ;
VAL_ 2566764798 EvaporativeSystemMonComplete 1 "NotCompleteCycle" 0 "CompleteCycleOrNotSupported" ;
VAL_ 2566764798 EvaporativeSystemMonEnabled 1 "NotCompleteCycle" 0 "CompleteCycleOrNotSupported" ;
VAL_ 2566764798 EGRSystemMonitoringComplete 1 "NotCompleteCycle" 0 "CompleteCycleOrNotSupported" ;
VAL_ 2566764798 EGRSystemMonitoringEnabled 1 "EnabledForCycle" 0 "DisabledForRestOfCycle" ;
VAL_ 2566764798 ColdStartAidSystemMonComplete 1 "EnabledForCycle" 0 "DisabledForRestOfCycle" ;
VAL_ 2566764798 ColdStartAidSystemMonEnabled 1 "EnabledForCycle" 0 "DisabledForRestOfCycle" ;
VAL_ 2566764798 CatalystMonComplete 1 "NotCompleteCycle" 0 "CompleteCycleOrNotSupported" ;
VAL_ 2566764798 CatalystMonEnabled 1 "NotCompleteCycle" 0 "CompleteCycleOrNotSupported" ;
VAL_ 2566764798 ACSystemRefrigerantMonComplete 1 "NotCompleteCycle" 0 "CompleteCycleOrNotSupported" ;
VAL_ 2566764798 ACSystemRefrigerantMonEnabled 1 "NotCompleteCycle" 0 "CompleteCycleOrNotSupported" ;
VAL_ 2566764798 FuelSystemMonitoringComplete 1 "NotCompleteCycle" 0 "CompleteCycleOrNotSupported" ;
VAL_ 2566764542 FMI 24 "Assurance Data Error" 23 "Request DM60 for more info" 22 "Special Instructions #2 " 21 "Data drifted low" 20 "Data drifted high" 31 "Condition exists" 19 "Received network data in error" 18 "Below normal (moderately severe)" 17 "Below normal (least severe)" 16 "Above normal (moderately severe)" 15 "Above normal (least severe)" 14 "Special intstructions" 13 "Out of calibration" 12 "Bad intelligent device" 11 "Root cause not known" 10 "Abnormal rate of change" 9 "Abnormal update rate" 8 "Abnormal frequency" 7 "Mechanical system not responding" 6 "Current above normal" 5 "Current below normal" 4 "Voltage below normal" 3 "Voltage above normal" 2 "Data erratic" 1 "Below normal (most severe)" 0 "Above normal (most severe)" ;
VAL_ 2566764286 SPNSupportTypeSTR3 1 "Not Supported In Scaled Test Results" 0 "Supported In Scaled Test Results" ;
VAL_ 2566764286 SPNSupportTypeSTR2 1 "Not Supported In Scaled Test Results" 0 "Supported In Scaled Test Results" ;
VAL_ 2566764286 SPNSupportTypeEFF3 1 "Not Supported In Ex Freeze Frame" 0 "Supported In Ex Freeze Frame" ;
VAL_ 2566764286 SPNSupportTypeEFF2 1 "Not Supported In Ex Freeze Frame" 0 "Supported In Ex Freeze Frame" ;
VAL_ 2566764286 SPNSupportTypeDS3 1 "Not Supported In Data Stream" 0 "Supported In Data Stream" ;
VAL_ 2566764286 SPNSupportTypeDS2 1 "Not Supported In Data Stream" 0 "Supported In Data Stream" ;
VAL_ 2566764286 SPNSupportTypeSTR1 1 "Not Supported In Scaled Test Results" 0 "Supported In Scaled Test Results" ;
VAL_ 2566764286 SPNSupportTypeDS1 1 "Not Supported In Data Stream" 0 "Supported In Data Stream" ;
VAL_ 2566764286 SPNSupportTypeEFF1 1 "Not Supported In Ex Freeze Frame" 0 "Supported In Ex Freeze Frame" ;
VAL_ 2566764030 FMI5 24 "Assurance Data Error" 23 "Request DM60 for more info" 22 "Special Instructions #2 " 21 "Data drifted low" 20 "Data drifted high" 31 "Condition exists" 19 "Received network data in error" 18 "Below normal (moderately severe)" 17 "Below normal (least severe)" 16 "Above normal (moderately severe)" 15 "Above normal (least severe)" 14 "Special intstructions" 13 "Out of calibration" 12 "Bad intelligent device" 11 "Root cause not known" 10 "Abnormal rate of change" 9 "Abnormal update rate" 8 "Abnormal frequency" 7 "Mechanical system not responding" 6 "Current above normal" 5 "Current below normal" 4 "Voltage below normal" 3 "Voltage above normal" 2 "Data erratic" 1 "Below normal (most severe)" 0 "Above normal (most severe)" ;
VAL_ 2566764030 FMI4 24 "Assurance Data Error" 23 "Request DM60 for more info" 22 "Special Instructions #2 " 21 "Data drifted low" 20 "Data drifted high" 31 "Condition exists" 19 "Received network data in error" 18 "Below normal (moderately severe)" 17 "Below normal (least severe)" 16 "Above normal (moderately severe)" 15 "Above normal (least severe)" 14 "Special intstructions" 13 "Out of calibration" 12 "Bad intelligent device" 11 "Root cause not known" 10 "Abnormal rate of change" 9 "Abnormal update rate" 8 "Abnormal frequency" 7 "Mechanical system not responding" 6 "Current above normal" 5 "Current below normal" 4 "Voltage below normal" 3 "Voltage above normal" 2 "Data erratic" 1 "Below normal (most severe)" 0 "Above normal (most severe)" ;
VAL_ 2566764030 FMI3 24 "Assurance Data Error" 23 "Request DM60 for more info" 22 "Special Instructions #2 " 21 "Data drifted low" 20 "Data drifted high" 31 "Condition exists" 19 "Received network data in error" 18 "Below normal (moderately severe)" 17 "Below normal (least severe)" 16 "Above normal (moderately severe)" 15 "Above normal (least severe)" 14 "Special intstructions" 13 "Out of calibration" 12 "Bad intelligent device" 11 "Root cause not known" 10 "Abnormal rate of change" 9 "Abnormal update rate" 8 "Abnormal frequency" 7 "Mechanical system not responding" 6 "Current above normal" 5 "Current below normal" 4 "Voltage below normal" 3 "Voltage above normal" 2 "Data erratic" 1 "Below normal (most severe)" 0 "Above normal (most severe)" ;
VAL_ 2566764030 FMI2 24 "Assurance Data Error" 23 "Request DM60 for more info" 22 "Special Instructions #2 " 21 "Data drifted low" 20 "Data drifted high" 31 "Condition exists" 19 "Received network data in error" 18 "Below normal (moderately severe)" 17 "Below normal (least severe)" 16 "Above normal (moderately severe)" 15 "Above normal (least severe)" 14 "Special intstructions" 13 "Out of calibration" 12 "Bad intelligent device" 11 "Root cause not known" 10 "Abnormal rate of change" 9 "Abnormal update rate" 8 "Abnormal frequency" 7 "Mechanical system not responding" 6 "Current above normal" 5 "Current below normal" 4 "Voltage below normal" 3 "Voltage above normal" 2 "Data erratic" 1 "Below normal (most severe)" 0 "Above normal (most severe)" ;
VAL_ 2566764030 FMI1 24 "Assurance Data Error" 23 "Request DM60 for more info" 22 "Special Instructions #2 " 21 "Data drifted low" 20 "Data drifted high" 31 "Condition exists" 19 "Received network data in error" 18 "Below normal (moderately severe)" 17 "Below normal (least severe)" 16 "Above normal (moderately severe)" 15 "Above normal (least severe)" 14 "Special intstructions" 13 "Out of calibration" 12 "Bad intelligent device" 11 "Root cause not known" 10 "Abnormal rate of change" 9 "Abnormal update rate" 8 "Abnormal frequency" 7 "Mechanical system not responding" 6 "Current above normal" 5 "Current below normal" 4 "Voltage below normal" 3 "Voltage above normal" 2 "Data erratic" 1 "Below normal (most severe)" 0 "Above normal (most severe)" ;
VAL_ 2566764030 FlashRedStopLamp 3 "Unavailable / Do Not Flash" 2 "Reserved" 1 "Fast Flash" 0 "Slow Flash" ;
VAL_ 2566764030 FlashProtectLamp 3 "Unavailable / Do Not Flash" 2 "Reserved" 1 "Fast Flash" 0 "Slow Flash" ;
VAL_ 2566764030 FlashMalfuncIndicatorLamp 3 "Unavailable / Do Not Flash" 2 "Class C DTC  " 1 "Fast Flash" 0 "Slow Flash" ;
VAL_ 2566764030 FlashAmberWarningLamp 3 "Unavailable / Do Not Flash" 2 "Reserved" 1 "Fast Flash" 0 "Slow Flash" ;
VAL_ 2566764030 MalfunctionIndLampStatus 3 "Not available" 2 "Short MIL for WWH OBD" 1 "Lamp On" 0 "Lamp Off" ;
VAL_ 2566764030 AmberWarningLampStatus 3 "Not available" 2 "Reserved" 1 "Lamp On" 0 "Lamp Off" ;
VAL_ 2566764030 RedStopLampState 3 "Not available" 2 "Reserved" 1 "Lamp On" 0 "Lamp Off" ;
VAL_ 2566764030 ProtectLampStatus 0 "Lamp Off" 3 "Not available" 2 "Reserved" 1 "Lamp On" ;
VAL_ 2562981630 ControlByte 1 "Request to clear/reset previously active DTC" 0 "Reserved for SAE Assignment" 19 "NACK to clear/reset of active DTC" 18 "ACK to clear/reset of active DTC" 17 "Request to clear/reset active DTC" 3 "NACK to clear/reset of previously active DTC" 2 "ACK to clear/reset of previously active DTC" ;
VAL_ 2562981630 CtrlByteSpecificIndicator 0 "General Negative Acknowledge" 4 "DTC no longer active" 3 "DTC no longer previously active" 2 "DTC unknown/does not exist" 1 "Access Denied" ;
VAL_ 2562981630 FMI 24 "Assurance Data Error" 23 "Request DM60 for more info" 22 "Special Instructions #2 " 21 "Data drifted low" 20 "Data drifted high" 31 "Condition exists" 19 "Received network data in error" 18 "Below normal (moderately severe)" 17 "Below normal (least severe)" 16 "Above normal (moderately severe)" 15 "Above normal (least severe)" 14 "Special intstructions" 13 "Out of calibration" 12 "Bad intelligent device" 11 "Root cause not known" 10 "Abnormal rate of change" 9 "Abnormal update rate" 8 "Abnormal frequency" 7 "Mechanical system not responding" 6 "Current above normal" 5 "Current below normal" 4 "Voltage below normal" 3 "Voltage above normal" 2 "Data erratic" 1 "Below normal (most severe)" 0 "Above normal (most severe)" ;
VAL_ 2564095742 SecurityEntityType 3 "Data is Certificate" 2 "Data is Session Key" 1 "Data is Long Key" 0 "Data is Long Seed" ;
VAL_ 2564357886 Seed 255 "NoFurtherKeyRequiredOfTool" 1 "UseLongSeedOrKeyFromDataSecMsg" 0 "SeedCompleted_BeginSendingKey" ;
VAL_ 2564357886 EDCP_Extension 9 "DataInErrIndAndDataInSeedIsTime" 6 "DataInErrorIndicator" 3 "ConcatenateDataAsLowerEDCParam" 2 "ConcatenateDataAsHigherEDCParam" 0 "Completed" 255 "NoErrIndicator/EDCParamAvailable" ;
VAL_ 2564357886 ErrorIndicator 16777215 "NoErrorIndicatorAvailable" 65540 "TransprtNotComplWithinTimeAllowd" 65539 "TransportNotInitWithinTimeAllowd" 65538 "NoResponseInTheTimeAllowed" 65537 "ModuleExceedingNumberOfRetries" 65536 "AbortFromExtToNormalSoftwareProc" 4103 "VehicleNotInParkOrNotStationary" 4102 "EngineRunning" 4101 "NotInEngineeringOrDevelopmentMode" 4100 "NotInDiagnosticMode" 4099 "InvalidKey" 4098 "InvalidUserLevel" 4097 "InvalidPassword" 4096 "SecurityErrorGeneral" 266 "NameDoesNotConformToExpectdValue" 265 "DataDoesNotConformToValueRanges" 264 "AddrForBootLoadExeInvalidBoundary" 263 "AddrForBootLoadExeOutsideExeMem" 262 "OpReqExeTransfAndEraseOfProgMem" 261 "OpRequiresPriorEraseOfProgramMem" 260 "OpRequiresPriorEraseOfDataMem" 259 "ReqMemoryExceededAvailableMemory" 258 "LengthNotValidForMemStructAndOp" 257 "AddressNotOnValidBoundary" 256 "AddressingOrDataGeneralError" 36 "InternalFailurePreventingReq" 35 "PROMDidNotVerifyOnWrite" 34 "FLASHDidNotVerifyOnWrite" 33 "RAMDidNotVerifyOnWrite" 32 "EDCParaNotCorrectForDataStream" 31 "ProcessUnspecReqFromThisAddress" 23 "ProcessingEDCPGenerationReq" 22 "ProcessingBootLoadReq" 19 "ProcessingStatusReq" 18 "ProcessingWriteReq" 17 "ProcessingReadReq" 16 "ProcessingEraseReq" 2 "ProcessingForSomeoneElse" 1 "ErrorNotIdentified" 0 "NoError" ;
VAL_ 2564357886 Status 7 "Reserved" 6 "Reserved" 5 "OperationFailed" 4 "OperationCompleted" 3 "Reserved" 2 "Reserved" 1 "Busy" 0 "Proceed" ;
VAL_ 2564423422 KeyOrUserLevel 65535 "NoKeyAvailable" 0 "UseLongSeedOrKey" ;
VAL_ 2564423422 PointerExtension 0 "SPN_SPACE" ;
VAL_ 2564423422 Command 7 "EDCP_Generation" 6 "BootLoad" 5 "OperationFailed" 4 "OperationCompleted" 3 "StatusRequest" 2 "Write" 1 "Read" 0 "Erase" ;
VAL_ 2564423422 PointerType 1 "DirectedSpatialAddressing" 0 "DirectMemoryAddressing" ;
VAL_ 2564816638 ProprietaryNetwork2 3 "Don’t Care/take no action" 2 "Reserved" 1 "Start Broadcast" 0 "Stop Broadcast" ;
VAL_ 2564816638 ProprietaryNetwork1 3 "Don’t Care/take no action" 2 "Reserved" 1 "Start Broadcast" 0 "Stop Broadcast" ;
VAL_ 2564816638 J1939Network4 3 "Don’t Care/take no action" 2 "Reserved" 1 "Start Broadcast" 0 "Stop Broadcast" ;
VAL_ 2564816638 HoldSignal 15 "Not Avai l abl e" 1 "Devices whose broadcast state has been modified" 0 "All Devices" ;
VAL_ 2564816638 J1939Network3 3 "Don’t Care/take no action" 2 "Reserved" 1 "Start Broadcast" 0 "Stop Broadcast" ;
VAL_ 2564816638 J1939Network2 3 "Don’t Care/take no action" 2 "Reserved" 1 "Start Broadcast" 0 "Stop Broadcast" ;
VAL_ 2564816638 ISO9141 3 "Don’t Care/take no action" 2 "Reserved" 1 "Start Broadcast" 0 "Stop Broadcast" ;
VAL_ 2564816638 SAE_J1850 3 "Don’t Care/take no action" 2 "Reserved" 1 "Start Broadcast" 0 "Stop Broadcast" ;
VAL_ 2564816638 ManufacturerSpecificPort 2 "Reserved" 1 "Start Broadcast" 0 "Stop Broadcast" 3 "Don’t Care/take no action" ;
VAL_ 2564816638 CurrentDataLink 3 "Don’t Care/take no action" 2 "Reserved" 1 "Start Broadcast" 0 "Stop Broadcast" ;
VAL_ 2564816638 SAE_J1587 3 "Don’t Care/take no action" 2 "Reserved" 1 "Start Broadcast" 0 "Stop Broadcast" ;
VAL_ 2564816638 SAE_J1922 3 "Don’t Care/take no action" 2 "Reserved" 1 "Start Broadcast" 0 "Stop Broadcast" ;
VAL_ 2564816638 J1939Network1 3 "Don’t Care/take no action" 2 "Reserved" 1 "Start Broadcast" 0 "Stop Broadcast" ;
VAL_ 2564816638 SuspendSignal 15 "Not Available" 14 "Resuming normal broadcast pattern" 3 "Temporary suspension of some messages" 2 "Temporary suspension of all broadcasts" 1 "Indefinite suspension of some messages" 0 "Indefinite suspension of all broadcasts" ;
VAL_ 2566837502 FMI5 24 "Assurance Data Error" 23 "Request DM60 for more info" 22 "Special Instructions #2 " 21 "Data drifted low" 20 "Data drifted high" 31 "Condition exists" 19 "Received network data in error" 18 "Below normal (moderately severe)" 17 "Below normal (least severe)" 16 "Above normal (moderately severe)" 15 "Above normal (least severe)" 14 "Special intstructions" 13 "Out of calibration" 12 "Bad intelligent device" 11 "Root cause not known" 10 "Abnormal rate of change" 9 "Abnormal update rate" 8 "Abnormal frequency" 7 "Mechanical system not responding" 6 "Current above normal" 5 "Current below normal" 4 "Voltage below normal" 3 "Voltage above normal" 2 "Data erratic" 1 "Below normal (most severe)" 0 "Above normal (most severe)" ;
VAL_ 2566837502 FMI4 24 "Assurance Data Error" 23 "Request DM60 for more info" 22 "Special Instructions #2 " 21 "Data drifted low" 20 "Data drifted high" 31 "Condition exists" 19 "Received network data in error" 18 "Below normal (moderately severe)" 17 "Below normal (least severe)" 16 "Above normal (moderately severe)" 15 "Above normal (least severe)" 14 "Special intstructions" 13 "Out of calibration" 12 "Bad intelligent device" 11 "Root cause not known" 10 "Abnormal rate of change" 9 "Abnormal update rate" 8 "Abnormal frequency" 7 "Mechanical system not responding" 6 "Current above normal" 5 "Current below normal" 4 "Voltage below normal" 3 "Voltage above normal" 2 "Data erratic" 1 "Below normal (most severe)" 0 "Above normal (most severe)" ;
VAL_ 2566837502 FMI3 24 "Assurance Data Error" 23 "Request DM60 for more info" 22 "Special Instructions #2 " 21 "Data drifted low" 20 "Data drifted high" 31 "Condition exists" 19 "Received network data in error" 18 "Below normal (moderately severe)" 17 "Below normal (least severe)" 16 "Above normal (moderately severe)" 15 "Above normal (least severe)" 14 "Special intstructions" 13 "Out of calibration" 12 "Bad intelligent device" 11 "Root cause not known" 10 "Abnormal rate of change" 9 "Abnormal update rate" 8 "Abnormal frequency" 7 "Mechanical system not responding" 6 "Current above normal" 5 "Current below normal" 4 "Voltage below normal" 3 "Voltage above normal" 2 "Data erratic" 1 "Below normal (most severe)" 0 "Above normal (most severe)" ;
VAL_ 2566837502 FMI2 24 "Assurance Data Error" 23 "Request DM60 for more info" 22 "Special Instructions #2 " 21 "Data drifted low" 20 "Data drifted high" 31 "Condition exists" 19 "Received network data in error" 18 "Below normal (moderately severe)" 17 "Below normal (least severe)" 16 "Above normal (moderately severe)" 15 "Above normal (least severe)" 14 "Special intstructions" 13 "Out of calibration" 12 "Bad intelligent device" 11 "Root cause not known" 10 "Abnormal rate of change" 9 "Abnormal update rate" 8 "Abnormal frequency" 7 "Mechanical system not responding" 6 "Current above normal" 5 "Current below normal" 4 "Voltage below normal" 3 "Voltage above normal" 2 "Data erratic" 1 "Below normal (most severe)" 0 "Above normal (most severe)" ;
VAL_ 2566837502 FMI1 24 "Assurance Data Error" 23 "Request DM60 for more info" 22 "Special Instructions #2 " 21 "Data drifted low" 20 "Data drifted high" 31 "Condition exists" 19 "Received network data in error" 18 "Below normal (moderately severe)" 17 "Below normal (least severe)" 16 "Above normal (moderately severe)" 15 "Above normal (least severe)" 14 "Special intstructions" 13 "Out of calibration" 12 "Bad intelligent device" 11 "Root cause not known" 10 "Abnormal rate of change" 9 "Abnormal update rate" 8 "Abnormal frequency" 7 "Mechanical system not responding" 6 "Current above normal" 5 "Current below normal" 4 "Voltage below normal" 3 "Voltage above normal" 2 "Data erratic" 1 "Below normal (most severe)" 0 "Above normal (most severe)" ;
VAL_ 2566837502 FlashRedStopLamp 3 "Unavailable / Do Not Flash" 2 "Reserved" 1 "Fast Flash" 0 "Slow Flash" ;
VAL_ 2566837502 FlashProtectLamp 3 "Unavailable / Do Not Flash" 2 "Reserved" 1 "Fast Flash" 0 "Slow Flash" ;
VAL_ 2566837502 FlashMalfuncIndicatorLamp 3 "Unavailable / Do Not Flash" 2 "Class C DTC  " 1 "Fast Flash" 0 "Slow Flash" ;
VAL_ 2566837502 FlashAmberWarningLamp 3 "Unavailable / Do Not Flash" 2 "Reserved" 1 "Fast Flash" 0 "Slow Flash" ;
VAL_ 2566837502 MalfunctionIndLampStatus 3 "Not available" 2 "Short MIL for WWH OBD" 1 "Lamp On" 0 "Lamp Off" ;
VAL_ 2566837502 AmberWarningLampStatus 3 "Not available" 2 "Reserved" 1 "Lamp On" 0 "Lamp Off" ;
VAL_ 2566837502 RedStopLampState 3 "Not available" 2 "Reserved" 1 "Lamp On" 0 "Lamp Off" ;
VAL_ 2566837502 ProtectLampStatus 0 "Lamp Off" 3 "Not available" 2 "Reserved" 1 "Lamp On" ;
VAL_ 2566836478 TestIdentifier 248 "Command manufacturer specific test " 246 "Return all scaled test results for all SPNs" 245 "Return rationality fault SP data value " 250 "Return last measured scaled results" 249 "Command Standard Test" 247 "Return all scaled test results for one SPN" ;
VAL_ 2565078782 TestIdentifier 248 "Command manufacturer specific test " 246 "Return all scaled test results for all SPNs" 245 "Return rationality fault SP data value " 250 "Return last measured scaled results" 249 "Command Standard Test" 247 "Return all scaled test results for one SPN" ;
VAL_ 2565078782 FMI 24 "Assurance Data Error" 23 "Request DM60 for more info" 22 "Special Instructions #2 " 21 "Data drifted low" 20 "Data drifted high" 31 "Condition exists" 19 "Received network data in error" 18 "Below normal (moderately severe)" 17 "Below normal (least severe)" 16 "Above normal (moderately severe)" 15 "Above normal (least severe)" 14 "Special intstructions" 13 "Out of calibration" 12 "Bad intelligent device" 11 "Root cause not known" 10 "Abnormal rate of change" 9 "Abnormal update rate" 8 "Abnormal frequency" 7 "Mechanical system not responding" 6 "Current above normal" 5 "Current below normal" 4 "Voltage below normal" 3 "Voltage above normal" 2 "Data erratic" 1 "Below normal (most severe)" 0 "Above normal (most severe)" ;

SG_MUL_VAL_ 2562981630 CtrlByteSpecificIndicator ControlByte 3-3, 19-19;
